VERSION ""

NS_ :

BS_:

BU_: WPC2 PSB SHVU_RR vHS_B2 FCS EMCU SLB GW_APSU GW_DLBCU RCM ARS CGW_CCU vDummy_HS_B GW_RLPSU ATS RLHV SGU PFSU GW_RRPSU ALBCU DSAU SWRC SHVU_FR RCS GW_DPSU BLTN_CAM SCM OHCL RWPC RRHV WPC HOD ASAU

BO_ 1096 SWRC_01_200ms: 8 SWRC
 SG_ SWRC_Crc1Val : 0|8@1+ (1,0) [0|0] ""  Vector__XXX
 SG_ SWRC_AlvCnt1Val : 12|4@1+ (1,0) [0|0] ""  CGW_CCU
 SG_ Audio_VcRecSwSta : 16|2@1+ (1,0) [0|0] ""  CGW_CCU
 SG_ Audio_BluetoothPhnClSwSta : 18|2@1+ (1,0) [0|0] ""  CGW_CCU
 SG_ Audio_BluetoothPhnHangUpSwSta : 20|2@1+ (1,0) [0|0] ""  CGW_CCU
 SG_ Audio_ModSwSta : 22|2@1+ (1,0) [0|0] ""  CGW_CCU
 SG_ Audio_MutSwSta : 24|2@1+ (1,0) [0|0] ""  CGW_CCU
 SG_ Audio_SeekDnSwSta : 26|2@1+ (1,0) [0|0] ""  CGW_CCU
 SG_ Audio_SeekUpSwSta : 28|2@1+ (1,0) [0|0] ""  CGW_CCU
 SG_ Audio_VolDnSwSta : 30|2@1+ (1,0) [0|0] ""  CGW_CCU
 SG_ Audio_VolUpSwSta : 32|2@1+ (1,0) [0|0] ""  CGW_CCU
 SG_ Cluster_ModeSwSta : 34|2@1+ (1,0) [0|0] ""  CGW_CCU
 SG_ Cluster_ScrlOkSwSta : 38|2@1+ (1,0) [0|0] ""  CGW_CCU
 SG_ Audio_CustomSwSta : 44|2@1+ (1,0) [0|0] ""  CGW_CCU
 SG_ Cluster_ModeCCW : 46|2@1+ (1,0) [0|0] ""  CGW_CCU
 SG_ Cluster_TripDnSwSta : 48|2@1+ (1,0) [0|0] ""  CGW_CCU
 SG_ Cluster_TripUpSwSta : 50|2@1+ (1,0) [0|0] ""  CGW_CCU
 SG_ Cluster_TripOkSwSta : 52|2@1+ (1,0) [0|0] ""  CGW_CCU
 SG_ SWRC_OpticalSwSnstvtSta : 54|2@1+ (1,0) [0|0] ""  CGW_CCU
 SG_ SWRC_RhOpticalSwSta : 56|4@1+ (1,0) [0|0] ""  CGW_CCU
 SG_ Audio_CustomSw3Sta : 8|2@1+ (1,0) [0|0] ""  CGW_CCU

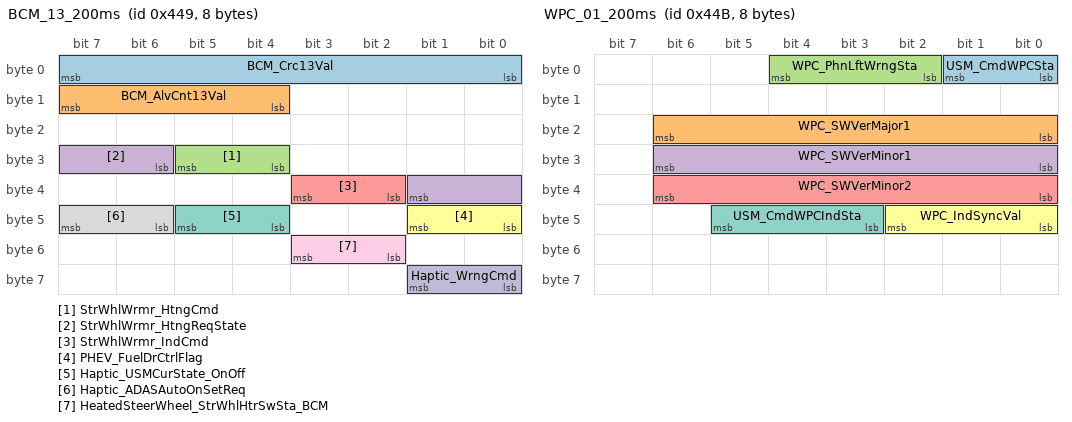
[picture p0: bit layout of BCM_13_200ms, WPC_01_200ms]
BO_ 1097 BCM_13_200ms: 8 CGW_CCU
 SG_ BCM_Crc13Val : 0|8@1+ (1,0) [0|0] ""  Vector__XXX
 SG_ BCM_AlvCnt13Val : 12|4@1+ (1,0) [0|0] ""  Vector__XXX
 SG_ StrWhlWrmr_HtngCmd : 28|2@1+ (1,0) [0|0] ""  Vector__XXX
 SG_ StrWhlWrmr_HtngReqState : 30|4@1+ (1,0) [0|0] ""  FCS
 SG_ StrWhlWrmr_IndCmd : 34|2@1+ (1,0) [0|0] ""  FCS
 SG_ PHEV_FuelDrCtrlFlag : 40|2@1+ (1,0) [0|0] ""  Vector__XXX
 SG_ Haptic_USMCurState_OnOff : 44|2@1+ (1,0) [0|0] ""  Vector__XXX
 SG_ Haptic_ADASAutoOnSetReq : 46|2@1+ (1,0) [0|0] ""  Vector__XXX
 SG_ HeatedSteerWheel_StrWhlHtrSwSta_BCM : 50|2@1+ (1,0) [0|0] ""  Vector__XXX
 SG_ Haptic_WrngCmd : 56|2@1+ (1,0) [0|0] ""  Vector__XXX

BO_ 1099 WPC_01_200ms: 8 WPC
 SG_ USM_CmdWPCSta : 0|2@1+ (1,0) [0|0] ""  CGW_CCU
 SG_ WPC_SWVerMajor1 : 16|7@1+ (1,0) [0|0] ""  CGW_CCU
 SG_ WPC_PhnLftWrngSta : 2|3@1+ (1,0) [0|0] ""  CGW_CCU
 SG_ WPC_SWVerMinor1 : 24|7@1+ (1,0) [0|0] ""  CGW_CCU
 SG_ WPC_SWVerMinor2 : 32|7@1+ (1,0) [0|0] ""  CGW_CCU
 SG_ WPC_IndSyncVal : 40|3@1+ (1,0) [0|0] ""  RWPC,WPC2
 SG_ USM_CmdWPCIndSta : 43|3@1+ (1,0) [0|0] ""  CGW_CCU,RWPC,WPC2

BO_ 1092 SMK_02_200ms: 8 CGW_CCU
 SG_ SMK_Crc2Val : 0|8@1+ (1,0) [0|0] ""  Vector__XXX
 SG_ SMK_AlvCnt2Val : 12|4@1+ (1,0) [0|0] ""  Vector__XXX
 SG_ SSB_StrtStpBtnSw1Sta : 16|2@1+ (1,0) [0|0] ""  Vector__XXX
 SG_ SSB_StrtStpBtnSw2Sta : 18|2@1+ (1,0) [0|0] ""  Vector__XXX
 SG_ SMK_TrmnlCtrlSta : 20|4@1+ (1,0) [0|0] ""  Vector__XXX
 SG_ SMK_AuthSta : 29|3@1+ (1,0) [0|0] ""  GW_APSU,GW_DPSU
 SG_ SMK_Ign1InSta : 32|2@1+ (1,0) [0|0] ""  Vector__XXX
 SG_ SMK_Ign1RlySta : 34|2@1+ (1,0) [0|0] ""  Vector__XXX
 SG_ SMK_Ign2InSta : 36|2@1+ (1,0) [0|0] ""  Vector__XXX
 SG_ SMK_Ign2RlySta : 38|2@1+ (1,0) [0|0] ""  Vector__XXX
 SG_ SMK_StrtFdbckSta : 40|2@1+ (1,0) [0|0] ""  Vector__XXX
 SG_ SMK_StrtrRlyOutSta : 42|2@1+ (1,0) [0|0] ""  Vector__XXX
 SG_ SMK_AccInSta : 44|2@1+ (1,0) [0|0] ""  Vector__XXX
 SG_ SMK_AccRlySta : 46|2@1+ (1,0) [0|0] ""  Vector__XXX
 SG_ SMK_CLUAccIndOnReq : 48|2@1+ (1,0) [0|0] ""  Vector__XXX
 SG_ SMK_VDModeActSta : 52|2@1+ (1,0) [0|0] ""  Vector__XXX
 SG_ SMK_SCULckUnlckSta : 54|2@1+ (1,0) [0|0] ""  Vector__XXX
 SG_ SMK_TlEngRunSta : 56|2@1+ (1,0) [0|0] ""  ASAU,ATS,DSAU,GW_APSU,GW_DPSU,RLHV,RRHV,SHVU_FR,SHVU_RR
 SG_ SMK_TlCrnkModSta : 58|2@1+ (1,0) [0|0] ""  ASAU,ATS,DSAU,GW_APSU,GW_DPSU,SCM
 SG_ SMK_RmtKeyEngRunSta : 60|2@1+ (1,0) [0|0] ""  Vector__XXX
 SG_ SMK_RmtKeyCrnkModSta : 62|2@1+ (1,0) [0|0] ""  Vector__XXX

BO_ 1093 SMK_06_200ms: 8 CGW_CCU
 SG_ SMK_Crc6Val : 0|8@1+ (1,0) [0|0] ""  Vector__XXX
 SG_ SMK_AlvCnt6Val : 12|4@1+ (1,0) [0|0] ""  Vector__XXX
 SG_ Lamp_HzrdBlnkngSta : 16|3@1+ (1,0) [0|0] ""  Vector__XXX
 SG_ RSPA_LearntSta : 19|2@1+ (1,0) [0|0] ""  Vector__XXX
 SG_ Lamp_SmrtWlcmLtOnReq : 21|2@1+ (1,0) [0|0] ""  Vector__XXX
 SG_ Fob_BattStaInfo : 24|2@1+ (1,0) [0|0] ""  Vector__XXX
 SG_ Fob_FoundDrvWlcmArea : 26|2@1+ (1,0) [0|0] ""  Vector__XXX
 SG_ Fob_FoundAsstWlcmArea : 28|2@1+ (1,0) [0|0] ""  Vector__XXX
 SG_ Fob_FoundExtrnlArea : 30|2@1+ (1,0) [0|0] ""  Vector__XXX
 SG_ Fob_FoundIntArea : 32|2@1+ (1,0) [0|0] ""  Vector__XXX
 SG_ Fob_LearntSta : 34|2@1+ (1,0) [0|0] ""  Vector__XXX
 SG_ RSPA_RFSigErrSta : 36|2@1+ (1,0) [0|0] ""  Vector__XXX
 SG_ RSPA_CanErrSta : 38|2@1+ (1,0) [0|0] ""  Vector__XXX
 SG_ LFAnt_FltSta : 40|2@1+ (1,0) [0|0] ""  Vector__XXX
 SG_ LFAnt_SrchSta : 42|2@1+ (1,0) [0|0] ""  RWPC,WPC,WPC2
 SG_ Auth_ISKLearnSta : 44|3@1+ (1,0) [0|0] ""  Vector__XXX
 SG_ RSPA_ModSta_SMK : 48|3@1+ (1,0) [0|0] ""  GW_DPSU
 SG_ RSPA_FobBattSta : 51|3@1+ (1,0) [0|0] ""  Vector__XXX
 SG_ Fob_BtnReleasedSta : 54|2@1+ (1,0) [0|0] ""  Vector__XXX
 SG_ USM_SmrtTrnkTlgtModSta : 56|3@1+ (1,0) [0|0] ""  Vector__XXX
 SG_ USM_WALModSta : 59|3@1+ (1,0) [0|0] ""  Vector__XXX
 SG_ Fob_FoundWlcmArea : 62|2@1+ (1,0) [0|0] ""  Vector__XXX

BO_ 1094 SLB_01_200ms: 8 SLB
 SG_ SLB_PlyBckSta : 0|2@1+ (1,0) [0|0] ""  Vector__XXX

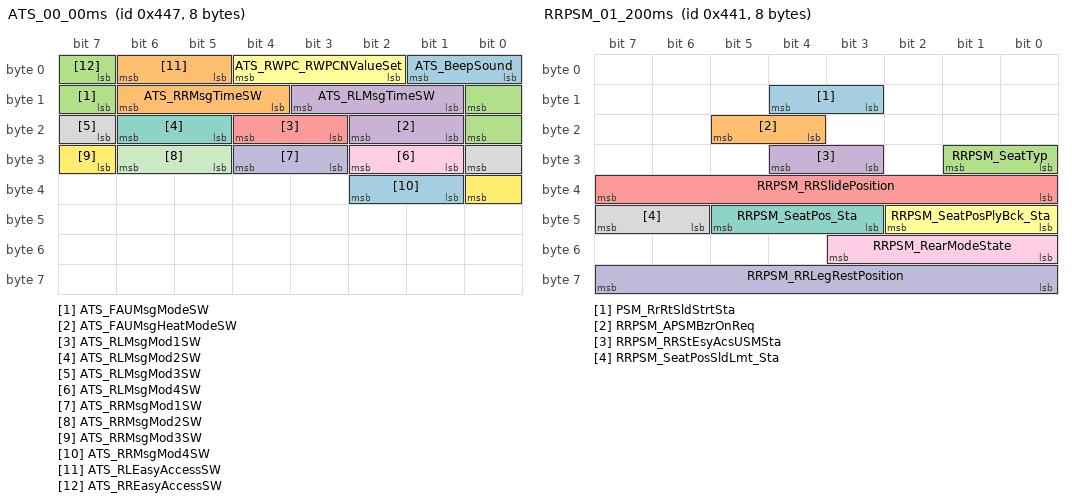
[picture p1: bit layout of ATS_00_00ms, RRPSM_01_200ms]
BO_ 1095 ATS_00_00ms: 8 ATS
 SG_ ATS_BeepSound : 0|2@1+ (1,0) [0|0] ""  CGW_CCU
 SG_ ATS_RRMsgTimeSW : 12|3@1+ (1,0) [0|0] ""  Vector__XXX
 SG_ ATS_FAUMsgModeSW : 15|2@1+ (1,0) [0|0] ""  ASAU
 SG_ ATS_FAUMsgHeatModeSW : 17|2@1+ (1,0) [0|0] ""  ASAU
 SG_ ATS_RLMsgMod1SW : 19|2@1+ (1,0) [0|0] ""  Vector__XXX
 SG_ ATS_RWPC_RWPCNValueSet : 2|3@1+ (1,0) [0|0] ""  RWPC
 SG_ ATS_RLMsgMod2SW : 21|2@1+ (1,0) [0|0] ""  Vector__XXX
 SG_ ATS_RLMsgMod3SW : 23|2@1+ (1,0) [0|0] ""  Vector__XXX
 SG_ ATS_RLMsgMod4SW : 25|2@1+ (1,0) [0|0] ""  Vector__XXX
 SG_ ATS_RRMsgMod1SW : 27|2@1+ (1,0) [0|0] ""  Vector__XXX
 SG_ ATS_RRMsgMod2SW : 29|2@1+ (1,0) [0|0] ""  Vector__XXX
 SG_ ATS_RRMsgMod3SW : 31|2@1+ (1,0) [0|0] ""  Vector__XXX
 SG_ ATS_RRMsgMod4SW : 33|2@1+ (1,0) [0|0] ""  Vector__XXX
 SG_ ATS_RLEasyAccessSW : 5|2@1+ (1,0) [0|0] ""  Vector__XXX
 SG_ ATS_RREasyAccessSW : 7|2@1+ (1,0) [0|0] ""  Vector__XXX
 SG_ ATS_RLMsgTimeSW : 9|3@1+ (1,0) [0|0] ""  Vector__XXX

BO_ 1089 RRPSM_01_200ms: 8 GW_RRPSU
 SG_ PSM_RrRtSldStrtSta : 11|2@1+ (1,0) [0|0] ""  ARS,GW_APSU,GW_DPSU,GW_RLPSU
 SG_ RRPSM_APSMBzrOnReq : 20|2@1+ (1,0) [0|0] ""  ATS,GW_APSU,GW_DPSU,GW_RLPSU
 SG_ RRPSM_SeatTyp : 24|2@1+ (1,0) [0|0] ""  GW_DPSU
 SG_ RRPSM_RRStEsyAcsUSMSta : 27|2@1+ (1,0) [0|0] ""  ATS,CGW_CCU,GW_DLBCU
 SG_ RRPSM_RRSlidePosition : 32|8@1+ (2,0) [0|0] ""  GW_APSU,GW_DPSU
 SG_ RRPSM_SeatPosPlyBck_Sta : 40|3@1+ (1,0) [0|0] ""  GW_RLPSU
 SG_ RRPSM_SeatPos_Sta : 43|3@1+ (1,0) [0|0] ""  GW_RLPSU
 SG_ RRPSM_SeatPosSldLmt_Sta : 46|2@1+ (1,0) [0|0] ""  CGW_CCU
 SG_ RRPSM_RearModeState : 48|4@1+ (1,0) [0|0] ""  ATS,CGW_CCU,GW_APSU,GW_DPSU,GW_RLPSU,OHCL
 SG_ RRPSM_RRLegRestPosition : 56|8@1+ (1,0) [0|0] ""  GW_APSU,GW_DPSU

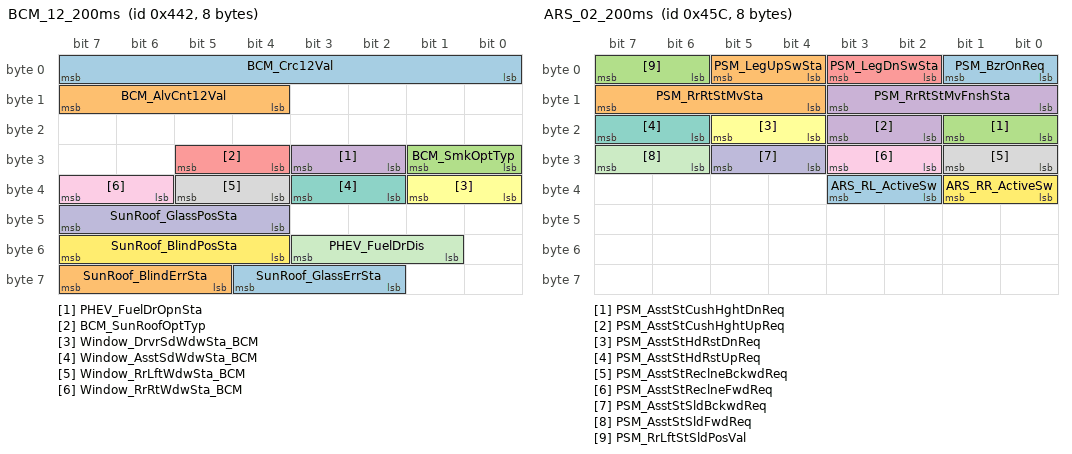
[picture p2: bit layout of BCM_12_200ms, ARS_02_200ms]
BO_ 1090 BCM_12_200ms: 8 CGW_CCU
 SG_ BCM_Crc12Val : 0|8@1+ (1,0) [0|0] ""  Vector__XXX
 SG_ BCM_AlvCnt12Val : 12|4@1+ (1,0) [0|0] ""  Vector__XXX
 SG_ BCM_SmkOptTyp : 24|2@1+ (1,0) [0|0] ""  RWPC,WPC,WPC2
 SG_ PHEV_FuelDrOpnSta : 26|2@1+ (1,0) [0|0] ""  Vector__XXX
 SG_ BCM_SunRoofOptTyp : 28|2@1+ (1,0) [0|0] ""  ATS
 SG_ Window_DrvrSdWdwSta_BCM : 32|2@1+ (1,0) [0|0] ""  Vector__XXX
 SG_ Window_AsstSdWdwSta_BCM : 34|2@1+ (1,0) [0|0] ""  Vector__XXX
 SG_ Window_RrLftWdwSta_BCM : 36|2@1+ (1,0) [0|0] ""  ATS
 SG_ Window_RrRtWdwSta_BCM : 38|2@1+ (1,0) [0|0] ""  ATS
 SG_ SunRoof_GlassPosSta : 44|4@1+ (1,0) [0|0] ""  Vector__XXX
 SG_ PHEV_FuelDrDis : 49|3@1+ (1,0) [0|0] ""  Vector__XXX
 SG_ SunRoof_BlindPosSta : 52|4@1+ (1,0) [0|0] ""  Vector__XXX
 SG_ SunRoof_GlassErrSta : 58|3@1+ (1,0) [0|0] ""  Vector__XXX
 SG_ SunRoof_BlindErrSta : 61|3@1+ (1,0) [0|0] ""  Vector__XXX

BO_ 1117 ARS_03_200ms: 8 ARS
 SG_ PSM_RrLftHdRstBckwdReq : 0|2@1+ (1,0) [0|0] ""  Vector__XXX
 SG_ PSM_RrLftStCushTiltUpReq : 10|2@1+ (1,0) [0|0] ""  Vector__XXX
 SG_ PSM_RrLftStShldrBckwdReq : 12|2@1+ (1,0) [0|0] ""  Vector__XXX
 SG_ PSM_RrLftStShldrFwdReq : 14|2@1+ (1,0) [0|0] ""  Vector__XXX
 SG_ PSM_RrLftStSldBckwdReq : 16|2@1+ (1,0) [0|0] ""  GW_RRPSU
 SG_ PSM_RrLftStSldFwdReq : 18|2@1+ (1,0) [0|0] ""  GW_RRPSU
 SG_ PSM_RrLftHdRstDnReq : 2|2@1+ (1,0) [0|0] ""  Vector__XXX
 SG_ PSM_RrRtStCushTiltDnReq : 20|2@1+ (1,0) [0|0] ""  Vector__XXX
 SG_ PSM_RrRtStCushTiltUpReq : 22|2@1+ (1,0) [0|0] ""  Vector__XXX
 SG_ PSM_RrRtStHdRstBckwdReq : 24|2@1+ (1,0) [0|0] ""  Vector__XXX
 SG_ PSM_RrRtStHdRstDnReq : 26|2@1+ (1,0) [0|0] ""  Vector__XXX
 SG_ PSM_RrRtStHdRstFwdReq : 28|2@1+ (1,0) [0|0] ""  Vector__XXX
 SG_ PSM_RrRtStHdRstUpReq : 30|2@1+ (1,0) [0|0] ""  Vector__XXX
 SG_ PSM_RrRtStLegSpprtBckwdReq : 32|2@1+ (1,0) [0|0] ""  Vector__XXX
 SG_ PSM_RrRtStLegSpprtDnReq : 34|2@1+ (1,0) [0|0] ""  Vector__XXX
 SG_ PSM_RrRtStLegSpprtFwdReq : 36|2@1+ (1,0) [0|0] ""  Vector__XXX
 SG_ PSM_RrRtStLegSpprtUpReq : 38|2@1+ (1,0) [0|0] ""  Vector__XXX
 SG_ PSM_RrLftHdRstFwdReq : 4|2@1+ (1,0) [0|0] ""  Vector__XXX
 SG_ PSM_RrRtStShldrBckwdReq : 40|2@1+ (1,0) [0|0] ""  Vector__XXX
 SG_ PSM_RrRtStShldrFwdReq : 42|2@1+ (1,0) [0|0] ""  Vector__XXX
 SG_ PSM_RrRtStSldBckwdReq : 44|2@1+ (1,0) [0|0] ""  GW_RRPSU
 SG_ PSM_RrRtStSldFwdReq : 46|2@1+ (1,0) [0|0] ""  GW_RRPSU
 SG_ PSM_StSldBckwdArsSta : 48|2@1+ (1,0) [0|0] ""  Vector__XXX
 SG_ PSM_StSldFwdArsSta : 50|2@1+ (1,0) [0|0] ""  Vector__XXX
 SG_ ARS_RrHeaterSW : 52|2@1+ (1,0) [0|0] ""  GW_RRPSU,RRHV
 SG_ ARS_RlHeaterSW : 54|2@1+ (1,0) [0|0] ""  GW_RLPSU,RLHV
 SG_ ARS_RrVentSW : 56|2@1+ (1,0) [0|0] ""  GW_RRPSU,RRHV
 SG_ ARS_RlVentSW : 58|2@1+ (1,0) [0|0] ""  GW_RLPSU,RLHV
 SG_ PSM_RrLftHdRstUpReq : 6|2@1+ (1,0) [0|0] ""  Vector__XXX
 SG_ PSM_RrLftStCushTiltDnReq : 8|2@1+ (1,0) [0|0] ""  Vector__XXX

BO_ 1116 ARS_02_200ms: 8 ARS
 SG_ PSM_BzrOnReq : 0|2@1+ (1,0) [0|0] ""  Vector__XXX
 SG_ PSM_RrRtStMvSta : 12|4@1+ (1,0) [0|0] ""  Vector__XXX
 SG_ PSM_AsstStCushHghtDnReq : 16|2@1+ (1,0) [0|0] ""  Vector__XXX
 SG_ PSM_AsstStCushHghtUpReq : 18|2@1+ (1,0) [0|0] ""  Vector__XXX
 SG_ PSM_LegDnSwSta : 2|2@1+ (1,0) [0|0] ""  Vector__XXX
 SG_ PSM_AsstStHdRstDnReq : 20|2@1+ (1,0) [0|0] ""  Vector__XXX
 SG_ PSM_AsstStHdRstUpReq : 22|2@1+ (1,0) [0|0] ""  Vector__XXX
 SG_ PSM_AsstStReclneBckwdReq : 24|2@1+ (1,0) [0|0] ""  Vector__XXX
 SG_ PSM_AsstStReclneFwdReq : 26|2@1+ (1,0) [0|0] ""  Vector__XXX
 SG_ PSM_AsstStSldBckwdReq : 28|2@1+ (1,0) [0|0] ""  Vector__XXX
 SG_ PSM_AsstStSldFwdReq : 30|2@1+ (1,0) [0|0] ""  Vector__XXX
 SG_ ARS_RR_ActiveSw : 32|2@1+ (1,0) [0|0] ""  GW_DLBCU
 SG_ ARS_RL_ActiveSw : 34|2@1+ (1,0) [0|0] ""  GW_DLBCU
 SG_ PSM_LegUpSwSta : 4|2@1+ (1,0) [0|0] ""  Vector__XXX
 SG_ PSM_RrLftStSldPosVal : 6|2@1+ (1,0) [0|0] ""  Vector__XXX
 SG_ PSM_RrRtStMvFnshSta : 8|4@1+ (1,0) [0|0] ""  Vector__XXX

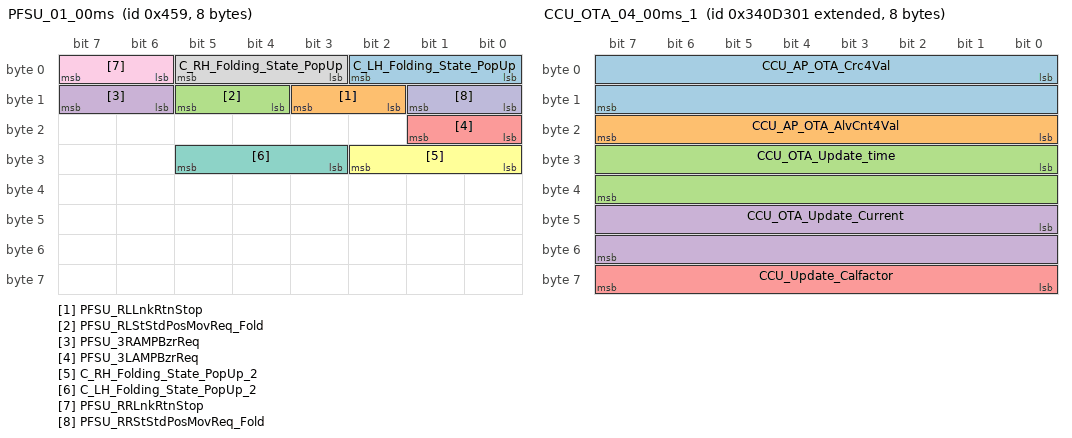
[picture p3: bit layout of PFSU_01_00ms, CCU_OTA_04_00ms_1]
BO_ 1113 PFSU_01_00ms: 8 PFSU
 SG_ C_LH_Folding_State_PopUp : 0|3@1+ (1,0) [0|0] ""  CGW_CCU,GW_APSU
 SG_ PFSU_RLLnkRtnStop : 10|2@1+ (1,0) [0|0] ""  GW_RLPSU
 SG_ PFSU_RLStStdPosMovReq_Fold : 12|2@1+ (1,0) [0|0] ""  GW_RLPSU
 SG_ PFSU_3RAMPBzrReq : 14|2@1+ (1,0) [0|0] ""  CGW_CCU
 SG_ PFSU_3LAMPBzrReq : 16|2@1+ (1,0) [0|0] ""  CGW_CCU
 SG_ C_RH_Folding_State_PopUp_2 : 24|3@1+ (1,0) [0|0] ""  CGW_CCU
 SG_ C_LH_Folding_State_PopUp_2 : 27|3@1+ (1,0) [0|0] ""  CGW_CCU
 SG_ C_RH_Folding_State_PopUp : 3|3@1+ (1,0) [0|0] ""  CGW_CCU,GW_APSU
 SG_ PFSU_RRLnkRtnStop : 6|2@1+ (1,0) [0|0] ""  GW_RRPSU
 SG_ PFSU_RRStStdPosMovReq_Fold : 8|2@1+ (1,0) [0|0] ""  GW_RRPSU

BO_ 2202063617 CCU_OTA_04_00ms_1: 8 CGW_CCU
 SG_ CCU_AP_OTA_Crc4Val : 0|16@1+ (1,0) [0|0] ""  vDummy_HS_B
 SG_ CCU_AP_OTA_AlvCnt4Val : 16|8@1+ (1,0) [0|0] ""  vDummy_HS_B
 SG_ CCU_OTA_Update_time : 24|16@1+ (1,0) [0|0] ""  Vector__XXX
 SG_ CCU_OTA_Update_Current : 40|16@1+ (1,0) [0|0] ""  Vector__XXX
 SG_ CCU_Update_Calfactor : 56|8@1+ (1,0) [0|0] ""  Vector__XXX

BO_ 1115 ARS_01_200ms: 8 ARS
 SG_ ARS_OnOffSta : 0|2@1+ (1,0) [0|0] ""  Vector__XXX
 SG_ ARS_RrCurtainSwSta : 10|2@1+ (1,0) [0|0] ""  CGW_CCU
 SG_ ARS_RrLftStRetModSwSta : 12|2@1+ (1,0) [0|0] ""  Vector__XXX
 SG_ ARS_RrLftStRlxModSwSta : 14|2@1+ (1,0) [0|0] ""  Vector__XXX
 SG_ ARS_RtMonModSwSta : 16|2@1+ (1,0) [0|0] ""  Vector__XXX
 SG_ ARS_RtReadModSwSta : 18|2@1+ (1,0) [0|0] ""  Vector__XXX
 SG_ ARS_ReclneBckwdSwSta : 2|2@1+ (1,0) [0|0] ""  Vector__XXX
 SG_ ARS_RtRetModSwSta : 20|2@1+ (1,0) [0|0] ""  Vector__XXX
 SG_ ARS_RtRlxModSwSta : 22|2@1+ (1,0) [0|0] ""  Vector__XXX
 SG_ ARS_SwLkSta : 24|2@1+ (1,0) [0|0] ""  CGW_CCU
 SG_ ARS_WalkInFrSwSta : 26|2@1+ (1,0) [0|0] ""  Vector__XXX
 SG_ ARS_WalkInRrSwSta : 28|2@1+ (1,0) [0|0] ""  Vector__XXX
 SG_ Lamp_RrRtPrsLmpReq : 30|2@1+ (1,0) [0|0] ""  Vector__XXX
 SG_ PSM_ApsmPlyBckRrerReq : 32|2@1+ (1,0) [0|0] ""  Vector__XXX
 SG_ ARS_ReclneFwdSwSta : 4|2@1+ (1,0) [0|0] ""  Vector__XXX
 SG_ ARS_RlxFrSwSta : 6|2@1+ (1,0) [0|0] ""  Vector__XXX
 SG_ ARS_RlxRrSwSta : 8|2@1+ (1,0) [0|0] ""  Vector__XXX

BO_ 1111 PFSU_02_200ms: 8 PFSU
 SG_ C_LH_Folding_Position : 0|3@1+ (1,0) [0|0] ""  CGW_CCU,GW_APSU,GW_RLPSU
 SG_ PFSU_RH_ReclMtrPos : 10|2@1+ (1,0) [0|0] ""  Vector__XXX
 SG_ PFSU_RL_Folding_SW : 16|2@1+ (1,0) [0|0] ""  GW_RLPSU
 SG_ PFSU_RR_Folding_SW : 18|2@1+ (1,0) [0|0] ""  GW_RLPSU,GW_RRPSU
 SG_ PFSU_RL_Unfolding_SW : 20|2@1+ (1,0) [0|0] ""  GW_RLPSU
 SG_ PFSU_RR_Unfolding_SW : 22|2@1+ (1,0) [0|0] ""  GW_RLPSU,GW_RRPSU
 SG_ C_RH_Folding_Position : 3|3@1+ (1,0) [0|0] ""  CGW_CCU,GW_APSU,GW_RLPSU,GW_RRPSU
 SG_ PFSU_RR_FoldingDis : 32|2@1+ (1,0) [0|0] ""  Vector__XXX
 SG_ PFSU_RR_UnfoldingDis : 34|2@1+ (1,0) [0|0] ""  Vector__XXX
 SG_ PFSU_RL_FoldingDis : 36|2@1+ (1,0) [0|0] ""  Vector__XXX
 SG_ PFSU_RL_UnfoldingDis : 38|2@1+ (1,0) [0|0] ""  Vector__XXX
 SG_ PFSU_RR_HrstFoldingDis : 40|2@1+ (1,0) [0|0] ""  CGW_CCU
 SG_ PFSU_RL_HrstFoldingDis : 42|2@1+ (1,0) [0|0] ""  CGW_CCU
 SG_ PFSU_RR_SlideFwdDis : 44|2@1+ (1,0) [0|0] ""  Vector__XXX
 SG_ PFSU_RR_SlidBwdDis : 46|2@1+ (1,0) [0|0] ""  Vector__XXX
 SG_ PFSU_RL_SlideFwdDis : 48|2@1+ (1,0) [0|0] ""  Vector__XXX
 SG_ PFSU_RL_SlideBwdDis : 50|2@1+ (1,0) [0|0] ""  Vector__XXX
 SG_ PFSU_RRAutoRlxEnable : 52|2@1+ (1,0) [0|0] ""  GW_RRPSU
 SG_ PFSU_Opt : 56|2@1+ (1,0) [0|0] ""  CGW_CCU
 SG_ PFSU_RLAutoRlxEnable : 60|2@1+ (1,0) [0|0] ""  GW_RLPSU
 SG_ PFSU_LH_ReclMtrPos : 8|2@1+ (1,0) [0|0] ""  Vector__XXX

BO_ 1105 FCS_01_200ms: 8 FCS
 SG_ FCS_FrLftStClrSwSta : 0|2@1+ (1,0) [0|0] ""  GW_APSU,SHVU_FR
 SG_ HeatedSteerWheel_SwSta : 10|2@1+ (1,0) [0|0] ""  CGW_CCU
 SG_ FCS_DrvDrAtClsSwSta : 12|2@1+ (1,0) [0|0] ""  CGW_CCU,SHVU_FR
 SG_ FCS_AstDrAtClsSwSta : 14|2@1+ (1,0) [0|0] ""  CGW_CCU,SHVU_FR
 SG_ FCS_DrvModeSwSta : 16|2@1+ (1,0) [0|0] ""  CGW_CCU,SHVU_FR
 SG_ FCS_PDWSwSta : 18|2@1+ (1,0) [0|0] ""  CGW_CCU
 SG_ FCS_FrLftStHtrSwSta : 2|2@1+ (1,0) [0|0] ""  GW_APSU,SHVU_FR
 SG_ FCS_Beep1Sound : 20|2@1+ (1,0) [0|0] ""  CGW_CCU
 SG_ FCS_LockTrayMsgDisp : 22|4@1+ (1,0) [0|0] ""  ATS
 SG_ FCS_LockTrayStatDisp : 26|3@1+ (1,0) [0|0] ""  ATS
 SG_ FCS_LockTrayPwNoDisp : 29|3@1+ (1,0) [0|0] ""  ATS
 SG_ FCS_LockTrayTxtPopupReq : 32|2@1+ (1,0) [0|0] ""  ATS
 SG_ FCS_LockTrayOSD : 34|3@1+ (1,0) [0|0] ""  ATS
 SG_ FCS_FrDrvArmrestHeatedLvl : 37|2@1+ (1,0) [0|0] ""  CGW_CCU
 SG_ FCS_FrAstArmrestHeatedLvl : 39|2@1+ (1,0) [0|0] ""  CGW_CCU
 SG_ FCS_FrRtStClrSwSta : 4|2@1+ (1,0) [0|0] ""  GW_APSU,SHVU_FR
 SG_ FCS_FrArmrestHeatedTyp : 41|2@1+ (1,0) [0|0] ""  CGW_CCU
 SG_ FCS_RrArmrestHeatedTyp : 43|2@1+ (1,0) [0|0] ""  CGW_CCU
 SG_ FCS_RrLhArmrestHeatedLvl : 45|2@1+ (1,0) [0|0] ""  CGW_CCU
 SG_ FCS_DrvTerrModeDirSwSta : 47|2@1+ (1,0) [0|0] ""  CGW_CCU
 SG_ FCS_DrvTerrModeSwSta : 49|2@1+ (1,0) [0|0] ""  CGW_CCU
 SG_ CF_FCS_4wdLocking : 51|2@1+ (1,0) [0|0] ""  CGW_CCU
 SG_ FCS_FrDrvArmrestHeated : 53|2@1+ (1,0) [0|0] ""  CGW_CCU
 SG_ FCS_FrAstArmrestHeated : 55|2@1+ (1,0) [0|0] ""  CGW_CCU
 SG_ FCS_RrLhArmrestHeated : 57|2@1+ (1,0) [0|0] ""  CGW_CCU
 SG_ FCS_RrRhArmrestHeated : 59|2@1+ (1,0) [0|0] ""  CGW_CCU
 SG_ FCS_FrRtStHtrSwSta : 6|2@1+ (1,0) [0|0] ""  GW_APSU,SHVU_FR
 SG_ FCS_RrRhArmrestHeatedLvl : 61|2@1+ (1,0) [0|0] ""  CGW_CCU
 SG_ FCS_RrCurtainSwSta : 8|2@1+ (1,0) [0|0] ""  Vector__XXX

BO_ 1107 RR_SHVU_01_200ms: 8 RRHV
 SG_ RR_SHVU_SeatOptSta : 0|3@1+ (1,0) [0|0] ""  ASAU,ATS,CGW_CCU
 SG_ RR_SHVU_SeatHtOperSta : 3|4@1+ (1,0) [0|0] ""  ASAU,ATS,CGW_CCU,FCS

BO_ 1134 APSU_03_200ms: 8 GW_APSU
 SG_ APSU_AstStSldFwdDis : 0|2@1+ (1,0) [0|0] ""  CGW_CCU
 SG_ APSU_AstStTiltDnDis : 10|2@1+ (1,0) [0|0] ""  CGW_CCU
 SG_ APSU_AstStHghtUpDis : 12|2@1+ (1,0) [0|0] ""  CGW_CCU
 SG_ APSU_AstStHghtDnDis : 14|2@1+ (1,0) [0|0] ""  CGW_CCU
 SG_ APSU_AstStLegUpDis : 16|2@1+ (1,0) [0|0] ""  Vector__XXX
 SG_ APSU_AstStLegtDnDis : 18|2@1+ (1,0) [0|0] ""  Vector__XXX
 SG_ APSU_AstStSldBckwdDis : 2|2@1+ (1,0) [0|0] ""  CGW_CCU
 SG_ APSU_AstStRlxTiltUpDis : 20|2@1+ (1,0) [0|0] ""  CGW_CCU
 SG_ APSU_AstStRlxTiltDnDis : 22|2@1+ (1,0) [0|0] ""  CGW_CCU
 SG_ APSU_AstStCushExtBckwdDis : 24|2@1+ (1,0) [0|0] ""  Vector__XXX
 SG_ APSU_AstStCushExtFwdDis : 26|2@1+ (1,0) [0|0] ""  Vector__XXX
 SG_ APSU_AstStLmbrDefDis : 32|2@1+ (1,0) [0|0] ""  ALBCU
 SG_ APSU_AstStLmbrLoDis : 34|2@1+ (1,0) [0|0] ""  ALBCU
 SG_ APSU_AstStLmbrMdlDis : 36|2@1+ (1,0) [0|0] ""  ALBCU
 SG_ APSU_AstStLmbrUpDis : 38|2@1+ (1,0) [0|0] ""  ALBCU
 SG_ APSU_AstStReclneFwdDis : 4|2@1+ (1,0) [0|0] ""  CGW_CCU
 SG_ APSU_LmbrSigSrcTyp : 44|2@1+ (1,0) [0|0] ""  ALBCU
 SG_ APSU_APSUOpt : 46|2@1+ (1,0) [0|0] ""  Vector__XXX
 SG_ APSU_AstStReclneBckwdDis : 6|2@1+ (1,0) [0|0] ""  CGW_CCU
 SG_ APSU_AstStTiltUpDis : 8|2@1+ (1,0) [0|0] ""  CGW_CCU

BO_ 1132 DLBCU_03_200ms: 8 GW_DLBCU
 SG_ DLBCU_CushInfDis : 0|2@1+ (1,0) [0|0] ""  CGW_CCU,GW_DPSU
 SG_ DLBCU_CushDefDis : 2|2@1+ (1,0) [0|0] ""  CGW_CCU,GW_DPSU

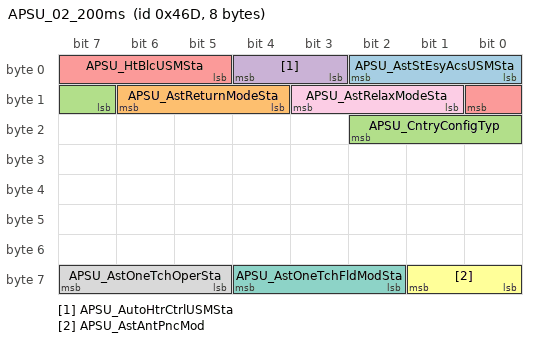
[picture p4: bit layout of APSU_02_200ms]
BO_ 1133 APSU_02_200ms: 8 GW_APSU
 SG_ APSU_AstStEsyAcsUSMSta : 0|3@1+ (1,0) [0|0] ""  ALBCU,CGW_CCU
 SG_ APSU_AstReturnModeSta : 12|3@1+ (1,0) [0|0] ""  CGW_CCU
 SG_ APSU_CntryConfigTyp : 15|4@1+ (1,0) [0|0] ""  Vector__XXX
 SG_ APSU_AutoHtrCtrlUSMSta : 3|2@1+ (1,0) [0|0] ""  Vector__XXX
 SG_ APSU_HtBlcUSMSta : 5|4@1+ (1,0) [0|0] ""  Vector__XXX
 SG_ APSU_AstAntPncMod : 56|2@1+ (1,0) [0|0] ""  Vector__XXX
 SG_ APSU_AstOneTchFldModSta : 58|3@1+ (1,0) [0|0] ""  Vector__XXX
 SG_ APSU_AstOneTchOperSta : 61|3@1+ (1,0) [0|0] ""  Vector__XXX
 SG_ APSU_AstRelaxModeSta : 9|3@1+ (1,0) [0|0] ""  CGW_CCU

BO_TX_BU_ 1107 : RRHV,SHVU_RR,GW_RRPSU,SHVU_FR;
CM_ BO_ 1133 "[PE] Periodic and On Event";
CM_ SG_ 1133 APSU_AstStEsyAcsUSMSta "USM_MovingValue";
CM_ SG_ 1133 APSU_CntryConfigTyp "APSU_ContryConfigurationType";
CM_ SG_ 1133 APSU_AutoHtrCtrlUSMSta "Auto Down Seat Heater (USM Setting)";
CM_ SG_ 1133 APSU_HtBlcUSMSta "Hetaer Balance Assistant USM R vaule";
CM_ BO_ 1134 "[PE] Periodic and On Event";
CM_ SG_ 1134 APSU_AstStSldFwdDis "APSU_AssistSlideForwardDisplay";
CM_ SG_ 1134 APSU_AstStTiltDnDis "APSU_AssistTiltDownSwitchDisplay";
CM_ SG_ 1134 APSU_AstStHghtUpDis "APSU_AssistHeightUpSwitchDisplay";
CM_ SG_ 1134 APSU_AstStHghtDnDis "APSU_AssistHeightDownSwitchDisplay";
CM_ SG_ 1134 APSU_AstStLegUpDis "APSU_AssistLegUpSwitchDisplay";
CM_ SG_ 1134 APSU_AstStLegtDnDis "APSU_AssistLegDownSwitchDisplay";
CM_ SG_ 1134 APSU_AstStSldBckwdDis "APSU_AssistSlideBackwardSwitchDisplay";
CM_ SG_ 1134 APSU_AstStRlxTiltUpDis "APSU_AssistRelaxTiltUpSwitchDisplay";
CM_ SG_ 1134 APSU_AstStRlxTiltDnDis "APSU_AssistRelaxTiltDownSwitchDisplay";
CM_ SG_ 1134 APSU_AstStCushExtBckwdDis "APSU_AssistCushionExtendedBackwardSwitchDisplay";
CM_ SG_ 1134 APSU_AstStCushExtFwdDis "APSU_AssistCushionExtendedForwardSwitchDisplay";
CM_ SG_ 1134 APSU_AstStLmbrDefDis "APSU_AssistLumbarDeFlateSwitchDisplay";
CM_ SG_ 1134 APSU_AstStLmbrLoDis "APSU_AssistLumbarLowSwitchDisplay";
CM_ SG_ 1134 APSU_AstStLmbrMdlDis "APSU_AssistLumbarMiddleSwitchDisplay";
CM_ SG_ 1134 APSU_AstStLmbrUpDis "APSU_AssistLumbarUpSwitchDisplay";
CM_ SG_ 1134 APSU_AstStReclneFwdDis "APSU_AssistSeatReclineForwardSwitchDisplay";
CM_ SG_ 1134 APSU_LmbrSigSrcTyp "Lumbar Switch Signal Source(TX)";
CM_ SG_ 1134 APSU_AstStReclneBckwdDis "APSU_AssistSeatReclineBackwardSwitchDisplay";
CM_ SG_ 1134 APSU_AstStTiltUpDis "APSU_AssistTiltUpSwitchDisplay";
CM_ BO_ 1115 "[PE] Periodic and On Event";
CM_ SG_ 1115 ARS_OnOffSta "ARS_OnOffStatus";
CM_ SG_ 1115 ARS_RrCurtainSwSta "ARS_RearCurtainSwitchArsStatus";
CM_ SG_ 1115 ARS_RrLftStRetModSwSta "ARS_RearLeftSeatReturnModeSwitchStatus";
CM_ SG_ 1115 ARS_RrLftStRlxModSwSta "ARS_RearLeftSeatRelaxModeSwitchStatus";
CM_ SG_ 1115 ARS_RtMonModSwSta "ARS_RightMonitorModeSwitchStatus";
CM_ SG_ 1115 ARS_RtReadModSwSta "ARS_RightReadingModeSwitchStatus";
CM_ SG_ 1115 ARS_ReclneBckwdSwSta "ARS_ReclineBackwardSwitchStatus";
CM_ SG_ 1115 ARS_RtRetModSwSta "ARS_RightReturnModeSwitchStatus";
CM_ SG_ 1115 ARS_RtRlxModSwSta "ARS_RightRelaxModeSwitchStatus";
CM_ SG_ 1115 ARS_SwLkSta "ARS_SwitchLockStatus";
CM_ SG_ 1115 ARS_WalkInFrSwSta "ARS_WalkInFrontSwitchStatus";
CM_ SG_ 1115 ARS_WalkInRrSwSta "ARS_WalkInRearSwitchStatus";
CM_ SG_ 1115 Lamp_RrRtPrsLmpReq "Lamp_RearRightPersonalLampRequest";
CM_ SG_ 1115 PSM_ApsmPlyBckRrerReq "PSM_ApsmPlayBackRrerRequest";
CM_ SG_ 1115 ARS_ReclneFwdSwSta "ARS_ReclineForwardSwitchStatus";
CM_ SG_ 1115 ARS_RlxFrSwSta "ARS_RelaxFrontSwitchStatus";
CM_ SG_ 1115 ARS_RlxRrSwSta "ARS_RelaxRearSwitchStatus";
CM_ BO_ 1116 "[PE] Periodic and On Event";
CM_ SG_ 1116 PSM_BzrOnReq "PSM_BuzzerOnRequest";
CM_ SG_ 1116 PSM_RrRtStMvSta "PSM_RearRightSeatMovingStatus";
CM_ SG_ 1116 PSM_AsstStCushHghtDnReq "PSM_AssistSeatCushionHeightDownRequest";
CM_ SG_ 1116 PSM_AsstStCushHghtUpReq "PSM_AssistSeatCushionHeightUpRequest";
CM_ SG_ 1116 PSM_LegDnSwSta "PSM_LegDownSwitchStatus";
CM_ SG_ 1116 PSM_AsstStHdRstDnReq "PSM_AssistSeatHeadrestSwitchDownRequest";
CM_ SG_ 1116 PSM_AsstStHdRstUpReq "PSM_AssistSeatHeadrestUpRequest";
CM_ SG_ 1116 PSM_AsstStReclneBckwdReq "PSM_AssistSeatReclineBackwardRequest";
CM_ SG_ 1116 PSM_AsstStReclneFwdReq "PSM_AssistSeatReclineForwardRequest";
CM_ SG_ 1116 PSM_AsstStSldBckwdReq "PSM_AssistSeatSlideBackwardRequest";
CM_ SG_ 1116 PSM_AsstStSldFwdReq "PSM_AssistSeatSlideForwardRequest";
CM_ SG_ 1116 ARS_RR_ActiveSw "ARS_RR_ActiveSw";
CM_ SG_ 1116 ARS_RL_ActiveSw "ARS_RL_ActiveSw";
CM_ SG_ 1116 PSM_LegUpSwSta "PSM_LegUpSwitchStatus";
CM_ SG_ 1116 PSM_RrLftStSldPosVal "PSM_RearLeftSeatSlidingPositionValue";
CM_ SG_ 1116 PSM_RrRtStMvFnshSta "PSM_RearRightSeatMovingFinishStatus";
CM_ BO_ 1117 "[PE] Periodic and On Event";
CM_ SG_ 1117 PSM_RrLftHdRstBckwdReq "PSM_RearLeftHeadrestBackwardRequest";
CM_ SG_ 1117 PSM_RrLftStCushTiltUpReq "PSM_RearLeftSeatCushionTiltUpRequest";
CM_ SG_ 1117 PSM_RrLftStShldrBckwdReq "PSM_RearLeftSeatShoulderBackwardRequest";
CM_ SG_ 1117 PSM_RrLftStShldrFwdReq "PSM_RearLeftSeatShoulderForwardRequest";
CM_ SG_ 1117 PSM_RrLftStSldBckwdReq "PSM_RearLeftSeatSliderBackwardRequest";
CM_ SG_ 1117 PSM_RrLftStSldFwdReq "PSM_RearLeftSeatSliderForwardRequest";
CM_ SG_ 1117 PSM_RrLftHdRstDnReq "PSM_RearLeftHeadrestDownRequest";
CM_ SG_ 1117 PSM_RrRtStCushTiltDnReq "PSM_RearRightSeatCushionTiltDownRequest";
CM_ SG_ 1117 PSM_RrRtStCushTiltUpReq "PSM_RearRightSeatCushionTiltUpRequest";
CM_ SG_ 1117 PSM_RrRtStHdRstBckwdReq "PSM_RearRightSeatHeadrestBackwardRequest";
CM_ SG_ 1117 PSM_RrRtStHdRstDnReq "PSM_RearRightSeatHeadrestDownRequest";
CM_ SG_ 1117 PSM_RrRtStHdRstFwdReq "PSM_RearRightSeatHeadrestForwardRequest";
CM_ SG_ 1117 PSM_RrRtStHdRstUpReq "PSM_RearRightSeatHeadrestUpRequest";
CM_ SG_ 1117 PSM_RrRtStLegSpprtBckwdReq "PSM_RearRightSeatLegSupportBackwardRequest";
CM_ SG_ 1117 PSM_RrRtStLegSpprtDnReq "PSM_RearRightSeatLegSupportDownRequest";
CM_ SG_ 1117 PSM_RrRtStLegSpprtFwdReq "PSM_RearRightSeatLegSupportForwardReqeust";
CM_ SG_ 1117 PSM_RrRtStLegSpprtUpReq "PSM_RearRightSeatLegSupportUpRequest";
CM_ SG_ 1117 PSM_RrLftHdRstFwdReq "PSM_RearLeftHeadrestForwardRequest";
CM_ SG_ 1117 PSM_RrRtStShldrBckwdReq "PSM_RearRightSeatShoulderBackwardRequest";
CM_ SG_ 1117 PSM_RrRtStShldrFwdReq "PSM_RearRightSeatShoulderForwardRequest";
CM_ SG_ 1117 PSM_RrRtStSldBckwdReq "PSM_RearRightSeatSlideBackwardRequest";
CM_ SG_ 1117 PSM_RrRtStSldFwdReq "PSM_RearRightSeatSlideForwardRequest";
CM_ SG_ 1117 PSM_StSldBckwdArsSta "PSM_SeatSlideBackwardArsStatus";
CM_ SG_ 1117 PSM_StSldFwdArsSta "PSM_SeatSlideForwardArsStatus";
CM_ SG_ 1117 ARS_RrHeaterSW "Rear Right Seat Heater Switch";
CM_ SG_ 1117 ARS_RlHeaterSW "Rear Left Seat Heater Switch";
CM_ SG_ 1117 ARS_RrVentSW "Rear Right Seat Vent Switch";
CM_ SG_ 1117 ARS_RlVentSW "Rear Left Seat Vent Switch";
CM_ SG_ 1117 PSM_RrLftHdRstUpReq "PSM_RearLeftHeadrestUpRequest";
CM_ SG_ 1117 PSM_RrLftStCushTiltDnReq "PSM_RearLeftSeatCushionTiltDownRequest";
CM_ BO_ 1095 "[EC] On Event and On Change";
CM_ SG_ 1095 ATS_BeepSound "ATS to AMP BEEP sound trigger";
CM_ SG_ 1095 ATS_RRMsgTimeSW "Rear Right Massage Time Button";
CM_ SG_ 1095 ATS_FAUMsgModeSW "Rear Right Foot Massage Mode Button";
CM_ SG_ 1095 ATS_FAUMsgHeatModeSW "Rear Right Foot Massage Heat Mode Button";
CM_ SG_ 1095 ATS_RLMsgMod1SW "Rear Left Massage Mode 1 Button";
CM_ SG_ 1095 ATS_RWPC_RWPCNValueSet "Rear Wireless Phone Charger ON/OFF Request";
CM_ SG_ 1095 ATS_RLMsgMod2SW "Rear Left Massage Mode 2 Button";
CM_ SG_ 1095 ATS_RLMsgMod3SW "Rear Left Massage Mode 3 Button";
CM_ SG_ 1095 ATS_RLMsgMod4SW "Rear Left Massage Mode 4 Button";
CM_ SG_ 1095 ATS_RRMsgMod1SW "Rear Right Massage Mode 1 Button";
CM_ SG_ 1095 ATS_RRMsgMod2SW "Rear Right Massage Mode 2 Button";
CM_ SG_ 1095 ATS_RRMsgMod3SW "Rear Right Massage Mode 3 Button";
CM_ SG_ 1095 ATS_RRMsgMod4SW "Rear Right Massage Mode 4 Button";
CM_ SG_ 1095 ATS_RLEasyAccessSW "ATS touch command for seat easy access (For Rear Left)";
CM_ SG_ 1095 ATS_RREasyAccessSW "ATS touch command for seat easy access (For Rear Right)";
CM_ SG_ 1095 ATS_RLMsgTimeSW "Rear Left Massage Time Button";
CM_ BO_ 1090 "[PE] Periodic and On Event";
CM_ SG_ 1090 BCM_Crc12Val "BCM_CyclicRedundancyCheck12Value";
CM_ SG_ 1090 BCM_AlvCnt12Val "BCM_AliveCounter12Value";
CM_ SG_ 1090 BCM_SmkOptTyp "BCM_SmkOptionType ##2G##BCM - BCMmsg17 - C_SMKOption";
CM_ SG_ 1090 PHEV_FuelDrOpnSta "PHEV_FuelDoorOpenStatus ##2G##BCM - BCMmsg20 - C_FuelDrSw";
CM_ SG_ 1090 BCM_SunRoofOptTyp "BCM_SunRoofOptionType";
CM_ SG_ 1090 Window_DrvrSdWdwSta_BCM "Window_DriverSideWindowStatus ##2G##BCM - BCMmsg22 - C_DrvWindowOpenState";
CM_ SG_ 1090 Window_AsstSdWdwSta_BCM "Window_AssistantSideWindowStatus ##2G##BCM - BCMmsg22 - C_AstWindowOpenState";
CM_ SG_ 1090 Window_RrLftWdwSta_BCM "Window_RearLeftWindowStatus ##2G##BCM - BCMmsg22 - C_RLWindowOpenState";
CM_ SG_ 1090 Window_RrRtWdwSta_BCM "Window_RearRightPowerWindowStatus ##2G##BCM - BCMmsg22 - C_RRWindowOpenState";
CM_ SG_ 1090 SunRoof_GlassPosSta "SunRoof_GlassPositionStatus";
CM_ SG_ 1090 PHEV_FuelDrDis "PHEV_FuelDoorDisplay ##2G##BCM - BCMmsg19 - C_PHEVFuelDrDisp";
CM_ SG_ 1090 SunRoof_BlindPosSta "SunRoof_BlindPositionStatus";
CM_ SG_ 1090 SunRoof_GlassErrSta "SunRoof_GlassErrorStatus";
CM_ SG_ 1090 SunRoof_BlindErrSta "SunRoof_BlindErrorStatus";
CM_ BO_ 1097 "[PE] Periodic and On Event";
CM_ SG_ 1097 BCM_Crc13Val "BCM_CyclicRedundancyCheck13Value";
CM_ SG_ 1097 BCM_AlvCnt13Val "BCM_AliveCounter13Value";
CM_ SG_ 1097 PHEV_FuelDrCtrlFlag "PHEV_FuelDoorOpenStatus ##2G##BCM - BCMmsg20 - C_FuelDrSw";
CM_ SG_ 1097 HeatedSteerWheel_StrWhlHtrSwSta_BCM "HeatedSteerWheel_SwitchStatus ##2G##BCM - BCMmsg24 - C_StrgWhlHeatedState";
CM_ BO_ 2202063617 "[EC] On Event and On Change";
CM_ SG_ 2202063617 CCU_AP_OTA_Crc4Val "CCU_AP_OTA_CyclicRedundancyCheck4Value";
CM_ SG_ 2202063617 CCU_AP_OTA_AlvCnt4Val "CCU_AP_OTA_AliveCounter4Value";
CM_ SG_ 2202063617 CCU_OTA_Update_time "¾÷µ¥ÀÌÆ® ¿¹»ó½Ã°£";
CM_ SG_ 2202063617 CCU_OTA_Update_Current "Current consumption expected";
CM_ SG_ 2202063617 CCU_Update_Calfactor "Determination SOC setting";
CM_ BO_ 1132 "[PE] Periodic and On Event";
CM_ SG_ 1132 DLBCU_CushInfDis "DLBCU_CushionInflationDisplay";
CM_ SG_ 1132 DLBCU_CushDefDis "DLBCU_CushionDeflationDisplay";
CM_ BO_ 1105 "[PE] Periodic and On Event";
CM_ SG_ 1105 FCS_FrLftStClrSwSta "FCS_FrontLeftSeatCoolerSwitchStatus";
CM_ SG_ 1105 HeatedSteerWheel_SwSta "HeatedSteerWheel_SwitchStatus";
CM_ SG_ 1105 FCS_FrLftStHtrSwSta "FCS_FrontLeftSeatHeaterSwitchStatus";
CM_ SG_ 1105 FCS_LockTrayMsgDisp "FCS_LockTrayMessageDisplacement";
CM_ SG_ 1105 FCS_LockTrayStatDisp "FCS_LockTrayStateDisplacement";
CM_ SG_ 1105 FCS_LockTrayPwNoDisp "FCS_LockTrayPasswordNumberDisplacement";
CM_ SG_ 1105 FCS_LockTrayTxtPopupReq "FCS_LockTrayTextPopupRequest";
CM_ SG_ 1105 FCS_LockTrayOSD "FCS_LockTrayOnScreenDisplacement";
CM_ SG_ 1105 FCS_FrRtStClrSwSta "FCS_FrontRightSeatCoolerSwitchStatus";
CM_ SG_ 1105 FCS_FrArmrestHeatedTyp "FCS_FrArmrestHeatedTyp";
CM_ SG_ 1105 FCS_RrArmrestHeatedTyp "FCS_RrArmrestHeatedTyp";
CM_ SG_ 1105 FCS_DrvTerrModeDirSwSta "Drive/Terrain mode switch transition direction signal";
CM_ SG_ 1105 FCS_DrvTerrModeSwSta "Drive/Terrain Mode Switch Convert Status";
CM_ SG_ 1105 CF_FCS_4wdLocking "4wd Locking On/Off Signal";
CM_ SG_ 1105 FCS_FrRtStHtrSwSta "FCS_FrontRightSeatHeaterSwitchStatus";
CM_ SG_ 1105 FCS_RrCurtainSwSta "FCS_RearCurtainSwitchFcsStatus";
CM_ BO_ 1113 "[EC] On Event and On Change";
CM_ SG_ 1113 C_LH_Folding_State_PopUp "3rd LH seat Moving Finish / Mode-Fail signal";
CM_ SG_ 1113 PFSU_3RAMPBzrReq "3rd Right SEAT IMS Buzzer Request for AMP or Inner Speaker";
CM_ SG_ 1113 PFSU_3LAMPBzrReq "3rd Left SEAT IMS Buzzer Request for AMP or Inner Speaker";
CM_ SG_ 1113 C_RH_Folding_State_PopUp_2 "AVNT OSD PopUp For 3rd Seat Inoperable condition";
CM_ SG_ 1113 C_LH_Folding_State_PopUp_2 "AVNT OSD PopUp For 3rd Seat Inoperable condition";
CM_ SG_ 1113 C_RH_Folding_State_PopUp "3rd RH seat Moving Finish / Mode-Fail signal";
CM_ BO_ 1111 "[PE] Periodic and On Event";
CM_ SG_ 1111 PFSU_RH_ReclMtrPos "PFSU Rear Right Recliner Motor Posion Information";
CM_ SG_ 1111 PFSU_RL_Folding_SW "PFSU Rear Left Folding Switch";
CM_ SG_ 1111 PFSU_RR_Folding_SW "PFSU Rear Right Folding Switch";
CM_ SG_ 1111 PFSU_RL_Unfolding_SW "PFSU Rear Left Unfolding Switch";
CM_ SG_ 1111 PFSU_RR_Unfolding_SW "PFSU Rear Right Unfolding Switch";
CM_ SG_ 1111 PFSU_RR_FoldingDis "Third LH PSU Folding moving state: Folding";
CM_ SG_ 1111 PFSU_RR_UnfoldingDis "Third LH PSU Unfolding moving state: Unfolding";
CM_ SG_ 1111 PFSU_RL_FoldingDis "Third RH PSU Folding moving state: Folding";
CM_ SG_ 1111 PFSU_RL_UnfoldingDis "Third RH PSU Unfolding moving state: Unfolding";
CM_ SG_ 1111 PFSU_RR_HrstFoldingDis "Third RH H/rest Folding moving state: H/rest folding";
CM_ SG_ 1111 PFSU_RL_HrstFoldingDis "Third LH H/rest Folding moving state: H/rest folding";
CM_ SG_ 1111 PFSU_RR_SlideFwdDis "Third LH PSU Recliner FWD moving state";
CM_ SG_ 1111 PFSU_RR_SlidBwdDis "Third LH PSU Recliner BWD moving state";
CM_ SG_ 1111 PFSU_RL_SlideFwdDis "Third RH PSU Recliner FWD moving state";
CM_ SG_ 1111 PFSU_RL_SlideBwdDis "Third RH PSU Recliner BWD moving state";
CM_ SG_ 1111 PFSU_Opt "PFSU Option Information";
CM_ SG_ 1111 PFSU_LH_ReclMtrPos "PFSU Rear Left Recliner Motor Posion Information";
CM_ BO_ 1089 "[PE] Periodic and On Event";
CM_ SG_ 1089 PSM_RrRtSldStrtSta "PSM_RearRightSlidingStartStatus";
CM_ SG_ 1089 RRPSM_APSMBzrOnReq "APSM buzzer on command";
CM_ SG_ 1089 RRPSM_RRStEsyAcsUSMSta "USM_MovingValue";
CM_ SG_ 1089 RRPSM_SeatPosPlyBck_Sta "RRPSM_SeatPositionPlayBack_State";
CM_ SG_ 1089 RRPSM_SeatPos_Sta "RRPSM_SeatPosition_State";
CM_ SG_ 1089 RRPSM_SeatPosSldLmt_Sta "RRPSM_SeatPositionSlideLimitState";
CM_ BO_ 1107 "[PE] Periodic and On Event";
CM_ SG_ 1107 RR_SHVU_SeatOptSta "Rear RH Seat Heater/Vent option info";
CM_ SG_ 1107 RR_SHVU_SeatHtOperSta "Rear RH Seat Heater/Vent current operation state";
CM_ BO_ 1094 "[PE] Periodic and On Event";
CM_ SG_ 1094 SLB_PlyBckSta "SLB_PlayBackStatus";
CM_ BO_ 1092 "[PE] Periodic and On Event";
CM_ SG_ 1092 SMK_Crc2Val "SMK_CyclicRedundancyCheck2Value";
CM_ SG_ 1092 SMK_AlvCnt2Val "SMK_AliveCounter2Value";
CM_ SG_ 1092 SSB_StrtStpBtnSw1Sta "SSB_StartStopButtonSwitch1Status ##2G##SMK - SMKmsg19 - C_SSBSW1";
CM_ SG_ 1092 SSB_StrtStpBtnSw2Sta "SSB_StartStopButtonSwitch2Status ##2G##SMK - SMKmsg19 - C_SSBSW2";
CM_ SG_ 1092 SMK_TrmnlCtrlSta "SMK_TerminalControlStatus ##2G##SMK - SMKmsg19 - C_TerminalControlState";
CM_ SG_ 1092 SMK_AuthSta "SMK_AuthentificationStatus ##2G##SMK - SMKmsg18 - C_AuthState";
CM_ SG_ 1092 SMK_Ign1InSta "SMK_Ign1InputStatus ##2G##SMK - SMKmsg19 - C_Ign1SMK";
CM_ SG_ 1092 SMK_Ign1RlySta "SMK_Ign1RelayStatus ##2G##SMK - SMKmsg19 - C_Ign1RelayState";
CM_ SG_ 1092 SMK_Ign2InSta "SMK_Ign2InputStatus ##2G##SMK - SMKmsg19 - C_Ign2SMK";
CM_ SG_ 1092 SMK_Ign2RlySta "SMK_Ign2RelayStatus ##2G##SMK - SMKmsg19 - C_Ign2RelayState";
CM_ SG_ 1092 SMK_StrtFdbckSta "SMK_StartFeedbackStatus ##2G##SMK - SMKmsg19 - C_StartFeedback";
CM_ SG_ 1092 SMK_StrtrRlyOutSta "SMK_StarterRelayOutputStatus ##2G##SMK - SMKmsg18 - C_StarterRlyState";
CM_ SG_ 1092 SMK_AccInSta "SMK_AccInputStatus ##2G##SMK - SMKmsg19 - C_AccSMK";
CM_ SG_ 1092 SMK_AccRlySta "SMK_AccRelayStatus ##2G##SMK - SMKmsg19 - C_AccRelayStatus";
CM_ SG_ 1092 SMK_CLUAccIndOnReq "SMK_ClusterACCIndicatorOnRequest ##2G##SMK - SMKmsg19 - C_AccINDforCLU";
CM_ SG_ 1092 SMK_VDModeActSta "SMK_VirtualDriverModeActState";
CM_ SG_ 1092 SMK_SCULckUnlckSta "SCU Lock/Unlock Status";
CM_ SG_ 1092 SMK_TlEngRunSta "SMK_TeleEngineRunStatus ##2G##SMK - SMKmsg18 - C_SMKTeleEngineRunning";
CM_ SG_ 1092 SMK_TlCrnkModSta "SMK_TeleCrankingModeStatus ##2G##SMK - SMKmsg18 - C_SMKTeleCrankingState";
CM_ SG_ 1092 SMK_RmtKeyEngRunSta "SMK_RemoteKeyEngineRunStatus";
CM_ SG_ 1092 SMK_RmtKeyCrnkModSta "SMK_RemoteKeyCrankingModeStatus";
CM_ BO_ 1093 "[PE] Periodic and On Event";
CM_ SG_ 1093 SMK_Crc6Val "SMK_CyclicRedundancyCheck6Value";
CM_ SG_ 1093 SMK_AlvCnt6Val "SMK_AliveCounter6Value";
CM_ SG_ 1093 Lamp_HzrdBlnkngSta "Lamp_HazardBlinkingStatus ##2G##SMK - SMKmsg17 - C_HazardFromSMK";
CM_ SG_ 1093 Lamp_SmrtWlcmLtOnReq "Lamp_SmartWelcomeLightOnRequest ##2G##SMK - SMKmsg17 - C_WlightOn";
CM_ SG_ 1093 Fob_BattStaInfo "Fob_BatteryStatusInformation ##2G##SMK - SMKmsg17 - C_FOBBatteryStatusInfo";
CM_ SG_ 1093 Fob_FoundDrvWlcmArea "Fob_FoundDriverWelcomeArea ##2G##SMK - SMKmsg17 - C_WelcomeFobFoundDrv";
CM_ SG_ 1093 Fob_FoundAsstWlcmArea "Fob_FoundAssistWelcomeArea ##2G##SMK - SMKmsg17 - C_WelcomeFobFoundAst";
CM_ SG_ 1093 Fob_FoundExtrnlArea "Fob_FoundExternalArea ##2G##SMK - SMKmsg18 - C_ExtFobPos";
CM_ SG_ 1093 Fob_FoundIntArea "Fob_FoundInternalArea ##2G##SMK - SMKmsg18 - C_IntFobPos";
CM_ SG_ 1093 Fob_LearntSta "Fob_LearntStatus ##2G##SMK - SMKmsg18 - C_FobLearntState";
CM_ SG_ 1093 RSPA_RFSigErrSta "RSPA_RFSignalErrorState";
CM_ SG_ 1093 RSPA_CanErrSta "RSPA_CANErrorState";
CM_ SG_ 1093 LFAnt_FltSta "LFAntenna_FaultSatus ##2G##SMK - SMKmsg18 - C_LFANTState";
CM_ SG_ 1093 LFAnt_SrchSta "LFAntenna_SearchingStatus ##2G##SMK - SMKmsg19 - C_LFSearchingOn";
CM_ SG_ 1093 Auth_ISKLearnSta "Fob_FoundAssistWelcomeArea ##2G##SMK - SMKmsg178 - C_IBUISKLearnState";
CM_ SG_ 1093 RSPA_ModSta_SMK "RSPA_ModeStatus ##2G##SMK - SMKmsg18 - C_SMKRSPAMode";
CM_ SG_ 1093 RSPA_FobBattSta "RSPA_FobBatteryStatus ##2G##SMK - SMKmsg18 - C_FobBATState";
CM_ SG_ 1093 USM_SmrtTrnkTlgtModSta "USM_SmartTunkTailgateModeStatus ##2G##SMK - SMKmsg20 - C_HfreeTrunkTgRValue";
CM_ SG_ 1093 USM_WALModSta "USM_WalkAwayLockModeStatus ##2G##SMK - SMKmsg20 - C_WALRValue";
CM_ SG_ 1093 Fob_FoundWlcmArea "Fob_FoundWlcmArea ##2G##SMK - SMKmsg17 -C_FobFoundWlcmArea";
CM_ BO_ 1096 "[PE] Periodic and On Event";
CM_ SG_ 1096 SWRC_Crc1Val "SWRC_CyclicRedundancyCheck1Value";
CM_ SG_ 1096 SWRC_AlvCnt1Val "SWRC_AliveCounter1Value";
CM_ SG_ 1096 Audio_VcRecSwSta "Audio_VoiceReconitionSwitchStatus";
CM_ SG_ 1096 Audio_BluetoothPhnClSwSta "Audio_BluetoothPhoneCallSwitchStatus";
CM_ SG_ 1096 Audio_BluetoothPhnHangUpSwSta "Audio_BluetoothPhoneHangUpSwitchStatus";
CM_ SG_ 1096 Audio_ModSwSta "Audio_ModeSwitchStatus";
CM_ SG_ 1096 Audio_MutSwSta "Audio_MuteSwitchStatus";
CM_ SG_ 1096 Audio_SeekDnSwSta "Audio_SeekDownSwitchStatus";
CM_ SG_ 1096 Audio_SeekUpSwSta "Audio_SeekUpSwitchStatus";
CM_ SG_ 1096 Audio_VolDnSwSta "Audio_VolumeDownSwitchStatus";
CM_ SG_ 1096 Audio_VolUpSwSta "Audio_VolumeUpSwitchStatus";
CM_ SG_ 1096 Cluster_ModeSwSta "Cluster_ModeSwitchStatus";
CM_ SG_ 1096 Cluster_ScrlOkSwSta "Cluster_ScrollOkSwitchStatus";
CM_ SG_ 1096 Audio_CustomSwSta "Audio_CustomSwitchStatus";
CM_ SG_ 1096 Cluster_ModeCCW "Cluster Menu Control (Back Key)";
CM_ SG_ 1096 Cluster_TripDnSwSta "Cluster_TripDnSwSta";
CM_ SG_ 1096 Cluster_TripUpSwSta "Cluster Menu Control (Up)";
CM_ SG_ 1096 Cluster_TripOkSwSta "Cluster_TripOkSwSta";
CM_ SG_ 1096 SWRC_OpticalSwSnstvtSta "SWRC_OpticalSwitchSensitivityStatus";
CM_ SG_ 1096 SWRC_RhOpticalSwSta "SWRC_RhOpticalSwitchStatus";
CM_ SG_ 1096 Audio_CustomSw3Sta "Audio_CustomSwitch 3rd Status";
CM_ BO_ 1099 "[PE] Periodic and On Event";
CM_ SG_ 1099 USM_CmdWPCSta "USM_CommandWPCStatus";
CM_ SG_ 1099 WPC_SWVerMajor1 "First Word(ASCII) in WPC S/W Ver";
CM_ SG_ 1099 WPC_PhnLftWrngSta "WPC_PhoneLeftWarningStatus";
CM_ SG_ 1099 WPC_SWVerMinor1 "Second Word(ASCII) in WPC S/W Ver";
CM_ SG_ 1099 WPC_SWVerMinor2 "Third Word(ASCII) in WPC S/W Ver";
BA_DEF_ BO_ "DiagState" ENUM "No","Yes" ;
BA_DEF_ BO_ "DiagResponse" ENUM "No","Yes" ;
BA_DEF_ BO_ "DiagRequest" ENUM "No","Yes" ;
BA_DEF_ BO_ "TpMessage" ENUM "No","Yes" ;
BA_DEF_ BO_ "UsrMsgIDSforwardDeviation" INT 0 100 ;
BA_DEF_ BO_ "UsrMsgIDSbackwardDeviation" INT 50 1000 ;
BA_DEF_ "BusType" STRING ;
BA_DEF_ "DBName" STRING ;
BA_DEF_ "Baudrate" INT 50000 1000000 ;
BA_DEF_ "GenEnvVarEndingDsp" STRING ;
BA_DEF_ "GenEnvVarEndingSnd" STRING ;
BA_DEF_ "GenEnvVarPrefix" STRING ;
BA_DEF_ "GenNWMApBusSleep" STRING ;
BA_DEF_ "GenNWMApCanNormal" STRING ;
BA_DEF_ "GenNWMApCanOff" STRING ;
BA_DEF_ "GenNWMApCanOn" STRING ;
BA_DEF_ "GenNWMApCanSleep" STRING ;
BA_DEF_ "GenNWMApCanWakeUp" STRING ;
BA_DEF_ "GenNWMGotoMode_Awake" STRING ;
BA_DEF_ "GenNWMGotoMode_BusSleep" STRING ;
BA_DEF_ "GenNWMSleepTime" INT 1375 1650 ;
BA_DEF_ "GenNWMTalkNM" STRING ;
BA_DEF_ "Manufacturer" STRING ;
BA_DEF_ "NmBaseAddress" HEX 0 2047 ;
BA_DEF_ "NmMessageCount" INT 0 128 ;
BA_DEF_ "NmType" STRING ;
BA_DEF_ "SamplePointMax" INT 50 85 ;
BA_DEF_ "SamplePointMin" INT 55 85 ;
BA_DEF_ "SyncJumpWidthMax" INT 1 8 ;
BA_DEF_ "SyncJumpWidthMin" INT 1 4 ;
BA_DEF_ "VersionDay" INT 1 31 ;
BA_DEF_ "VersionMonth" INT 1 12 ;
BA_DEF_ "VersionNumber" INT 0 999999 ;
BA_DEF_ "VersionNumberInternal" INT 0 9999 ;
BA_DEF_ "VersionWeek" INT 1 53 ;
BA_DEF_ "VersionYear" INT 0 9999 ;
BA_DEF_ BU_ "NmStationAddress" HEX 0 127 ;
BA_DEF_ BU_ "NmNode" ENUM "No","Yes" ;
BA_DEF_ BU_ "GenNodSleepTime" INT 1375 1650 ;
BA_DEF_ BU_ "ILUsed" ENUM "No","Yes" ;
BA_DEF_ BU_ "NmCAN" INT 1 2 ;
BA_DEF_ BU_ "NodeLayerModules" STRING ;
BA_DEF_ BU_ "NWM_Knoten" ENUM "No","Yes" ;
BA_DEF_ BO_ "GenMsgCycleTime" INT 0 2000 ;
BA_DEF_ BO_ "GenMsgStartDelayTime" INT 0 2000 ;
BA_DEF_ BO_ "GenMsgSendType" ENUM "Cyclic","NoMsgSendType" ;
BA_DEF_ BO_ "GenMsgCycleTimeFast" INT 0 500 ;
BA_DEF_ BO_ "GenMsgDelayTime" INT 0 20 ;
BA_DEF_ BO_ "GenMsgILSupport" ENUM "No","Yes" ;
BA_DEF_ BO_ "GenMsgNrOfRepetition" INT 0 3 ;
BA_DEF_ BO_ "NmMessage" ENUM "No","Yes" ;
BA_DEF_ BO_ "NWM-Botschaft" ENUM "No","Yes" ;
BA_DEF_ BO_ "TpTxIndex" INT 0 65535 ;
BA_DEF_ BO_ "VFrameFormat" ENUM "StandardCAN","ExtendedCAN","reserved","reserved","reserved","reserved","reserved","reserved","reserved","reserved","reserved","reserved","reserved","reserved","StandardCAN_FD","ExtendedCAN_FD" ;
BA_DEF_ SG_ "UserSigValidity" ENUM "B+","ACC","IG","IG1","IG2","IG3","IG1 or IG2","IG1 or IG3","Undef" ;
BA_DEF_ SG_ "TimeoutValue" STRING ;
BA_DEF_ SG_ "UsrSigPurpose" ENUM "Undef","FN","DIAG","DIAG(Req)","DIAG(Res)","DIAG(Phy)","DEV","CCP(Req)","CCP(Res)","NM","TP" ;
BA_DEF_ SG_ "GenSigStartValue" INT 0 1215752192 ;
BA_DEF_ SG_ "NetworkRequest" ENUM "Yes","No" ;
BA_DEF_ SG_ "NetworkRequestHoldingTime" INT 0 65535 ;
BA_DEF_ SG_ "Description" STRING ;
BA_DEF_ SG_ "Version" STRING ;
BA_DEF_ SG_ "GenSigEnvVarType" ENUM "Int","Float","Undef" ;
BA_DEF_ SG_ "GenSigSendType" ENUM "Cyclic","OnWrite","OnWriteWithRepetition","OnChange","OnChangeWithRepetition","IfActive","IfActiveWithRepetition","NoSigSendType","OnChangeAndIfActive","OnChangeAndIfActiveWithRepetition" ;
BA_DEF_ SG_ "GwSigLatencyTime" INT 0 65536 ;
BA_DEF_ SG_ "GwSigMissingSourceType" ENUM "Undef","OldValue","DefaultValue","InitialValue" ;
BA_DEF_ SG_ "NWM-WakeupAllowed" ENUM "<n.a.>" ;
BA_DEF_ SG_ "RoutingFactor" INT 1 1215752192 ;
BA_DEF_REL_ BU_SG_REL_ "GenSigTimeoutTime" INT 0 7000 ;
BA_DEF_DEF_ "DiagState" "No" ;
BA_DEF_DEF_ "DiagResponse" "No" ;
BA_DEF_DEF_ "DiagRequest" "No" ;
BA_DEF_DEF_ "TpMessage" "No" ;
BA_DEF_DEF_ "UsrMsgIDSforwardDeviation" 10 ;
BA_DEF_DEF_ "UsrMsgIDSbackwardDeviation" 100 ;
BA_DEF_DEF_ "BusType" "CAN" ;
BA_DEF_DEF_ "DBName" "" ;
BA_DEF_DEF_ "Baudrate" 500000 ;
BA_DEF_DEF_ "GenEnvVarEndingDsp" "Dsp_" ;
BA_DEF_DEF_ "GenEnvVarEndingSnd" "_" ;
BA_DEF_DEF_ "GenEnvVarPrefix" "Env" ;
BA_DEF_DEF_ "GenNWMApBusSleep" "AppNmCanBusSleep()" ;
BA_DEF_DEF_ "GenNWMApCanNormal" "AppNmCanNormal()" ;
BA_DEF_DEF_ "GenNWMApCanOff" "ApplCanOffline()" ;
BA_DEF_DEF_ "GenNWMApCanOn" "ApplCanOnline()" ;
BA_DEF_DEF_ "GenNWMApCanSleep" "ApplNmCanSleep()" ;
BA_DEF_DEF_ "GenNWMApCanWakeUp" "ApplCanWakeUp()" ;
BA_DEF_DEF_ "GenNWMGotoMode_Awake" "GotoMode_Awake()" ;
BA_DEF_DEF_ "GenNWMGotoMode_BusSleep" "GotoMode_BusSleep()" ;
BA_DEF_DEF_ "GenNWMSleepTime" 1500 ;
BA_DEF_DEF_ "GenNWMTalkNM" "TalkNM()" ;
BA_DEF_DEF_ "Manufacturer" "HMC" ;
BA_DEF_DEF_ "NmBaseAddress" 1280 ;
BA_DEF_DEF_ "NmMessageCount" 128 ;
BA_DEF_DEF_ "NmType" "Vector" ;
BA_DEF_DEF_ "SamplePointMax" 80 ;
BA_DEF_DEF_ "SamplePointMin" 80 ;
BA_DEF_DEF_ "SyncJumpWidthMax" 3 ;
BA_DEF_DEF_ "SyncJumpWidthMin" 2 ;
BA_DEF_DEF_ "VersionDay" 1 ;
BA_DEF_DEF_ "VersionMonth" 1 ;
BA_DEF_DEF_ "VersionNumber" 0 ;
BA_DEF_DEF_ "VersionNumberInternal" 0 ;
BA_DEF_DEF_ "VersionWeek" 1 ;
BA_DEF_DEF_ "VersionYear" 0 ;
BA_DEF_DEF_ "NmStationAddress" 0 ;
BA_DEF_DEF_ "NmNode" "Yes" ;
BA_DEF_DEF_ "GenNodSleepTime" 1500 ;
BA_DEF_DEF_ "ILUsed" "Yes" ;
BA_DEF_DEF_ "NmCAN" 1 ;
BA_DEF_DEF_ "NodeLayerModules" "oseknm01.dll,CANoeILNLVector.dll" ;
BA_DEF_DEF_ "NWM_Knoten" "Yes" ;
BA_DEF_DEF_ "GenMsgCycleTime" 200 ;
BA_DEF_DEF_ "GenMsgStartDelayTime" 0 ;
BA_DEF_DEF_ "GenMsgSendType" "NoMsgSendType" ;
BA_DEF_DEF_ "GenMsgCycleTimeFast" 40 ;
BA_DEF_DEF_ "GenMsgDelayTime" 20 ;
BA_DEF_DEF_ "GenMsgILSupport" "Yes" ;
BA_DEF_DEF_ "GenMsgNrOfRepetition" 3 ;
BA_DEF_DEF_ "NmMessage" "No" ;
BA_DEF_DEF_ "NWM-Botschaft" "No" ;
BA_DEF_DEF_ "TpTxIndex" 0 ;
BA_DEF_DEF_ "VFrameFormat" "StandardCAN" ;
BA_DEF_DEF_ "UserSigValidity" "IG" ;
BA_DEF_DEF_ "TimeoutValue" "" ;
BA_DEF_DEF_ "UsrSigPurpose" "FN" ;
BA_DEF_DEF_ "GenSigStartValue" 0 ;
BA_DEF_DEF_ "NetworkRequest" "No" ;
BA_DEF_DEF_ "NetworkRequestHoldingTime" 0 ;
BA_DEF_DEF_ "Description" "" ;
BA_DEF_DEF_ "Version" "" ;
BA_DEF_DEF_ "GenSigEnvVarType" "Undef" ;
BA_DEF_DEF_ "GenSigSendType" "NoSigSendType" ;
BA_DEF_DEF_ "GwSigLatencyTime" 40 ;
BA_DEF_DEF_ "GwSigMissingSourceType" "Undef" ;
BA_DEF_DEF_ "NWM-WakeupAllowed" "<n.a.>" ;
BA_DEF_DEF_ "RoutingFactor" 1 ;
BA_DEF_DEF_REL_ "GenSigTimeoutTime" 500 ;
BA_ "DBName" "HS_B2";
BA_ "VersionYear" 1;
BA_ "VersionNumber" 240201;
BA_ "NmStationAddress" BU_ CGW_CCU 112;
BA_ "NmStationAddress" BU_ OHCL 84;
BA_ "NmStationAddress" BU_ PSB 65;
BA_ "NmStationAddress" BU_ ATS 80;
BA_ "NmStationAddress" BU_ GW_APSU 49;
BA_ "NmStationAddress" BU_ GW_RLPSU 28;
BA_ "NmStationAddress" BU_ GW_RRPSU 29;
BA_ "NmStationAddress" BU_ GW_DPSU 56;
BA_ "NmStationAddress" BU_ RCM 61;
BA_ "NmStationAddress" BU_ SWRC 8;
BA_ "NmStationAddress" BU_ HOD 74;
BA_ "NmStationAddress" BU_ FCS 33;
BA_ "NmStationAddress" BU_ SHVU_FR 42;
BA_ "NmStationAddress" BU_ ALBCU 68;
BA_ "GenMsgSendType" BO_ 1133 0;
BA_ "GenSigSendType" SG_ 1133 APSU_AstStEsyAcsUSMSta 4;
BA_ "UserSigValidity" SG_ 1133 APSU_AstStEsyAcsUSMSta 0;
BA_REL_ "GenSigTimeoutTime" BU_SG_REL_ ALBCU SG_ 1133 APSU_AstStEsyAcsUSMSta 1500;
BA_REL_ "GenSigTimeoutTime" BU_SG_REL_ CGW_CCU SG_ 1133 APSU_AstStEsyAcsUSMSta 1500;
BA_ "NetworkRequest" SG_ 1133 APSU_AstStEsyAcsUSMSta 0;
BA_ "NetworkRequestHoldingTime" SG_ 1133 APSU_AstStEsyAcsUSMSta 5000;
BA_ "Version" SG_ 1133 APSU_AstStEsyAcsUSMSta "21.07.06";
BA_ "Description" SG_ 1133 APSU_AstReturnModeSta "APSU_AssistReturnModeState";
BA_ "GenSigSendType" SG_ 1133 APSU_AstReturnModeSta 4;
BA_ "UserSigValidity" SG_ 1133 APSU_AstReturnModeSta 0;
BA_REL_ "GenSigTimeoutTime" BU_SG_REL_ CGW_CCU SG_ 1133 APSU_AstReturnModeSta 1500;
BA_ "NetworkRequest" SG_ 1133 APSU_AstReturnModeSta 0;
BA_ "NetworkRequestHoldingTime" SG_ 1133 APSU_AstReturnModeSta 5000;
BA_ "Version" SG_ 1133 APSU_AstReturnModeSta "19.12.00";
BA_ "GenSigSendType" SG_ 1133 APSU_CntryConfigTyp 4;
BA_ "UserSigValidity" SG_ 1133 APSU_CntryConfigTyp 0;
BA_ "NetworkRequest" SG_ 1133 APSU_CntryConfigTyp 0;
BA_ "NetworkRequestHoldingTime" SG_ 1133 APSU_CntryConfigTyp 5000;
BA_ "Version" SG_ 1133 APSU_CntryConfigTyp "21.07.06";
BA_ "Description" SG_ 1133 APSU_AutoHtrCtrlUSMSta "-(Old)C_AstAutoHeatRValue";
BA_ "GenSigSendType" SG_ 1133 APSU_AutoHtrCtrlUSMSta 4;
BA_ "UserSigValidity" SG_ 1133 APSU_AutoHtrCtrlUSMSta 0;
BA_ "NetworkRequest" SG_ 1133 APSU_AutoHtrCtrlUSMSta 0;
BA_ "NetworkRequestHoldingTime" SG_ 1133 APSU_AutoHtrCtrlUSMSta 5000;
BA_ "Version" SG_ 1133 APSU_AutoHtrCtrlUSMSta "18.02.01";
BA_ "Description" SG_ 1133 APSU_HtBlcUSMSta "Hetaer Balance Assistant USM R vaule";
BA_ "GenSigSendType" SG_ 1133 APSU_HtBlcUSMSta 4;
BA_ "UserSigValidity" SG_ 1133 APSU_HtBlcUSMSta 0;
BA_ "Version" SG_ 1133 APSU_HtBlcUSMSta "21.07.06";
BA_ "Description" SG_ 1133 APSU_AstAntPncMod "¾ÈÆ¼-ÇÉÄ¡ µ¿ÀÛ »óÅÂ Á¤º¸

Anti-Pinch Mode Operating Status Information";
BA_ "GenSigSendType" SG_ 1133 APSU_AstAntPncMod 4;
BA_ "UserSigValidity" SG_ 1133 APSU_AstAntPncMod 0;
BA_ "Version" SG_ 1133 APSU_AstAntPncMod "20.12.04";
BA_ "Description" SG_ 1133 APSU_AstOneTchFldModSta "¸®Å¬¶óÀÌ´× / ¿øÅÍÄ¡Æúµå ¸ðµå Á¤º¸

Assist Reclining / One-Touch Folding Mode Status Information";
BA_ "GenSigSendType" SG_ 1133 APSU_AstOneTchFldModSta 4;
BA_ "UserSigValidity" SG_ 1133 APSU_AstOneTchFldModSta 0;
BA_ "Version" SG_ 1133 APSU_AstOneTchFldModSta "21.07.06";
BA_ "Description" SG_ 1133 APSU_AstOneTchOperSta "¿øÅÍÄ¡ µ¿ÀÛ °¡´É ¿©ºÎ ¹× µ¿ÀÛ ¿Ï·á »óÅÂ Á¤º¸

One-Touch Operating Status Information";
BA_ "GenSigSendType" SG_ 1133 APSU_AstOneTchOperSta 4;
BA_ "UserSigValidity" SG_ 1133 APSU_AstOneTchOperSta 0;
BA_ "Version" SG_ 1133 APSU_AstOneTchOperSta "21.07.06";
BA_ "Description" SG_ 1133 APSU_AstRelaxModeSta "APSU_AssistRelaxModeState";
BA_ "GenSigSendType" SG_ 1133 APSU_AstRelaxModeSta 4;
BA_ "UserSigValidity" SG_ 1133 APSU_AstRelaxModeSta 0;
BA_REL_ "GenSigTimeoutTime" BU_SG_REL_ CGW_CCU SG_ 1133 APSU_AstRelaxModeSta 1500;
BA_ "NetworkRequest" SG_ 1133 APSU_AstRelaxModeSta 0;
BA_ "NetworkRequestHoldingTime" SG_ 1133 APSU_AstRelaxModeSta 5000;
BA_ "Version" SG_ 1133 APSU_AstRelaxModeSta "19.12.00";
BA_ "GenMsgSendType" BO_ 1134 0;
BA_ "Description" SG_ 1134 APSU_AstStSldFwdDis "This signal is used to display the seat movement to AVN";
BA_ "GenSigSendType" SG_ 1134 APSU_AstStSldFwdDis 4;
BA_ "UserSigValidity" SG_ 1134 APSU_AstStSldFwdDis 1;
BA_REL_ "GenSigTimeoutTime" BU_SG_REL_ CGW_CCU SG_ 1134 APSU_AstStSldFwdDis 1500;
BA_ "NetworkRequest" SG_ 1134 APSU_AstStSldFwdDis 0;
BA_ "NetworkRequestHoldingTime" SG_ 1134 APSU_AstStSldFwdDis 5000;
BA_ "Version" SG_ 1134 APSU_AstStSldFwdDis "18.02.01";
BA_ "Description" SG_ 1134 APSU_AstStTiltDnDis "This signal is used to display the seat movement to AVN";
BA_ "GenSigSendType" SG_ 1134 APSU_AstStTiltDnDis 4;
BA_ "UserSigValidity" SG_ 1134 APSU_AstStTiltDnDis 1;
BA_REL_ "GenSigTimeoutTime" BU_SG_REL_ CGW_CCU SG_ 1134 APSU_AstStTiltDnDis 1500;
BA_ "NetworkRequest" SG_ 1134 APSU_AstStTiltDnDis 0;
BA_ "NetworkRequestHoldingTime" SG_ 1134 APSU_AstStTiltDnDis 5000;
BA_ "Version" SG_ 1134 APSU_AstStTiltDnDis "18.02.01";
BA_ "Description" SG_ 1134 APSU_AstStHghtUpDis "This signal is used to display the seat movement to AVN";
BA_ "GenSigSendType" SG_ 1134 APSU_AstStHghtUpDis 4;
BA_ "UserSigValidity" SG_ 1134 APSU_AstStHghtUpDis 1;
BA_REL_ "GenSigTimeoutTime" BU_SG_REL_ CGW_CCU SG_ 1134 APSU_AstStHghtUpDis 1500;
BA_ "NetworkRequest" SG_ 1134 APSU_AstStHghtUpDis 0;
BA_ "NetworkRequestHoldingTime" SG_ 1134 APSU_AstStHghtUpDis 5000;
BA_ "Version" SG_ 1134 APSU_AstStHghtUpDis "18.02.01";
BA_ "Description" SG_ 1134 APSU_AstStHghtDnDis "This signal is used to display the seat movement to AVN";
BA_ "GenSigSendType" SG_ 1134 APSU_AstStHghtDnDis 4;
BA_ "UserSigValidity" SG_ 1134 APSU_AstStHghtDnDis 1;
BA_REL_ "GenSigTimeoutTime" BU_SG_REL_ CGW_CCU SG_ 1134 APSU_AstStHghtDnDis 1500;
BA_ "NetworkRequest" SG_ 1134 APSU_AstStHghtDnDis 0;
BA_ "NetworkRequestHoldingTime" SG_ 1134 APSU_AstStHghtDnDis 5000;
BA_ "Version" SG_ 1134 APSU_AstStHghtDnDis "18.02.01";
BA_ "Description" SG_ 1134 APSU_AstStLegUpDis "This signal is used to display the seat movement to AVN";
BA_ "GenSigSendType" SG_ 1134 APSU_AstStLegUpDis 4;
BA_ "UserSigValidity" SG_ 1134 APSU_AstStLegUpDis 1;
BA_ "NetworkRequest" SG_ 1134 APSU_AstStLegUpDis 0;
BA_ "NetworkRequestHoldingTime" SG_ 1134 APSU_AstStLegUpDis 5000;
BA_ "Version" SG_ 1134 APSU_AstStLegUpDis "19.12.00";
BA_ "Description" SG_ 1134 APSU_AstStLegtDnDis "This signal is used to display the seat movement to AVN";
BA_ "GenSigSendType" SG_ 1134 APSU_AstStLegtDnDis 4;
BA_ "UserSigValidity" SG_ 1134 APSU_AstStLegtDnDis 1;
BA_ "NetworkRequest" SG_ 1134 APSU_AstStLegtDnDis 0;
BA_ "NetworkRequestHoldingTime" SG_ 1134 APSU_AstStLegtDnDis 5000;
BA_ "Version" SG_ 1134 APSU_AstStLegtDnDis "19.12.00";
BA_ "Description" SG_ 1134 APSU_AstStSldBckwdDis "This signal is used to display the seat movement to AVN";
BA_ "GenSigSendType" SG_ 1134 APSU_AstStSldBckwdDis 4;
BA_ "UserSigValidity" SG_ 1134 APSU_AstStSldBckwdDis 1;
BA_REL_ "GenSigTimeoutTime" BU_SG_REL_ CGW_CCU SG_ 1134 APSU_AstStSldBckwdDis 1500;
BA_ "NetworkRequest" SG_ 1134 APSU_AstStSldBckwdDis 0;
BA_ "NetworkRequestHoldingTime" SG_ 1134 APSU_AstStSldBckwdDis 5000;
BA_ "Version" SG_ 1134 APSU_AstStSldBckwdDis "18.02.01";
BA_ "Description" SG_ 1134 APSU_AstStRlxTiltUpDis "This signal is used to display the seat movement to AVN";
BA_ "GenSigSendType" SG_ 1134 APSU_AstStRlxTiltUpDis 4;
BA_ "UserSigValidity" SG_ 1134 APSU_AstStRlxTiltUpDis 1;
BA_REL_ "GenSigTimeoutTime" BU_SG_REL_ CGW_CCU SG_ 1134 APSU_AstStRlxTiltUpDis 1500;
BA_ "NetworkRequest" SG_ 1134 APSU_AstStRlxTiltUpDis 0;
BA_ "NetworkRequestHoldingTime" SG_ 1134 APSU_AstStRlxTiltUpDis 5000;
BA_ "Version" SG_ 1134 APSU_AstStRlxTiltUpDis "19.12.02";
BA_ "Description" SG_ 1134 APSU_AstStRlxTiltDnDis "This signal is used to display the seat movement to AVN";
BA_ "GenSigSendType" SG_ 1134 APSU_AstStRlxTiltDnDis 4;
BA_ "UserSigValidity" SG_ 1134 APSU_AstStRlxTiltDnDis 1;
BA_REL_ "GenSigTimeoutTime" BU_SG_REL_ CGW_CCU SG_ 1134 APSU_AstStRlxTiltDnDis 1500;
BA_ "NetworkRequest" SG_ 1134 APSU_AstStRlxTiltDnDis 0;
BA_ "NetworkRequestHoldingTime" SG_ 1134 APSU_AstStRlxTiltDnDis 5000;
BA_ "Version" SG_ 1134 APSU_AstStRlxTiltDnDis "19.12.02";
BA_ "Description" SG_ 1134 APSU_AstStCushExtBckwdDis "This signal is used to display the seat movement to AVN";
BA_ "GenSigSendType" SG_ 1134 APSU_AstStCushExtBckwdDis 4;
BA_ "UserSigValidity" SG_ 1134 APSU_AstStCushExtBckwdDis 1;
BA_ "NetworkRequest" SG_ 1134 APSU_AstStCushExtBckwdDis 0;
BA_ "NetworkRequestHoldingTime" SG_ 1134 APSU_AstStCushExtBckwdDis 5000;
BA_ "Version" SG_ 1134 APSU_AstStCushExtBckwdDis "20.11.02";
BA_ "Description" SG_ 1134 APSU_AstStCushExtFwdDis "This signal is used to display the seat movement to AVN";
BA_ "GenSigSendType" SG_ 1134 APSU_AstStCushExtFwdDis 4;
BA_ "UserSigValidity" SG_ 1134 APSU_AstStCushExtFwdDis 1;
BA_ "NetworkRequest" SG_ 1134 APSU_AstStCushExtFwdDis 0;
BA_ "NetworkRequestHoldingTime" SG_ 1134 APSU_AstStCushExtFwdDis 5000;
BA_ "Version" SG_ 1134 APSU_AstStCushExtFwdDis "20.11.02";
BA_ "Description" SG_ 1134 APSU_AstStLmbrDefDis "This signal is used to display the seat movement to AVN";
BA_ "GenSigSendType" SG_ 1134 APSU_AstStLmbrDefDis 4;
BA_ "UserSigValidity" SG_ 1134 APSU_AstStLmbrDefDis 1;
BA_REL_ "GenSigTimeoutTime" BU_SG_REL_ ALBCU SG_ 1134 APSU_AstStLmbrDefDis 1500;
BA_ "NetworkRequest" SG_ 1134 APSU_AstStLmbrDefDis 0;
BA_ "NetworkRequestHoldingTime" SG_ 1134 APSU_AstStLmbrDefDis 5000;
BA_ "Version" SG_ 1134 APSU_AstStLmbrDefDis "18.02.01";
BA_ "Description" SG_ 1134 APSU_AstStLmbrLoDis "This signal is used to display the seat movement to AVN";
BA_ "GenSigSendType" SG_ 1134 APSU_AstStLmbrLoDis 4;
BA_ "UserSigValidity" SG_ 1134 APSU_AstStLmbrLoDis 1;
BA_REL_ "GenSigTimeoutTime" BU_SG_REL_ ALBCU SG_ 1134 APSU_AstStLmbrLoDis 1500;
BA_ "NetworkRequest" SG_ 1134 APSU_AstStLmbrLoDis 0;
BA_ "NetworkRequestHoldingTime" SG_ 1134 APSU_AstStLmbrLoDis 5000;
BA_ "Version" SG_ 1134 APSU_AstStLmbrLoDis "18.02.01";
BA_ "Description" SG_ 1134 APSU_AstStLmbrMdlDis "This signal is used to display the seat movement to AVN";
BA_ "GenSigSendType" SG_ 1134 APSU_AstStLmbrMdlDis 4;
BA_ "UserSigValidity" SG_ 1134 APSU_AstStLmbrMdlDis 1;
BA_REL_ "GenSigTimeoutTime" BU_SG_REL_ ALBCU SG_ 1134 APSU_AstStLmbrMdlDis 1500;
BA_ "NetworkRequest" SG_ 1134 APSU_AstStLmbrMdlDis 0;
BA_ "NetworkRequestHoldingTime" SG_ 1134 APSU_AstStLmbrMdlDis 5000;
BA_ "Version" SG_ 1134 APSU_AstStLmbrMdlDis "18.02.01";
BA_ "Description" SG_ 1134 APSU_AstStLmbrUpDis "This signal is used to display the seat movement to AVN";
BA_ "GenSigSendType" SG_ 1134 APSU_AstStLmbrUpDis 4;
BA_ "UserSigValidity" SG_ 1134 APSU_AstStLmbrUpDis 1;
BA_REL_ "GenSigTimeoutTime" BU_SG_REL_ ALBCU SG_ 1134 APSU_AstStLmbrUpDis 1500;
BA_ "NetworkRequest" SG_ 1134 APSU_AstStLmbrUpDis 0;
BA_ "NetworkRequestHoldingTime" SG_ 1134 APSU_AstStLmbrUpDis 5000;
BA_ "Version" SG_ 1134 APSU_AstStLmbrUpDis "18.02.01";
BA_ "Description" SG_ 1134 APSU_AstStReclneFwdDis "This signal is used to display the seat movement to AVN";
BA_ "GenSigSendType" SG_ 1134 APSU_AstStReclneFwdDis 4;
BA_ "UserSigValidity" SG_ 1134 APSU_AstStReclneFwdDis 1;
BA_REL_ "GenSigTimeoutTime" BU_SG_REL_ CGW_CCU SG_ 1134 APSU_AstStReclneFwdDis 1500;
BA_ "NetworkRequest" SG_ 1134 APSU_AstStReclneFwdDis 0;
BA_ "NetworkRequestHoldingTime" SG_ 1134 APSU_AstStReclneFwdDis 5000;
BA_ "Version" SG_ 1134 APSU_AstStReclneFwdDis "18.02.01";
BA_ "Description" SG_ 1134 APSU_LmbrSigSrcTyp "-(Old)C_APSULumbarOpt";
BA_ "GenSigSendType" SG_ 1134 APSU_LmbrSigSrcTyp 4;
BA_ "UserSigValidity" SG_ 1134 APSU_LmbrSigSrcTyp 0;
BA_REL_ "GenSigTimeoutTime" BU_SG_REL_ ALBCU SG_ 1134 APSU_LmbrSigSrcTyp 1500;
BA_ "NetworkRequest" SG_ 1134 APSU_LmbrSigSrcTyp 0;
BA_ "NetworkRequestHoldingTime" SG_ 1134 APSU_LmbrSigSrcTyp 5000;
BA_ "Version" SG_ 1134 APSU_LmbrSigSrcTyp "21.07.06";
BA_ "Description" SG_ 1134 APSU_APSUOpt "APSU Àû¿ë ¿É¼Ç ÆÇ´Ü ½ÅÈ£

APSU Option Status Information";
BA_ "GenSigSendType" SG_ 1134 APSU_APSUOpt 4;
BA_ "UserSigValidity" SG_ 1134 APSU_APSUOpt 0;
BA_ "Version" SG_ 1134 APSU_APSUOpt "20.12.04";
BA_ "Description" SG_ 1134 APSU_AstStReclneBckwdDis "This signal is used to display the seat movement to AVN";
BA_ "GenSigSendType" SG_ 1134 APSU_AstStReclneBckwdDis 4;
BA_ "UserSigValidity" SG_ 1134 APSU_AstStReclneBckwdDis 1;
BA_REL_ "GenSigTimeoutTime" BU_SG_REL_ CGW_CCU SG_ 1134 APSU_AstStReclneBckwdDis 1500;
BA_ "NetworkRequest" SG_ 1134 APSU_AstStReclneBckwdDis 0;
BA_ "NetworkRequestHoldingTime" SG_ 1134 APSU_AstStReclneBckwdDis 5000;
BA_ "Version" SG_ 1134 APSU_AstStReclneBckwdDis "18.02.01";
BA_ "Description" SG_ 1134 APSU_AstStTiltUpDis "This signal is used to display the seat movement to AVN";
BA_ "GenSigSendType" SG_ 1134 APSU_AstStTiltUpDis 4;
BA_ "UserSigValidity" SG_ 1134 APSU_AstStTiltUpDis 1;
BA_REL_ "GenSigTimeoutTime" BU_SG_REL_ CGW_CCU SG_ 1134 APSU_AstStTiltUpDis 1500;
BA_ "NetworkRequest" SG_ 1134 APSU_AstStTiltUpDis 0;
BA_ "NetworkRequestHoldingTime" SG_ 1134 APSU_AstStTiltUpDis 5000;
BA_ "Version" SG_ 1134 APSU_AstStTiltUpDis "18.02.01";
BA_ "NmStationAddress" BU_ ARS 10;
BA_ "GenMsgSendType" BO_ 1115 0;
BA_ "Description" SG_ 1115 ARS_OnOffSta "-(Old)C_SwLock";
BA_ "GenSigSendType" SG_ 1115 ARS_OnOffSta 4;
BA_ "UserSigValidity" SG_ 1115 ARS_OnOffSta 0;
BA_ "NetworkRequest" SG_ 1115 ARS_OnOffSta 0;
BA_ "NetworkRequestHoldingTime" SG_ 1115 ARS_OnOffSta 5000;
BA_ "Version" SG_ 1115 ARS_OnOffSta "17.11.00";
BA_ "Description" SG_ 1115 ARS_RrCurtainSwSta "-(Old)C_RearCurtainSw";
BA_ "GenSigSendType" SG_ 1115 ARS_RrCurtainSwSta 4;
BA_ "UserSigValidity" SG_ 1115 ARS_RrCurtainSwSta 0;
BA_REL_ "GenSigTimeoutTime" BU_SG_REL_ CGW_CCU SG_ 1115 ARS_RrCurtainSwSta 1500;
BA_ "NetworkRequest" SG_ 1115 ARS_RrCurtainSwSta 0;
BA_ "NetworkRequestHoldingTime" SG_ 1115 ARS_RrCurtainSwSta 5000;
BA_ "Version" SG_ 1115 ARS_RrCurtainSwSta "17.11.00";
BA_ "Description" SG_ 1115 ARS_RrLftStRetModSwSta "Rear Left Seat Return Mode Switch Information";
BA_ "GenSigSendType" SG_ 1115 ARS_RrLftStRetModSwSta 4;
BA_ "UserSigValidity" SG_ 1115 ARS_RrLftStRetModSwSta 0;
BA_ "NetworkRequest" SG_ 1115 ARS_RrLftStRetModSwSta 0;
BA_ "NetworkRequestHoldingTime" SG_ 1115 ARS_RrLftStRetModSwSta 5000;
BA_ "Version" SG_ 1115 ARS_RrLftStRetModSwSta "17.11.00";
BA_ "Description" SG_ 1115 ARS_RrLftStRlxModSwSta "Rear Left Seat Relax Mode Switch Information";
BA_ "GenSigSendType" SG_ 1115 ARS_RrLftStRlxModSwSta 4;
BA_ "UserSigValidity" SG_ 1115 ARS_RrLftStRlxModSwSta 0;
BA_ "NetworkRequest" SG_ 1115 ARS_RrLftStRlxModSwSta 0;
BA_ "NetworkRequestHoldingTime" SG_ 1115 ARS_RrLftStRlxModSwSta 5000;
BA_ "Version" SG_ 1115 ARS_RrLftStRlxModSwSta "17.11.00";
BA_ "Description" SG_ 1115 ARS_RtMonModSwSta "RH Reading Mode Switch Information";
BA_ "GenSigSendType" SG_ 1115 ARS_RtMonModSwSta 4;
BA_ "UserSigValidity" SG_ 1115 ARS_RtMonModSwSta 0;
BA_ "NetworkRequest" SG_ 1115 ARS_RtMonModSwSta 0;
BA_ "NetworkRequestHoldingTime" SG_ 1115 ARS_RtMonModSwSta 5000;
BA_ "Version" SG_ 1115 ARS_RtMonModSwSta "17.11.00";
BA_ "Description" SG_ 1115 ARS_RtReadModSwSta "RH Reading Mode Switch Information";
BA_ "GenSigSendType" SG_ 1115 ARS_RtReadModSwSta 4;
BA_ "UserSigValidity" SG_ 1115 ARS_RtReadModSwSta 0;
BA_ "NetworkRequest" SG_ 1115 ARS_RtReadModSwSta 0;
BA_ "NetworkRequestHoldingTime" SG_ 1115 ARS_RtReadModSwSta 5000;
BA_ "Version" SG_ 1115 ARS_RtReadModSwSta "17.11.00";
BA_ "Description" SG_ 1115 ARS_ReclneBckwdSwSta "-(Old)C_APSMReclineBwdSw";
BA_ "GenSigSendType" SG_ 1115 ARS_ReclneBckwdSwSta 4;
BA_ "UserSigValidity" SG_ 1115 ARS_ReclneBckwdSwSta 0;
BA_ "NetworkRequest" SG_ 1115 ARS_ReclneBckwdSwSta 0;
BA_ "NetworkRequestHoldingTime" SG_ 1115 ARS_ReclneBckwdSwSta 5000;
BA_ "Version" SG_ 1115 ARS_ReclneBckwdSwSta "17.11.00";
BA_ "Description" SG_ 1115 ARS_RtRetModSwSta "RH Return Mode Switch Information";
BA_ "GenSigSendType" SG_ 1115 ARS_RtRetModSwSta 4;
BA_ "UserSigValidity" SG_ 1115 ARS_RtRetModSwSta 0;
BA_ "NetworkRequest" SG_ 1115 ARS_RtRetModSwSta 0;
BA_ "NetworkRequestHoldingTime" SG_ 1115 ARS_RtRetModSwSta 5000;
BA_ "Version" SG_ 1115 ARS_RtRetModSwSta "17.11.00";
BA_ "Description" SG_ 1115 ARS_RtRlxModSwSta "RH Relax Mode Switch Information";
BA_ "GenSigSendType" SG_ 1115 ARS_RtRlxModSwSta 4;
BA_ "UserSigValidity" SG_ 1115 ARS_RtRlxModSwSta 0;
BA_ "NetworkRequest" SG_ 1115 ARS_RtRlxModSwSta 0;
BA_ "NetworkRequestHoldingTime" SG_ 1115 ARS_RtRlxModSwSta 5000;
BA_ "Version" SG_ 1115 ARS_RtRlxModSwSta "17.11.00";
BA_ "Description" SG_ 1115 ARS_SwLkSta "-(Old)C_SwLockState";
BA_ "GenSigSendType" SG_ 1115 ARS_SwLkSta 4;
BA_ "UserSigValidity" SG_ 1115 ARS_SwLkSta 0;
BA_REL_ "GenSigTimeoutTime" BU_SG_REL_ CGW_CCU SG_ 1115 ARS_SwLkSta 1500;
BA_ "NetworkRequest" SG_ 1115 ARS_SwLkSta 0;
BA_ "NetworkRequestHoldingTime" SG_ 1115 ARS_SwLkSta 5000;
BA_ "Version" SG_ 1115 ARS_SwLkSta "17.11.00";
BA_ "Description" SG_ 1115 ARS_WalkInFrSwSta "-(Old)C_APSMWalkInFrtSw";
BA_ "GenSigSendType" SG_ 1115 ARS_WalkInFrSwSta 4;
BA_ "UserSigValidity" SG_ 1115 ARS_WalkInFrSwSta 0;
BA_ "NetworkRequest" SG_ 1115 ARS_WalkInFrSwSta 0;
BA_ "NetworkRequestHoldingTime" SG_ 1115 ARS_WalkInFrSwSta 5000;
BA_ "Version" SG_ 1115 ARS_WalkInFrSwSta "17.11.00";
BA_ "Description" SG_ 1115 ARS_WalkInRrSwSta "-(Old)C_APSMWalkInRrSw";
BA_ "GenSigSendType" SG_ 1115 ARS_WalkInRrSwSta 4;
BA_ "UserSigValidity" SG_ 1115 ARS_WalkInRrSwSta 0;
BA_ "NetworkRequest" SG_ 1115 ARS_WalkInRrSwSta 0;
BA_ "NetworkRequestHoldingTime" SG_ 1115 ARS_WalkInRrSwSta 5000;
BA_ "Version" SG_ 1115 ARS_WalkInRrSwSta "17.11.00";
BA_ "Description" SG_ 1115 Lamp_RrRtPrsLmpReq "Rear Right Personal Lamp control Signal for Seat Reading Mode";
BA_ "GenSigSendType" SG_ 1115 Lamp_RrRtPrsLmpReq 4;
BA_ "UserSigValidity" SG_ 1115 Lamp_RrRtPrsLmpReq 0;
BA_ "NetworkRequest" SG_ 1115 Lamp_RrRtPrsLmpReq 0;
BA_ "NetworkRequestHoldingTime" SG_ 1115 Lamp_RrRtPrsLmpReq 5000;
BA_ "Version" SG_ 1115 Lamp_RrRtPrsLmpReq "17.11.00";
BA_ "Description" SG_ 1115 PSM_ApsmPlyBckRrerReq "This signal indicates the playback status";
BA_ "GenSigSendType" SG_ 1115 PSM_ApsmPlyBckRrerReq 4;
BA_ "UserSigValidity" SG_ 1115 PSM_ApsmPlyBckRrerReq 0;
BA_ "NetworkRequest" SG_ 1115 PSM_ApsmPlyBckRrerReq 0;
BA_ "NetworkRequestHoldingTime" SG_ 1115 PSM_ApsmPlyBckRrerReq 5000;
BA_ "Version" SG_ 1115 PSM_ApsmPlyBckRrerReq "17.11.00";
BA_ "Description" SG_ 1115 ARS_ReclneFwdSwSta "-(Old)C_APSMReclineFwdSw";
BA_ "GenSigSendType" SG_ 1115 ARS_ReclneFwdSwSta 4;
BA_ "UserSigValidity" SG_ 1115 ARS_ReclneFwdSwSta 0;
BA_ "NetworkRequest" SG_ 1115 ARS_ReclneFwdSwSta 0;
BA_ "NetworkRequestHoldingTime" SG_ 1115 ARS_ReclneFwdSwSta 5000;
BA_ "Version" SG_ 1115 ARS_ReclneFwdSwSta "17.11.00";
BA_ "Description" SG_ 1115 ARS_RlxFrSwSta "-(Old)C_APSMRelaxFrtSw";
BA_ "GenSigSendType" SG_ 1115 ARS_RlxFrSwSta 4;
BA_ "UserSigValidity" SG_ 1115 ARS_RlxFrSwSta 0;
BA_ "NetworkRequest" SG_ 1115 ARS_RlxFrSwSta 0;
BA_ "NetworkRequestHoldingTime" SG_ 1115 ARS_RlxFrSwSta 5000;
BA_ "Version" SG_ 1115 ARS_RlxFrSwSta "17.11.00";
BA_ "Description" SG_ 1115 ARS_RlxRrSwSta "-(Old)C_APSMRelaxRrSw";
BA_ "GenSigSendType" SG_ 1115 ARS_RlxRrSwSta 4;
BA_ "UserSigValidity" SG_ 1115 ARS_RlxRrSwSta 0;
BA_ "NetworkRequest" SG_ 1115 ARS_RlxRrSwSta 0;
BA_ "NetworkRequestHoldingTime" SG_ 1115 ARS_RlxRrSwSta 5000;
BA_ "Version" SG_ 1115 ARS_RlxRrSwSta "17.11.00";
BA_ "GenMsgSendType" BO_ 1116 0;
BA_ "Description" SG_ 1116 PSM_BzrOnReq "PSM's buzzer on commnad by RLER.";
BA_ "GenSigSendType" SG_ 1116 PSM_BzrOnReq 4;
BA_ "UserSigValidity" SG_ 1116 PSM_BzrOnReq 0;
BA_ "NetworkRequest" SG_ 1116 PSM_BzrOnReq 0;
BA_ "NetworkRequestHoldingTime" SG_ 1116 PSM_BzrOnReq 5000;
BA_ "Version" SG_ 1116 PSM_BzrOnReq "17.11.00";
BA_ "Description" SG_ 1116 PSM_RrRtStMvSta "This signal indicates the playback status";
BA_ "GenSigSendType" SG_ 1116 PSM_RrRtStMvSta 4;
BA_ "UserSigValidity" SG_ 1116 PSM_RrRtStMvSta 0;
BA_ "NetworkRequest" SG_ 1116 PSM_RrRtStMvSta 0;
BA_ "NetworkRequestHoldingTime" SG_ 1116 PSM_RrRtStMvSta 5000;
BA_ "Version" SG_ 1116 PSM_RrRtStMvSta "17.11.00";
BA_ "Description" SG_ 1116 PSM_AsstStCushHghtDnReq "Assist seat cushion height down command";
BA_ "GenSigSendType" SG_ 1116 PSM_AsstStCushHghtDnReq 4;
BA_ "UserSigValidity" SG_ 1116 PSM_AsstStCushHghtDnReq 0;
BA_ "NetworkRequest" SG_ 1116 PSM_AsstStCushHghtDnReq 0;
BA_ "NetworkRequestHoldingTime" SG_ 1116 PSM_AsstStCushHghtDnReq 5000;
BA_ "Version" SG_ 1116 PSM_AsstStCushHghtDnReq "17.11.00";
BA_ "Description" SG_ 1116 PSM_AsstStCushHghtUpReq "Assist seat cushion height up command";
BA_ "GenSigSendType" SG_ 1116 PSM_AsstStCushHghtUpReq 4;
BA_ "UserSigValidity" SG_ 1116 PSM_AsstStCushHghtUpReq 0;
BA_ "NetworkRequest" SG_ 1116 PSM_AsstStCushHghtUpReq 0;
BA_ "NetworkRequestHoldingTime" SG_ 1116 PSM_AsstStCushHghtUpReq 5000;
BA_ "Version" SG_ 1116 PSM_AsstStCushHghtUpReq "17.11.00";
BA_ "Description" SG_ 1116 PSM_LegDnSwSta "-(Old)C_RPSMLegDnSw";
BA_ "GenSigSendType" SG_ 1116 PSM_LegDnSwSta 4;
BA_ "UserSigValidity" SG_ 1116 PSM_LegDnSwSta 0;
BA_ "NetworkRequest" SG_ 1116 PSM_LegDnSwSta 0;
BA_ "NetworkRequestHoldingTime" SG_ 1116 PSM_LegDnSwSta 5000;
BA_ "Version" SG_ 1116 PSM_LegDnSwSta "17.11.00";
BA_ "Description" SG_ 1116 PSM_AsstStHdRstDnReq "Assist seat headrest down command";
BA_ "GenSigSendType" SG_ 1116 PSM_AsstStHdRstDnReq 4;
BA_ "UserSigValidity" SG_ 1116 PSM_AsstStHdRstDnReq 0;
BA_ "NetworkRequest" SG_ 1116 PSM_AsstStHdRstDnReq 0;
BA_ "NetworkRequestHoldingTime" SG_ 1116 PSM_AsstStHdRstDnReq 5000;
BA_ "Version" SG_ 1116 PSM_AsstStHdRstDnReq "17.11.00";
BA_ "Description" SG_ 1116 PSM_AsstStHdRstUpReq "Assist seat headrest up command";
BA_ "GenSigSendType" SG_ 1116 PSM_AsstStHdRstUpReq 4;
BA_ "UserSigValidity" SG_ 1116 PSM_AsstStHdRstUpReq 0;
BA_ "NetworkRequest" SG_ 1116 PSM_AsstStHdRstUpReq 0;
BA_ "NetworkRequestHoldingTime" SG_ 1116 PSM_AsstStHdRstUpReq 5000;
BA_ "Version" SG_ 1116 PSM_AsstStHdRstUpReq "17.11.00";
BA_ "Description" SG_ 1116 PSM_AsstStReclneBckwdReq "Assist seat recline backward command";
BA_ "GenSigSendType" SG_ 1116 PSM_AsstStReclneBckwdReq 4;
BA_ "UserSigValidity" SG_ 1116 PSM_AsstStReclneBckwdReq 0;
BA_ "NetworkRequest" SG_ 1116 PSM_AsstStReclneBckwdReq 0;
BA_ "NetworkRequestHoldingTime" SG_ 1116 PSM_AsstStReclneBckwdReq 5000;
BA_ "Version" SG_ 1116 PSM_AsstStReclneBckwdReq "17.11.00";
BA_ "Description" SG_ 1116 PSM_AsstStReclneFwdReq "Assist seat recline forward command";
BA_ "GenSigSendType" SG_ 1116 PSM_AsstStReclneFwdReq 4;
BA_ "UserSigValidity" SG_ 1116 PSM_AsstStReclneFwdReq 0;
BA_ "NetworkRequest" SG_ 1116 PSM_AsstStReclneFwdReq 0;
BA_ "NetworkRequestHoldingTime" SG_ 1116 PSM_AsstStReclneFwdReq 5000;
BA_ "Version" SG_ 1116 PSM_AsstStReclneFwdReq "17.11.00";
BA_ "Description" SG_ 1116 PSM_AsstStSldBckwdReq "Assist seat slide  backward command";
BA_ "GenSigSendType" SG_ 1116 PSM_AsstStSldBckwdReq 4;
BA_ "UserSigValidity" SG_ 1116 PSM_AsstStSldBckwdReq 0;
BA_ "NetworkRequest" SG_ 1116 PSM_AsstStSldBckwdReq 0;
BA_ "NetworkRequestHoldingTime" SG_ 1116 PSM_AsstStSldBckwdReq 5000;
BA_ "Version" SG_ 1116 PSM_AsstStSldBckwdReq "17.11.00";
BA_ "Description" SG_ 1116 PSM_AsstStSldFwdReq "Assist seat slide foward command";
BA_ "GenSigSendType" SG_ 1116 PSM_AsstStSldFwdReq 4;
BA_ "UserSigValidity" SG_ 1116 PSM_AsstStSldFwdReq 0;
BA_ "NetworkRequest" SG_ 1116 PSM_AsstStSldFwdReq 0;
BA_ "NetworkRequestHoldingTime" SG_ 1116 PSM_AsstStSldFwdReq 5000;
BA_ "Version" SG_ 1116 PSM_AsstStSldFwdReq "17.11.00";
BA_ "NmStationAddress" BU_ GW_DLBCU 64;
BA_ "Description" SG_ 1116 ARS_RR_ActiveSw "ARS_RR_ActiveSw";
BA_ "GenSigSendType" SG_ 1116 ARS_RR_ActiveSw 4;
BA_ "UserSigValidity" SG_ 1116 ARS_RR_ActiveSw 0;
BA_REL_ "GenSigTimeoutTime" BU_SG_REL_ GW_DLBCU SG_ 1116 ARS_RR_ActiveSw 1500;
BA_ "NetworkRequest" SG_ 1116 ARS_RR_ActiveSw 0;
BA_ "NetworkRequestHoldingTime" SG_ 1116 ARS_RR_ActiveSw 5000;
BA_ "Version" SG_ 1116 ARS_RR_ActiveSw "23.10.11";
BA_ "Description" SG_ 1116 ARS_RL_ActiveSw "ARS_RL_ActiveSw";
BA_ "GenSigSendType" SG_ 1116 ARS_RL_ActiveSw 4;
BA_ "UserSigValidity" SG_ 1116 ARS_RL_ActiveSw 0;
BA_REL_ "GenSigTimeoutTime" BU_SG_REL_ GW_DLBCU SG_ 1116 ARS_RL_ActiveSw 1500;
BA_ "NetworkRequest" SG_ 1116 ARS_RL_ActiveSw 0;
BA_ "NetworkRequestHoldingTime" SG_ 1116 ARS_RL_ActiveSw 5000;
BA_ "Version" SG_ 1116 ARS_RL_ActiveSw "23.10.11";
BA_ "Description" SG_ 1116 PSM_LegUpSwSta "-(Old)C_RPSMLegUpSw";
BA_ "GenSigSendType" SG_ 1116 PSM_LegUpSwSta 4;
BA_ "UserSigValidity" SG_ 1116 PSM_LegUpSwSta 0;
BA_ "NetworkRequest" SG_ 1116 PSM_LegUpSwSta 0;
BA_ "NetworkRequestHoldingTime" SG_ 1116 PSM_LegUpSwSta 5000;
BA_ "Version" SG_ 1116 PSM_LegUpSwSta "17.11.00";
BA_ "Description" SG_ 1116 PSM_RrLftStSldPosVal "RL SEAT (RLER) SLIDE POSITION (UNIT:mm)";
BA_ "GenSigSendType" SG_ 1116 PSM_RrLftStSldPosVal 4;
BA_ "UserSigValidity" SG_ 1116 PSM_RrLftStSldPosVal 0;
BA_ "NetworkRequest" SG_ 1116 PSM_RrLftStSldPosVal 0;
BA_ "NetworkRequestHoldingTime" SG_ 1116 PSM_RrLftStSldPosVal 5000;
BA_ "Version" SG_ 1116 PSM_RrLftStSldPosVal "17.11.00";
BA_ "Description" SG_ 1116 PSM_RrRtStMvFnshSta "This signal indicates the finish of rear right seat moving";
BA_ "GenSigSendType" SG_ 1116 PSM_RrRtStMvFnshSta 4;
BA_ "UserSigValidity" SG_ 1116 PSM_RrRtStMvFnshSta 0;
BA_ "NetworkRequest" SG_ 1116 PSM_RrRtStMvFnshSta 0;
BA_ "NetworkRequestHoldingTime" SG_ 1116 PSM_RrRtStMvFnshSta 5000;
BA_ "Version" SG_ 1116 PSM_RrRtStMvFnshSta "17.11.00";
BA_ "GenMsgSendType" BO_ 1117 0;
BA_ "Description" SG_ 1117 PSM_RrLftHdRstBckwdReq "Rear Left seat headrest backward command";
BA_ "GenSigSendType" SG_ 1117 PSM_RrLftHdRstBckwdReq 4;
BA_ "UserSigValidity" SG_ 1117 PSM_RrLftHdRstBckwdReq 0;
BA_ "NetworkRequest" SG_ 1117 PSM_RrLftHdRstBckwdReq 0;
BA_ "NetworkRequestHoldingTime" SG_ 1117 PSM_RrLftHdRstBckwdReq 5000;
BA_ "Version" SG_ 1117 PSM_RrLftHdRstBckwdReq "17.11.00";
BA_ "Description" SG_ 1117 PSM_RrLftStCushTiltUpReq "Rear Left seat cushion tilt up command";
BA_ "GenSigSendType" SG_ 1117 PSM_RrLftStCushTiltUpReq 4;
BA_ "UserSigValidity" SG_ 1117 PSM_RrLftStCushTiltUpReq 0;
BA_ "NetworkRequest" SG_ 1117 PSM_RrLftStCushTiltUpReq 0;
BA_ "NetworkRequestHoldingTime" SG_ 1117 PSM_RrLftStCushTiltUpReq 5000;
BA_ "Version" SG_ 1117 PSM_RrLftStCushTiltUpReq "17.11.00";
BA_ "Description" SG_ 1117 PSM_RrLftStShldrBckwdReq "Rear Left seat shoulder adjuster backward command";
BA_ "GenSigSendType" SG_ 1117 PSM_RrLftStShldrBckwdReq 4;
BA_ "UserSigValidity" SG_ 1117 PSM_RrLftStShldrBckwdReq 0;
BA_ "NetworkRequest" SG_ 1117 PSM_RrLftStShldrBckwdReq 0;
BA_ "NetworkRequestHoldingTime" SG_ 1117 PSM_RrLftStShldrBckwdReq 5000;
BA_ "Version" SG_ 1117 PSM_RrLftStShldrBckwdReq "17.11.00";
BA_ "Description" SG_ 1117 PSM_RrLftStShldrFwdReq "Rear Left seat shoulder adjuster forward command";
BA_ "GenSigSendType" SG_ 1117 PSM_RrLftStShldrFwdReq 4;
BA_ "UserSigValidity" SG_ 1117 PSM_RrLftStShldrFwdReq 0;
BA_ "NetworkRequest" SG_ 1117 PSM_RrLftStShldrFwdReq 0;
BA_ "NetworkRequestHoldingTime" SG_ 1117 PSM_RrLftStShldrFwdReq 5000;
BA_ "Version" SG_ 1117 PSM_RrLftStShldrFwdReq "17.11.00";
BA_ "Description" SG_ 1117 PSM_RrLftStSldBckwdReq "Rear Left seat slide  backward command";
BA_ "GenSigSendType" SG_ 1117 PSM_RrLftStSldBckwdReq 4;
BA_ "UserSigValidity" SG_ 1117 PSM_RrLftStSldBckwdReq 0;
BA_REL_ "GenSigTimeoutTime" BU_SG_REL_ GW_RRPSU SG_ 1117 PSM_RrLftStSldBckwdReq 1500;
BA_ "NetworkRequest" SG_ 1117 PSM_RrLftStSldBckwdReq 0;
BA_ "NetworkRequestHoldingTime" SG_ 1117 PSM_RrLftStSldBckwdReq 5000;
BA_ "Version" SG_ 1117 PSM_RrLftStSldBckwdReq "17.11.00";
BA_ "Description" SG_ 1117 PSM_RrLftStSldFwdReq "Rear Left seat slide foward command";
BA_ "GenSigSendType" SG_ 1117 PSM_RrLftStSldFwdReq 4;
BA_ "UserSigValidity" SG_ 1117 PSM_RrLftStSldFwdReq 0;
BA_REL_ "GenSigTimeoutTime" BU_SG_REL_ GW_RRPSU SG_ 1117 PSM_RrLftStSldFwdReq 1500;
BA_ "NetworkRequest" SG_ 1117 PSM_RrLftStSldFwdReq 0;
BA_ "NetworkRequestHoldingTime" SG_ 1117 PSM_RrLftStSldFwdReq 5000;
BA_ "Version" SG_ 1117 PSM_RrLftStSldFwdReq "17.11.00";
BA_ "Description" SG_ 1117 PSM_RrLftHdRstDnReq "Rear Left seat headrest down command";
BA_ "GenSigSendType" SG_ 1117 PSM_RrLftHdRstDnReq 4;
BA_ "UserSigValidity" SG_ 1117 PSM_RrLftHdRstDnReq 0;
BA_ "NetworkRequest" SG_ 1117 PSM_RrLftHdRstDnReq 0;
BA_ "NetworkRequestHoldingTime" SG_ 1117 PSM_RrLftHdRstDnReq 5000;
BA_ "Version" SG_ 1117 PSM_RrLftHdRstDnReq "17.11.00";
BA_ "Description" SG_ 1117 PSM_RrRtStCushTiltDnReq "Rear Right seat cushion tilt down command";
BA_ "GenSigSendType" SG_ 1117 PSM_RrRtStCushTiltDnReq 4;
BA_ "UserSigValidity" SG_ 1117 PSM_RrRtStCushTiltDnReq 0;
BA_ "NetworkRequest" SG_ 1117 PSM_RrRtStCushTiltDnReq 0;
BA_ "NetworkRequestHoldingTime" SG_ 1117 PSM_RrRtStCushTiltDnReq 5000;
BA_ "Version" SG_ 1117 PSM_RrRtStCushTiltDnReq "17.11.00";
BA_ "Description" SG_ 1117 PSM_RrRtStCushTiltUpReq "Rear Right seat cushion tilt up command";
BA_ "GenSigSendType" SG_ 1117 PSM_RrRtStCushTiltUpReq 4;
BA_ "UserSigValidity" SG_ 1117 PSM_RrRtStCushTiltUpReq 0;
BA_ "NetworkRequest" SG_ 1117 PSM_RrRtStCushTiltUpReq 0;
BA_ "NetworkRequestHoldingTime" SG_ 1117 PSM_RrRtStCushTiltUpReq 5000;
BA_ "Version" SG_ 1117 PSM_RrRtStCushTiltUpReq "17.11.00";
BA_ "Description" SG_ 1117 PSM_RrRtStHdRstBckwdReq "Rear Right seat headrest backward command";
BA_ "GenSigSendType" SG_ 1117 PSM_RrRtStHdRstBckwdReq 4;
BA_ "UserSigValidity" SG_ 1117 PSM_RrRtStHdRstBckwdReq 0;
BA_ "NetworkRequest" SG_ 1117 PSM_RrRtStHdRstBckwdReq 0;
BA_ "NetworkRequestHoldingTime" SG_ 1117 PSM_RrRtStHdRstBckwdReq 5000;
BA_ "Version" SG_ 1117 PSM_RrRtStHdRstBckwdReq "17.11.00";
BA_ "Description" SG_ 1117 PSM_RrRtStHdRstDnReq "Rear Right seat headrest down command";
BA_ "GenSigSendType" SG_ 1117 PSM_RrRtStHdRstDnReq 4;
BA_ "UserSigValidity" SG_ 1117 PSM_RrRtStHdRstDnReq 0;
BA_ "NetworkRequest" SG_ 1117 PSM_RrRtStHdRstDnReq 0;
BA_ "NetworkRequestHoldingTime" SG_ 1117 PSM_RrRtStHdRstDnReq 5000;
BA_ "Version" SG_ 1117 PSM_RrRtStHdRstDnReq "17.11.00";
BA_ "Description" SG_ 1117 PSM_RrRtStHdRstFwdReq "Rear Right seat headrest foward command";
BA_ "GenSigSendType" SG_ 1117 PSM_RrRtStHdRstFwdReq 4;
BA_ "UserSigValidity" SG_ 1117 PSM_RrRtStHdRstFwdReq 0;
BA_ "NetworkRequest" SG_ 1117 PSM_RrRtStHdRstFwdReq 0;
BA_ "NetworkRequestHoldingTime" SG_ 1117 PSM_RrRtStHdRstFwdReq 5000;
BA_ "Version" SG_ 1117 PSM_RrRtStHdRstFwdReq "17.11.00";
BA_ "Description" SG_ 1117 PSM_RrRtStHdRstUpReq "Rear Right seat headrest up command";
BA_ "GenSigSendType" SG_ 1117 PSM_RrRtStHdRstUpReq 4;
BA_ "UserSigValidity" SG_ 1117 PSM_RrRtStHdRstUpReq 0;
BA_ "NetworkRequest" SG_ 1117 PSM_RrRtStHdRstUpReq 0;
BA_ "NetworkRequestHoldingTime" SG_ 1117 PSM_RrRtStHdRstUpReq 5000;
BA_ "Version" SG_ 1117 PSM_RrRtStHdRstUpReq "17.11.00";
BA_ "Description" SG_ 1117 PSM_RrRtStLegSpprtBckwdReq "Rear Right seat lef support backward command";
BA_ "GenSigSendType" SG_ 1117 PSM_RrRtStLegSpprtBckwdReq 4;
BA_ "UserSigValidity" SG_ 1117 PSM_RrRtStLegSpprtBckwdReq 0;
BA_ "NetworkRequest" SG_ 1117 PSM_RrRtStLegSpprtBckwdReq 0;
BA_ "NetworkRequestHoldingTime" SG_ 1117 PSM_RrRtStLegSpprtBckwdReq 5000;
BA_ "Version" SG_ 1117 PSM_RrRtStLegSpprtBckwdReq "17.11.00";
BA_ "Description" SG_ 1117 PSM_RrRtStLegSpprtDnReq "Rear Right seat lef support down command";
BA_ "GenSigSendType" SG_ 1117 PSM_RrRtStLegSpprtDnReq 4;
BA_ "UserSigValidity" SG_ 1117 PSM_RrRtStLegSpprtDnReq 0;
BA_ "NetworkRequest" SG_ 1117 PSM_RrRtStLegSpprtDnReq 0;
BA_ "NetworkRequestHoldingTime" SG_ 1117 PSM_RrRtStLegSpprtDnReq 5000;
BA_ "Version" SG_ 1117 PSM_RrRtStLegSpprtDnReq "17.11.00";
BA_ "Description" SG_ 1117 PSM_RrRtStLegSpprtFwdReq "Rear Right seat leg support forward command";
BA_ "GenSigSendType" SG_ 1117 PSM_RrRtStLegSpprtFwdReq 4;
BA_ "UserSigValidity" SG_ 1117 PSM_RrRtStLegSpprtFwdReq 0;
BA_ "NetworkRequest" SG_ 1117 PSM_RrRtStLegSpprtFwdReq 0;
BA_ "NetworkRequestHoldingTime" SG_ 1117 PSM_RrRtStLegSpprtFwdReq 5000;
BA_ "Version" SG_ 1117 PSM_RrRtStLegSpprtFwdReq "17.11.00";
BA_ "Description" SG_ 1117 PSM_RrRtStLegSpprtUpReq "Rear Right seat leg support up command";
BA_ "GenSigSendType" SG_ 1117 PSM_RrRtStLegSpprtUpReq 4;
BA_ "UserSigValidity" SG_ 1117 PSM_RrRtStLegSpprtUpReq 0;
BA_ "NetworkRequest" SG_ 1117 PSM_RrRtStLegSpprtUpReq 0;
BA_ "NetworkRequestHoldingTime" SG_ 1117 PSM_RrRtStLegSpprtUpReq 5000;
BA_ "Version" SG_ 1117 PSM_RrRtStLegSpprtUpReq "17.11.00";
BA_ "Description" SG_ 1117 PSM_RrLftHdRstFwdReq "Rear Left seat headrest foward command";
BA_ "GenSigSendType" SG_ 1117 PSM_RrLftHdRstFwdReq 4;
BA_ "UserSigValidity" SG_ 1117 PSM_RrLftHdRstFwdReq 0;
BA_ "NetworkRequest" SG_ 1117 PSM_RrLftHdRstFwdReq 0;
BA_ "NetworkRequestHoldingTime" SG_ 1117 PSM_RrLftHdRstFwdReq 5000;
BA_ "Version" SG_ 1117 PSM_RrLftHdRstFwdReq "17.11.00";
BA_ "Description" SG_ 1117 PSM_RrRtStShldrBckwdReq "Rear Right seat shoulder adjuster backward command";
BA_ "GenSigSendType" SG_ 1117 PSM_RrRtStShldrBckwdReq 4;
BA_ "UserSigValidity" SG_ 1117 PSM_RrRtStShldrBckwdReq 0;
BA_ "NetworkRequest" SG_ 1117 PSM_RrRtStShldrBckwdReq 0;
BA_ "NetworkRequestHoldingTime" SG_ 1117 PSM_RrRtStShldrBckwdReq 5000;
BA_ "Version" SG_ 1117 PSM_RrRtStShldrBckwdReq "17.11.00";
BA_ "Description" SG_ 1117 PSM_RrRtStShldrFwdReq "Rear Right seat shoulder adjuster forward command";
BA_ "GenSigSendType" SG_ 1117 PSM_RrRtStShldrFwdReq 4;
BA_ "UserSigValidity" SG_ 1117 PSM_RrRtStShldrFwdReq 0;
BA_ "NetworkRequest" SG_ 1117 PSM_RrRtStShldrFwdReq 0;
BA_ "NetworkRequestHoldingTime" SG_ 1117 PSM_RrRtStShldrFwdReq 5000;
BA_ "Version" SG_ 1117 PSM_RrRtStShldrFwdReq "17.11.00";
BA_ "Description" SG_ 1117 PSM_RrRtStSldBckwdReq "Rear Right seat slide  backward command";
BA_ "GenSigSendType" SG_ 1117 PSM_RrRtStSldBckwdReq 4;
BA_ "UserSigValidity" SG_ 1117 PSM_RrRtStSldBckwdReq 0;
BA_REL_ "GenSigTimeoutTime" BU_SG_REL_ GW_RRPSU SG_ 1117 PSM_RrRtStSldBckwdReq 1500;
BA_ "NetworkRequest" SG_ 1117 PSM_RrRtStSldBckwdReq 0;
BA_ "NetworkRequestHoldingTime" SG_ 1117 PSM_RrRtStSldBckwdReq 5000;
BA_ "Version" SG_ 1117 PSM_RrRtStSldBckwdReq "17.11.00";
BA_ "Description" SG_ 1117 PSM_RrRtStSldFwdReq "Rear Right seat slide foward command";
BA_ "GenSigSendType" SG_ 1117 PSM_RrRtStSldFwdReq 4;
BA_ "UserSigValidity" SG_ 1117 PSM_RrRtStSldFwdReq 0;
BA_REL_ "GenSigTimeoutTime" BU_SG_REL_ GW_RRPSU SG_ 1117 PSM_RrRtStSldFwdReq 1500;
BA_ "NetworkRequest" SG_ 1117 PSM_RrRtStSldFwdReq 0;
BA_ "NetworkRequestHoldingTime" SG_ 1117 PSM_RrRtStSldFwdReq 5000;
BA_ "Version" SG_ 1117 PSM_RrRtStSldFwdReq "17.11.00";
BA_ "Description" SG_ 1117 PSM_StSldBckwdArsSta "-(Old)C_APSMSlideBwdSw";
BA_ "GenSigSendType" SG_ 1117 PSM_StSldBckwdArsSta 4;
BA_ "UserSigValidity" SG_ 1117 PSM_StSldBckwdArsSta 0;
BA_ "NetworkRequest" SG_ 1117 PSM_StSldBckwdArsSta 0;
BA_ "NetworkRequestHoldingTime" SG_ 1117 PSM_StSldBckwdArsSta 5000;
BA_ "Version" SG_ 1117 PSM_StSldBckwdArsSta "17.11.00";
BA_ "Description" SG_ 1117 PSM_StSldFwdArsSta "-(Old)C_APSMSlideFwdSw";
BA_ "GenSigSendType" SG_ 1117 PSM_StSldFwdArsSta 4;
BA_ "UserSigValidity" SG_ 1117 PSM_StSldFwdArsSta 0;
BA_ "NetworkRequest" SG_ 1117 PSM_StSldFwdArsSta 0;
BA_ "NetworkRequestHoldingTime" SG_ 1117 PSM_StSldFwdArsSta 5000;
BA_ "Version" SG_ 1117 PSM_StSldFwdArsSta "17.11.00";
BA_ "NmStationAddress" BU_ RRHV 53;
BA_ "Description" SG_ 1117 ARS_RrHeaterSW "Rear Right Seat Heater Switch";
BA_ "GenSigSendType" SG_ 1117 ARS_RrHeaterSW 4;
BA_ "UserSigValidity" SG_ 1117 ARS_RrHeaterSW 7;
BA_REL_ "GenSigTimeoutTime" BU_SG_REL_ GW_RRPSU SG_ 1117 ARS_RrHeaterSW 1500;
BA_REL_ "GenSigTimeoutTime" BU_SG_REL_ RRHV SG_ 1117 ARS_RrHeaterSW 1500;
BA_ "NetworkRequest" SG_ 1117 ARS_RrHeaterSW 0;
BA_ "NetworkRequestHoldingTime" SG_ 1117 ARS_RrHeaterSW 5000;
BA_ "Version" SG_ 1117 ARS_RrHeaterSW "23.07.05";
BA_ "NmStationAddress" BU_ RLHV 52;
BA_ "Description" SG_ 1117 ARS_RlHeaterSW "Rear Left Seat Heater Switch";
BA_ "GenSigSendType" SG_ 1117 ARS_RlHeaterSW 4;
BA_ "UserSigValidity" SG_ 1117 ARS_RlHeaterSW 7;
BA_REL_ "GenSigTimeoutTime" BU_SG_REL_ GW_RLPSU SG_ 1117 ARS_RlHeaterSW 1500;
BA_REL_ "GenSigTimeoutTime" BU_SG_REL_ RLHV SG_ 1117 ARS_RlHeaterSW 1500;
BA_ "NetworkRequest" SG_ 1117 ARS_RlHeaterSW 0;
BA_ "NetworkRequestHoldingTime" SG_ 1117 ARS_RlHeaterSW 5000;
BA_ "Version" SG_ 1117 ARS_RlHeaterSW "23.07.05";
BA_ "Description" SG_ 1117 ARS_RrVentSW "Rear Right Seat Vent Switch";
BA_ "GenSigSendType" SG_ 1117 ARS_RrVentSW 4;
BA_ "UserSigValidity" SG_ 1117 ARS_RrVentSW 7;
BA_REL_ "GenSigTimeoutTime" BU_SG_REL_ GW_RRPSU SG_ 1117 ARS_RrVentSW 1500;
BA_REL_ "GenSigTimeoutTime" BU_SG_REL_ RRHV SG_ 1117 ARS_RrVentSW 1500;
BA_ "NetworkRequest" SG_ 1117 ARS_RrVentSW 0;
BA_ "NetworkRequestHoldingTime" SG_ 1117 ARS_RrVentSW 5000;
BA_ "Version" SG_ 1117 ARS_RrVentSW "23.07.05";
BA_ "Description" SG_ 1117 ARS_RlVentSW "Rear Left Seat Vent Switch";
BA_ "GenSigSendType" SG_ 1117 ARS_RlVentSW 4;
BA_ "UserSigValidity" SG_ 1117 ARS_RlVentSW 7;
BA_REL_ "GenSigTimeoutTime" BU_SG_REL_ GW_RLPSU SG_ 1117 ARS_RlVentSW 1500;
BA_REL_ "GenSigTimeoutTime" BU_SG_REL_ RLHV SG_ 1117 ARS_RlVentSW 1500;
BA_ "NetworkRequest" SG_ 1117 ARS_RlVentSW 0;
BA_ "NetworkRequestHoldingTime" SG_ 1117 ARS_RlVentSW 5000;
BA_ "Version" SG_ 1117 ARS_RlVentSW "23.07.05";
BA_ "Description" SG_ 1117 PSM_RrLftHdRstUpReq "Rear Left seat headrest up command";
BA_ "GenSigSendType" SG_ 1117 PSM_RrLftHdRstUpReq 4;
BA_ "UserSigValidity" SG_ 1117 PSM_RrLftHdRstUpReq 0;
BA_ "NetworkRequest" SG_ 1117 PSM_RrLftHdRstUpReq 0;
BA_ "NetworkRequestHoldingTime" SG_ 1117 PSM_RrLftHdRstUpReq 5000;
BA_ "Version" SG_ 1117 PSM_RrLftHdRstUpReq "17.11.00";
BA_ "Description" SG_ 1117 PSM_RrLftStCushTiltDnReq "Rear Left seat cushion tilt down command";
BA_ "GenSigSendType" SG_ 1117 PSM_RrLftStCushTiltDnReq 4;
BA_ "UserSigValidity" SG_ 1117 PSM_RrLftStCushTiltDnReq 0;
BA_ "NetworkRequest" SG_ 1117 PSM_RrLftStCushTiltDnReq 0;
BA_ "NetworkRequestHoldingTime" SG_ 1117 PSM_RrLftStCushTiltDnReq 5000;
BA_ "Version" SG_ 1117 PSM_RrLftStCushTiltDnReq "17.11.00";
BA_ "NmStationAddress" BU_ ASAU 83;
BA_ "GenMsgCycleTime" BO_ 1095 0;
BA_ "Description" SG_ 1095 ATS_BeepSound "ATS to AMP BEEP sound trigger";
BA_ "GenSigSendType" SG_ 1095 ATS_BeepSound 4;
BA_ "UserSigValidity" SG_ 1095 ATS_BeepSound 3;
BA_REL_ "GenSigTimeoutTime" BU_SG_REL_ CGW_CCU SG_ 1095 ATS_BeepSound 0;
BA_ "RoutingFactor" SG_ 1095 ATS_BeepSound 0;
BA_ "Version" SG_ 1095 ATS_BeepSound "20.03.00";
BA_ "Description" SG_ 1095 ATS_RRMsgTimeSW "Rear Right Massage Time Button";
BA_ "GenSigSendType" SG_ 1095 ATS_RRMsgTimeSW 4;
BA_ "UserSigValidity" SG_ 1095 ATS_RRMsgTimeSW 3;
BA_ "RoutingFactor" SG_ 1095 ATS_RRMsgTimeSW 0;
BA_ "Version" SG_ 1095 ATS_RRMsgTimeSW "20.07.01";
BA_ "Description" SG_ 1095 ATS_FAUMsgModeSW "Rear Right Foot Massage Mode Button";
BA_ "GenSigSendType" SG_ 1095 ATS_FAUMsgModeSW 4;
BA_ "UserSigValidity" SG_ 1095 ATS_FAUMsgModeSW 3;
BA_REL_ "GenSigTimeoutTime" BU_SG_REL_ ASAU SG_ 1095 ATS_FAUMsgModeSW 0;
BA_ "RoutingFactor" SG_ 1095 ATS_FAUMsgModeSW 0;
BA_ "Version" SG_ 1095 ATS_FAUMsgModeSW "20.07.01";
BA_ "Description" SG_ 1095 ATS_FAUMsgHeatModeSW "Rear Right Foot Massage Heat Mode Button";
BA_ "GenSigSendType" SG_ 1095 ATS_FAUMsgHeatModeSW 4;
BA_ "UserSigValidity" SG_ 1095 ATS_FAUMsgHeatModeSW 3;
BA_REL_ "GenSigTimeoutTime" BU_SG_REL_ ASAU SG_ 1095 ATS_FAUMsgHeatModeSW 0;
BA_ "RoutingFactor" SG_ 1095 ATS_FAUMsgHeatModeSW 0;
BA_ "Version" SG_ 1095 ATS_FAUMsgHeatModeSW "20.07.01";
BA_ "Description" SG_ 1095 ATS_RLMsgMod1SW "Rear Left Massage Mode 1 Button";
BA_ "GenSigSendType" SG_ 1095 ATS_RLMsgMod1SW 4;
BA_ "UserSigValidity" SG_ 1095 ATS_RLMsgMod1SW 3;
BA_ "RoutingFactor" SG_ 1095 ATS_RLMsgMod1SW 0;
BA_ "Version" SG_ 1095 ATS_RLMsgMod1SW "20.12.05";
BA_ "NmStationAddress" BU_ RWPC 31;
BA_ "Description" SG_ 1095 ATS_RWPC_RWPCNValueSet "Rear Wireless Phone Charger ON/OFF Request";
BA_ "GenSigSendType" SG_ 1095 ATS_RWPC_RWPCNValueSet 4;
BA_ "UserSigValidity" SG_ 1095 ATS_RWPC_RWPCNValueSet 3;
BA_REL_ "GenSigTimeoutTime" BU_SG_REL_ RWPC SG_ 1095 ATS_RWPC_RWPCNValueSet 0;
BA_ "RoutingFactor" SG_ 1095 ATS_RWPC_RWPCNValueSet 0;
BA_ "Version" SG_ 1095 ATS_RWPC_RWPCNValueSet "20.03.00";
BA_ "Description" SG_ 1095 ATS_RLMsgMod2SW "Rear Left Massage Mode 2 Button";
BA_ "GenSigSendType" SG_ 1095 ATS_RLMsgMod2SW 4;
BA_ "UserSigValidity" SG_ 1095 ATS_RLMsgMod2SW 3;
BA_ "RoutingFactor" SG_ 1095 ATS_RLMsgMod2SW 0;
BA_ "Version" SG_ 1095 ATS_RLMsgMod2SW "20.12.05";
BA_ "Description" SG_ 1095 ATS_RLMsgMod3SW "Rear Left Massage Mode 3 Button";
BA_ "GenSigSendType" SG_ 1095 ATS_RLMsgMod3SW 4;
BA_ "UserSigValidity" SG_ 1095 ATS_RLMsgMod3SW 3;
BA_ "RoutingFactor" SG_ 1095 ATS_RLMsgMod3SW 0;
BA_ "Version" SG_ 1095 ATS_RLMsgMod3SW "20.12.05";
BA_ "Description" SG_ 1095 ATS_RLMsgMod4SW "Rear Left Massage Mode 4 Button";
BA_ "GenSigSendType" SG_ 1095 ATS_RLMsgMod4SW 4;
BA_ "UserSigValidity" SG_ 1095 ATS_RLMsgMod4SW 3;
BA_ "RoutingFactor" SG_ 1095 ATS_RLMsgMod4SW 0;
BA_ "Version" SG_ 1095 ATS_RLMsgMod4SW "20.12.05";
BA_ "Description" SG_ 1095 ATS_RRMsgMod1SW "Rear Right Massage Mode 1 Button";
BA_ "GenSigSendType" SG_ 1095 ATS_RRMsgMod1SW 4;
BA_ "UserSigValidity" SG_ 1095 ATS_RRMsgMod1SW 3;
BA_ "RoutingFactor" SG_ 1095 ATS_RRMsgMod1SW 0;
BA_ "Version" SG_ 1095 ATS_RRMsgMod1SW "20.12.05";
BA_ "Description" SG_ 1095 ATS_RRMsgMod2SW "Rear Right Massage Mode 2 Button";
BA_ "GenSigSendType" SG_ 1095 ATS_RRMsgMod2SW 4;
BA_ "UserSigValidity" SG_ 1095 ATS_RRMsgMod2SW 3;
BA_ "RoutingFactor" SG_ 1095 ATS_RRMsgMod2SW 0;
BA_ "Version" SG_ 1095 ATS_RRMsgMod2SW "20.12.05";
BA_ "Description" SG_ 1095 ATS_RRMsgMod3SW "Rear Right Massage Mode 3 Button";
BA_ "GenSigSendType" SG_ 1095 ATS_RRMsgMod3SW 4;
BA_ "UserSigValidity" SG_ 1095 ATS_RRMsgMod3SW 3;
BA_ "RoutingFactor" SG_ 1095 ATS_RRMsgMod3SW 0;
BA_ "Version" SG_ 1095 ATS_RRMsgMod3SW "20.12.05";
BA_ "Description" SG_ 1095 ATS_RRMsgMod4SW "Rear Right Massage Mode 4 Button";
BA_ "GenSigSendType" SG_ 1095 ATS_RRMsgMod4SW 4;
BA_ "UserSigValidity" SG_ 1095 ATS_RRMsgMod4SW 3;
BA_ "RoutingFactor" SG_ 1095 ATS_RRMsgMod4SW 0;
BA_ "Version" SG_ 1095 ATS_RRMsgMod4SW "20.12.05";
BA_ "Description" SG_ 1095 ATS_RLEasyAccessSW "ATS touch command for seat easy access (For Rear Left)";
BA_ "GenSigSendType" SG_ 1095 ATS_RLEasyAccessSW 4;
BA_ "UserSigValidity" SG_ 1095 ATS_RLEasyAccessSW 3;
BA_ "RoutingFactor" SG_ 1095 ATS_RLEasyAccessSW 0;
BA_ "Version" SG_ 1095 ATS_RLEasyAccessSW "20.05.02";
BA_ "Description" SG_ 1095 ATS_RREasyAccessSW "ATS touch command for seat easy access (For Rear Right)";
BA_ "GenSigSendType" SG_ 1095 ATS_RREasyAccessSW 4;
BA_ "UserSigValidity" SG_ 1095 ATS_RREasyAccessSW 3;
BA_ "RoutingFactor" SG_ 1095 ATS_RREasyAccessSW 0;
BA_ "Version" SG_ 1095 ATS_RREasyAccessSW "20.05.02";
BA_ "Description" SG_ 1095 ATS_RLMsgTimeSW "Rear Left Massage Time Button";
BA_ "GenSigSendType" SG_ 1095 ATS_RLMsgTimeSW 4;
BA_ "UserSigValidity" SG_ 1095 ATS_RLMsgTimeSW 3;
BA_ "RoutingFactor" SG_ 1095 ATS_RLMsgTimeSW 0;
BA_ "Version" SG_ 1095 ATS_RLMsgTimeSW "20.07.01";
BA_ "NmStationAddress" BU_ SHVU_RR 43;
BA_ "NmStationAddress" BU_ BLTN_CAM 72;
BA_ "NmStationAddress" BU_ SCM 7;
BA_ "NmStationAddress" BU_ PFSU 45;
BA_ "NmStationAddress" BU_ SGU 62;
BA_ "NmStationAddress" BU_ DSAU 89;
BA_ "NmStationAddress" BU_ WPC2 21;
BA_ "NmStationAddress" BU_ WPC 30;
BA_ "GenMsgSendType" BO_ 1090 0;
BA_ "Description" SG_ 1090 BCM_Crc12Val "The data area for CRC calculation is based on the data length (DLC) of the message DB.

The CRC shall be calculated over the entire data block (excluding the CRC bytes) including the user data, alive counter and Data ID 

 

- CRC Polynomial (0x1D) , Initial Value : 0x00, XOR value : 0xFF, Data ID Mode : Both, Data ID : Message ID + 0xF800 

- The initial value is for CRC calculation and the message should be sent with the calculated result value. 

The mathematical expression to 8 bit CRC polynomial is given here. G(x) = x8 + x4 + x3 + x2 + 1";
BA_ "GenSigSendType" SG_ 1090 BCM_Crc12Val 4;
BA_ "UserSigValidity" SG_ 1090 BCM_Crc12Val 0;
BA_ "Version" SG_ 1090 BCM_Crc12Val "21.09.03";
BA_ "Description" SG_ 1090 BCM_AlvCnt12Val "For the first transmission request for a data element the counter shall be initialized with 0 and shall be incremented by 1

for every subsequent send request. When the counter reaches the maximum value(0xE), then it shall restart with 0 for the next send request";
BA_ "GenSigSendType" SG_ 1090 BCM_AlvCnt12Val 4;
BA_ "UserSigValidity" SG_ 1090 BCM_AlvCnt12Val 0;
BA_ "Version" SG_ 1090 BCM_AlvCnt12Val "21.09.03";
BA_ "Description" SG_ 1090 BCM_SmkOptTyp "-(Old)C_PICOption";
BA_ "GenSigSendType" SG_ 1090 BCM_SmkOptTyp 4;
BA_ "UserSigValidity" SG_ 1090 BCM_SmkOptTyp 0;
BA_REL_ "GenSigTimeoutTime" BU_SG_REL_ RWPC SG_ 1090 BCM_SmkOptTyp 1500;
BA_REL_ "GenSigTimeoutTime" BU_SG_REL_ WPC SG_ 1090 BCM_SmkOptTyp 1500;
BA_REL_ "GenSigTimeoutTime" BU_SG_REL_ WPC2 SG_ 1090 BCM_SmkOptTyp 1500;
BA_ "NetworkRequest" SG_ 1090 BCM_SmkOptTyp 0;
BA_ "NetworkRequestHoldingTime" SG_ 1090 BCM_SmkOptTyp 5000;
BA_ "Version" SG_ 1090 BCM_SmkOptTyp "17.12.00";
BA_ "Description" SG_ 1090 PHEV_FuelDrOpnSta "This signal means state of fuel door switch (Open/Close)



Fuel door switch located in fuel door, thus switch states means physical status of fuel door(Open/Close)







* Applied LF PHEV Fuel Door Control Workshop Result



Timeout Value



P-CAN(EMS) : 0x1, 



C-CAN(CLU) : 0x0";
BA_ "GenSigSendType" SG_ 1090 PHEV_FuelDrOpnSta 4;
BA_ "UserSigValidity" SG_ 1090 PHEV_FuelDrOpnSta 0;
BA_ "NetworkRequest" SG_ 1090 PHEV_FuelDrOpnSta 0;
BA_ "NetworkRequestHoldingTime" SG_ 1090 PHEV_FuelDrOpnSta 5000;
BA_ "Version" SG_ 1090 PHEV_FuelDrOpnSta "18.03.04";
BA_ "Description" SG_ 1090 BCM_SunRoofOptTyp "Optional signal for sunroof system with voice control function (C_SunroofOpt)

BDC transmits 0x1 only when LIN communication type Panorama Roof or Panorama Roof with Rear blind is applied. (Others are sent as 0x0)";
BA_ "GenSigSendType" SG_ 1090 BCM_SunRoofOptTyp 4;
BA_ "UserSigValidity" SG_ 1090 BCM_SunRoofOptTyp 0;
BA_REL_ "GenSigTimeoutTime" BU_SG_REL_ ATS SG_ 1090 BCM_SunRoofOptTyp 1500;
BA_ "Version" SG_ 1090 BCM_SunRoofOptTyp "21.07.07";
BA_ "GenSigSendType" SG_ 1090 Window_DrvrSdWdwSta_BCM 4;
BA_ "UserSigValidity" SG_ 1090 Window_DrvrSdWdwSta_BCM 0;
BA_ "NetworkRequest" SG_ 1090 Window_DrvrSdWdwSta_BCM 0;
BA_ "NetworkRequestHoldingTime" SG_ 1090 Window_DrvrSdWdwSta_BCM 5000;
BA_ "Version" SG_ 1090 Window_DrvrSdWdwSta_BCM "17.12.00";
BA_ "Description" SG_ 1090 Window_AsstSdWdwSta_BCM "-(Old)C_AstWdwStat";
BA_ "GenSigSendType" SG_ 1090 Window_AsstSdWdwSta_BCM 4;
BA_ "UserSigValidity" SG_ 1090 Window_AsstSdWdwSta_BCM 0;
BA_ "NetworkRequest" SG_ 1090 Window_AsstSdWdwSta_BCM 0;
BA_ "NetworkRequestHoldingTime" SG_ 1090 Window_AsstSdWdwSta_BCM 5000;
BA_ "Version" SG_ 1090 Window_AsstSdWdwSta_BCM "17.12.00";
BA_ "Description" SG_ 1090 Window_RrLftWdwSta_BCM "-(Old)C_RLWdwSta";
BA_ "GenSigSendType" SG_ 1090 Window_RrLftWdwSta_BCM 4;
BA_ "UserSigValidity" SG_ 1090 Window_RrLftWdwSta_BCM 0;
BA_REL_ "GenSigTimeoutTime" BU_SG_REL_ ATS SG_ 1090 Window_RrLftWdwSta_BCM 1500;
BA_ "NetworkRequest" SG_ 1090 Window_RrLftWdwSta_BCM 0;
BA_ "NetworkRequestHoldingTime" SG_ 1090 Window_RrLftWdwSta_BCM 5000;
BA_ "Version" SG_ 1090 Window_RrLftWdwSta_BCM "17.12.00";
BA_ "Description" SG_ 1090 Window_RrRtWdwSta_BCM "-(Old)C_RRWdwStat";
BA_ "GenSigSendType" SG_ 1090 Window_RrRtWdwSta_BCM 4;
BA_ "UserSigValidity" SG_ 1090 Window_RrRtWdwSta_BCM 0;
BA_REL_ "GenSigTimeoutTime" BU_SG_REL_ ATS SG_ 1090 Window_RrRtWdwSta_BCM 1500;
BA_ "NetworkRequest" SG_ 1090 Window_RrRtWdwSta_BCM 0;
BA_ "NetworkRequestHoldingTime" SG_ 1090 Window_RrRtWdwSta_BCM 5000;
BA_ "Version" SG_ 1090 Window_RrRtWdwSta_BCM "17.12.00";
BA_ "Description" SG_ 1090 SunRoof_GlassPosSta "This signal indicates Sunroof Glass Open/Close Status

(C_GlassPositionState)";
BA_ "GenSigSendType" SG_ 1090 SunRoof_GlassPosSta 4;
BA_ "GenSigStartValue" SG_ 1090 SunRoof_GlassPosSta 15;
BA_ "UserSigValidity" SG_ 1090 SunRoof_GlassPosSta 0;
BA_ "Version" SG_ 1090 SunRoof_GlassPosSta "18.09.00";
BA_ "Description" SG_ 1090 PHEV_FuelDrDis "PHEV Fuel Door Control CLU Display Message from BCM";
BA_ "GenSigSendType" SG_ 1090 PHEV_FuelDrDis 4;
BA_ "UserSigValidity" SG_ 1090 PHEV_FuelDrDis 0;
BA_ "NetworkRequest" SG_ 1090 PHEV_FuelDrDis 0;
BA_ "NetworkRequestHoldingTime" SG_ 1090 PHEV_FuelDrDis 5000;
BA_ "Version" SG_ 1090 PHEV_FuelDrDis "18.03.04";
BA_ "Description" SG_ 1090 SunRoof_BlindPosSta "This signal indicates Sunroof Blind Open/Close Status

(C_BlindPositionState)";
BA_ "GenSigSendType" SG_ 1090 SunRoof_BlindPosSta 4;
BA_ "GenSigStartValue" SG_ 1090 SunRoof_BlindPosSta 15;
BA_ "UserSigValidity" SG_ 1090 SunRoof_BlindPosSta 0;
BA_ "Version" SG_ 1090 SunRoof_BlindPosSta "18.09.00";
BA_ "Description" SG_ 1090 SunRoof_GlassErrSta "This signal indicates Sunroof Glass error Status

(C_GlassErrorState)";
BA_ "GenSigSendType" SG_ 1090 SunRoof_GlassErrSta 4;
BA_ "UserSigValidity" SG_ 1090 SunRoof_GlassErrSta 0;
BA_ "Version" SG_ 1090 SunRoof_GlassErrSta "18.09.00";
BA_ "Description" SG_ 1090 SunRoof_BlindErrSta "This signal indicates Sunroof Blind error Status

(C_BlindErrorState)";
BA_ "GenSigSendType" SG_ 1090 SunRoof_BlindErrSta 4;
BA_ "UserSigValidity" SG_ 1090 SunRoof_BlindErrSta 0;
BA_ "Version" SG_ 1090 SunRoof_BlindErrSta "18.09.00";
BA_ "GenMsgSendType" BO_ 1097 0;
BA_ "Description" SG_ 1097 BCM_Crc13Val "The data area for CRC calculation is based on the data length (DLC) of the message DB.

The CRC shall be calculated over the entire data block (excluding the CRC bytes) including the user data, alive counter and Data ID 

 

- CRC Polynomial (0x1D) , Initial Value : 0x00, XOR value : 0xFF, Data ID Mode : Both, Data ID : Message ID + 0xF800 

- The initial value is for CRC calculation and the message should be sent with the calculated result value. 

The mathematical expression to 8 bit CRC polynomial is given here. G(x) = x8 + x4 + x3 + x2 + 1";
BA_ "GenSigSendType" SG_ 1097 BCM_Crc13Val 4;
BA_ "UserSigValidity" SG_ 1097 BCM_Crc13Val 0;
BA_ "Version" SG_ 1097 BCM_Crc13Val "21.09.03";
BA_ "Description" SG_ 1097 BCM_AlvCnt13Val "For the first transmission request for a data element the counter shall be initialized with 0 and shall be incremented by 1

for every subsequent send request. When the counter reaches the maximum value(0xE), then it shall restart with 0 for the next send request";
BA_ "GenSigSendType" SG_ 1097 BCM_AlvCnt13Val 4;
BA_ "UserSigValidity" SG_ 1097 BCM_AlvCnt13Val 0;
BA_ "Version" SG_ 1097 BCM_AlvCnt13Val "21.09.03";
BA_ "Description" SG_ 1097 StrWhlWrmr_HtngCmd "Steering Wheel Warmer Command";
BA_ "GenSigSendType" SG_ 1097 StrWhlWrmr_HtngCmd 4;
BA_ "UserSigValidity" SG_ 1097 StrWhlWrmr_HtngCmd 0;
BA_ "NetworkRequest" SG_ 1097 StrWhlWrmr_HtngCmd 0;
BA_ "NetworkRequestHoldingTime" SG_ 1097 StrWhlWrmr_HtngCmd 5000;
BA_ "Version" SG_ 1097 StrWhlWrmr_HtngCmd "20.09.00";
BA_ "Description" SG_ 1097 StrWhlWrmr_HtngReqState "Response for Steering Wheel Warmer Request";
BA_ "GenSigSendType" SG_ 1097 StrWhlWrmr_HtngReqState 4;
BA_ "UserSigValidity" SG_ 1097 StrWhlWrmr_HtngReqState 0;
BA_REL_ "GenSigTimeoutTime" BU_SG_REL_ FCS SG_ 1097 StrWhlWrmr_HtngReqState 1500;
BA_ "NetworkRequest" SG_ 1097 StrWhlWrmr_HtngReqState 0;
BA_ "NetworkRequestHoldingTime" SG_ 1097 StrWhlWrmr_HtngReqState 5000;
BA_ "Version" SG_ 1097 StrWhlWrmr_HtngReqState "21.10.05";
BA_ "Description" SG_ 1097 StrWhlWrmr_IndCmd "Steering Wheel Warmer Indicator Command";
BA_ "GenSigSendType" SG_ 1097 StrWhlWrmr_IndCmd 4;
BA_ "UserSigValidity" SG_ 1097 StrWhlWrmr_IndCmd 0;
BA_REL_ "GenSigTimeoutTime" BU_SG_REL_ FCS SG_ 1097 StrWhlWrmr_IndCmd 1500;
BA_ "NetworkRequest" SG_ 1097 StrWhlWrmr_IndCmd 0;
BA_ "NetworkRequestHoldingTime" SG_ 1097 StrWhlWrmr_IndCmd 5000;
BA_ "Version" SG_ 1097 StrWhlWrmr_IndCmd "20.08.02";
BA_ "Description" SG_ 1097 PHEV_FuelDrCtrlFlag "This signal means that fuel door control logic is running or not.

(0x0 : Fuel Door Control Logic Not Running, 0x1 : Fuel Door Control Logic Running)



Fuel Door Control Logic determines whether fuel door opens or not

EMS refer to this signal to open FTIV.



* Applied LF PHEF Fuel Door Control WorkShop Result (141205)

Timeout Value

P-CAN(EMS) : 0x1

C-CAN(CLU) : 0x0





* Applied LF PHEV Fuel Door Control Workshop Result



Timeout Value



P-CAN(EMS) : 0x1, 



C-CAN(CLU) : 0x0";
BA_ "GenSigSendType" SG_ 1097 PHEV_FuelDrCtrlFlag 4;
BA_ "UserSigValidity" SG_ 1097 PHEV_FuelDrCtrlFlag 0;
BA_ "NetworkRequest" SG_ 1097 PHEV_FuelDrCtrlFlag 0;
BA_ "NetworkRequestHoldingTime" SG_ 1097 PHEV_FuelDrCtrlFlag 5000;
BA_ "Version" SG_ 1097 PHEV_FuelDrCtrlFlag "18.12.03";
BA_ "Description" SG_ 1097 Haptic_USMCurState_OnOff "Response for Haptic Steering Wheel Mode Status (On/Off Type)";
BA_ "GenSigSendType" SG_ 1097 Haptic_USMCurState_OnOff 4;
BA_ "UserSigValidity" SG_ 1097 Haptic_USMCurState_OnOff 0;
BA_ "NetworkRequest" SG_ 1097 Haptic_USMCurState_OnOff 0;
BA_ "NetworkRequestHoldingTime" SG_ 1097 Haptic_USMCurState_OnOff 5000;
BA_ "Version" SG_ 1097 Haptic_USMCurState_OnOff "21.03.06";
BA_ "Description" SG_ 1097 Haptic_ADASAutoOnSetReq "Request to Active Automatically for Warning of DRV Assist System";
BA_ "GenSigSendType" SG_ 1097 Haptic_ADASAutoOnSetReq 4;
BA_ "UserSigValidity" SG_ 1097 Haptic_ADASAutoOnSetReq 0;
BA_ "NetworkRequest" SG_ 1097 Haptic_ADASAutoOnSetReq 0;
BA_ "NetworkRequestHoldingTime" SG_ 1097 Haptic_ADASAutoOnSetReq 5000;
BA_ "Version" SG_ 1097 Haptic_ADASAutoOnSetReq "20.08.02";
BA_ "Description" SG_ 1097 HeatedSteerWheel_StrWhlHtrSwSta_BCM "This signal is used to sent information of current state of Steering Wheel Heated SW.";
BA_ "GenSigSendType" SG_ 1097 HeatedSteerWheel_StrWhlHtrSwSta_BCM 4;
BA_ "UserSigValidity" SG_ 1097 HeatedSteerWheel_StrWhlHtrSwSta_BCM 0;
BA_ "NetworkRequest" SG_ 1097 HeatedSteerWheel_StrWhlHtrSwSta_BCM 0;
BA_ "NetworkRequestHoldingTime" SG_ 1097 HeatedSteerWheel_StrWhlHtrSwSta_BCM 5000;
BA_ "Version" SG_ 1097 HeatedSteerWheel_StrWhlHtrSwSta_BCM "17.12.00";
BA_ "Description" SG_ 1097 Haptic_WrngCmd "Haptic Motor Command";
BA_ "GenSigSendType" SG_ 1097 Haptic_WrngCmd 4;
BA_ "UserSigValidity" SG_ 1097 Haptic_WrngCmd 0;
BA_ "NetworkRequest" SG_ 1097 Haptic_WrngCmd 0;
BA_ "NetworkRequestHoldingTime" SG_ 1097 Haptic_WrngCmd 5000;
BA_ "Version" SG_ 1097 Haptic_WrngCmd "21.10.05";
BA_ "NmNode" BU_ vDummy_HS_B 0;
BA_ "GenMsgCycleTime" BO_ 2202063617 0;
BA_ "VFrameFormat" BO_ 2202063617 1;
BA_ "Description" SG_ 2202063617 CCU_AP_OTA_Crc4Val "The data area for CRC calculation is based on the data length (DLC) of the message DB.

The CRC shall be calculated over the entire data block (excluding the CRC bytes) including the user data, alive counter and Data ID



- CRC Polynomial (0x1021) , Initial Value : 0xFFFF, XOR value : 0x0000, Data ID : Message ID + 0xF800 

- The initial value is for CRC calculation and the message should be sent with the calculated result value. 

- The mathematical expression to 16 bit CRC polynomial is given here. G(x) = x16 + x12 + x5 + 1



<For CRC calculation of CAN-FD Msg for HS CAN domain ECUs>



- HS-CAN Messages that routed from CAN-FD domain are using 29 bit Extended CAN ID and splitted into 8 Byte Messages.

(from 1 to 4 Msgs, depending on source CAN-FD Msg¡¯s DLC)

- For splitted CAN-FD Msgs¡¯ CRC calculation, HS CAN ECUs should use source CAN-FD Msg¡¯s original STD ID. 

- The original STD ID can be read from Ext ID¡¯s 4~6th Byte.

Eg. STD 0x6AA : EXT SPLT 0x1A8[6AA]01 / 0x1A8[6AA]02 / 0x1A8[6AA]03 / 0x1A8[6AA]04 

(2~4th splitited Msgs can be omitted depending on source CAN-FD Msg¡¯s DLC)

- Aslo, HS-CAN ECUs should use merged data block (from whole splitted Msg) for CRC calculation.";
BA_ "GenSigSendType" SG_ 2202063617 CCU_AP_OTA_Crc4Val 4;
BA_ "GenSigStartValue" SG_ 2202063617 CCU_AP_OTA_Crc4Val 65535;
BA_ "UserSigValidity" SG_ 2202063617 CCU_AP_OTA_Crc4Val 3;
BA_REL_ "GenSigTimeoutTime" BU_SG_REL_ vDummy_HS_B SG_ 2202063617 CCU_AP_OTA_Crc4Val 0;
BA_ "Version" SG_ 2202063617 CCU_AP_OTA_Crc4Val "21.09.03";
BA_ "Description" SG_ 2202063617 CCU_AP_OTA_AlvCnt4Val "For the first transmission request for a data element the counter shall be initialized with 0 and shall be incremented by 1 for every subsequent send request. 

When the counter reaches the maximum value(0xFF), then it shall restart with 0 for the next send request";
BA_ "GenSigSendType" SG_ 2202063617 CCU_AP_OTA_AlvCnt4Val 4;
BA_ "UserSigValidity" SG_ 2202063617 CCU_AP_OTA_AlvCnt4Val 3;
BA_REL_ "GenSigTimeoutTime" BU_SG_REL_ vDummy_HS_B SG_ 2202063617 CCU_AP_OTA_AlvCnt4Val 0;
BA_ "Version" SG_ 2202063617 CCU_AP_OTA_AlvCnt4Val "21.09.03";
BA_ "Description" SG_ 2202063617 CCU_OTA_Update_time "¾÷µ¥ÀÌÆ® ¿¹»ó½Ã°£";
BA_ "GenSigSendType" SG_ 2202063617 CCU_OTA_Update_time 4;
BA_ "UserSigValidity" SG_ 2202063617 CCU_OTA_Update_time 0;
BA_ "Version" SG_ 2202063617 CCU_OTA_Update_time "19.12.08";
BA_ "Description" SG_ 2202063617 CCU_OTA_Update_Current "¾÷µ¥ÀÌÆ®½Ã Ãß°¡ ¼Ò¸ðÀü·ù";
BA_ "GenSigSendType" SG_ 2202063617 CCU_OTA_Update_Current 4;
BA_ "UserSigValidity" SG_ 2202063617 CCU_OTA_Update_Current 0;
BA_ "Version" SG_ 2202063617 CCU_OTA_Update_Current "19.12.08";
BA_ "GenSigSendType" SG_ 2202063617 CCU_Update_Calfactor 4;
BA_ "UserSigValidity" SG_ 2202063617 CCU_Update_Calfactor 0;
BA_ "Version" SG_ 2202063617 CCU_Update_Calfactor "19.12.07";
BA_ "NmStationAddress" BU_ EMCU 17;
BA_ "NmStationAddress" BU_ RCS 70;
BA_ "GenMsgSendType" BO_ 1132 0;
BA_ "Description" SG_ 1132 DLBCU_CushInfDis "This signal is used to display the seat movement to AVN";
BA_ "GenSigSendType" SG_ 1132 DLBCU_CushInfDis 4;
BA_ "UserSigValidity" SG_ 1132 DLBCU_CushInfDis 1;
BA_REL_ "GenSigTimeoutTime" BU_SG_REL_ CGW_CCU SG_ 1132 DLBCU_CushInfDis 1500;
BA_REL_ "GenSigTimeoutTime" BU_SG_REL_ GW_DPSU SG_ 1132 DLBCU_CushInfDis 1500;
BA_ "NetworkRequest" SG_ 1132 DLBCU_CushInfDis 0;
BA_ "NetworkRequestHoldingTime" SG_ 1132 DLBCU_CushInfDis 5000;
BA_ "Version" SG_ 1132 DLBCU_CushInfDis "18.03.07";
BA_ "Description" SG_ 1132 DLBCU_CushDefDis "This signal is used to display the seat movement to AVN";
BA_ "GenSigSendType" SG_ 1132 DLBCU_CushDefDis 4;
BA_ "UserSigValidity" SG_ 1132 DLBCU_CushDefDis 1;
BA_REL_ "GenSigTimeoutTime" BU_SG_REL_ CGW_CCU SG_ 1132 DLBCU_CushDefDis 1500;
BA_REL_ "GenSigTimeoutTime" BU_SG_REL_ GW_DPSU SG_ 1132 DLBCU_CushDefDis 1500;
BA_ "NetworkRequest" SG_ 1132 DLBCU_CushDefDis 0;
BA_ "NetworkRequestHoldingTime" SG_ 1132 DLBCU_CushDefDis 5000;
BA_ "Version" SG_ 1132 DLBCU_CushDefDis "18.03.07";
BA_ "GenMsgSendType" BO_ 1105 0;
BA_ "GenSigSendType" SG_ 1105 FCS_FrLftStClrSwSta 4;
BA_ "UserSigValidity" SG_ 1105 FCS_FrLftStClrSwSta 7;
BA_REL_ "GenSigTimeoutTime" BU_SG_REL_ GW_APSU SG_ 1105 FCS_FrLftStClrSwSta 1500;
BA_REL_ "GenSigTimeoutTime" BU_SG_REL_ SHVU_FR SG_ 1105 FCS_FrLftStClrSwSta 1500;
BA_ "NetworkRequest" SG_ 1105 FCS_FrLftStClrSwSta 0;
BA_ "NetworkRequestHoldingTime" SG_ 1105 FCS_FrLftStClrSwSta 5000;
BA_ "Version" SG_ 1105 FCS_FrLftStClrSwSta "19.11.05";
BA_ "GenSigSendType" SG_ 1105 HeatedSteerWheel_SwSta 4;
BA_ "UserSigValidity" SG_ 1105 HeatedSteerWheel_SwSta 7;
BA_REL_ "GenSigTimeoutTime" BU_SG_REL_ CGW_CCU SG_ 1105 HeatedSteerWheel_SwSta 1500;
BA_ "NetworkRequest" SG_ 1105 HeatedSteerWheel_SwSta 0;
BA_ "NetworkRequestHoldingTime" SG_ 1105 HeatedSteerWheel_SwSta 5000;
BA_ "Version" SG_ 1105 HeatedSteerWheel_SwSta "19.11.05";
BA_ "Description" SG_ 1105 FCS_DrvDrAtClsSwSta "FCS_DriveDoorAutoClosingSwitchStatus";
BA_ "GenSigSendType" SG_ 1105 FCS_DrvDrAtClsSwSta 4;
BA_ "UserSigValidity" SG_ 1105 FCS_DrvDrAtClsSwSta 0;
BA_REL_ "GenSigTimeoutTime" BU_SG_REL_ CGW_CCU SG_ 1105 FCS_DrvDrAtClsSwSta 1500;
BA_REL_ "GenSigTimeoutTime" BU_SG_REL_ SHVU_FR SG_ 1105 FCS_DrvDrAtClsSwSta 1500;
BA_ "NetworkRequest" SG_ 1105 FCS_DrvDrAtClsSwSta 0;
BA_ "NetworkRequestHoldingTime" SG_ 1105 FCS_DrvDrAtClsSwSta 5000;
BA_ "Version" SG_ 1105 FCS_DrvDrAtClsSwSta "19.11.05";
BA_ "Description" SG_ 1105 FCS_AstDrAtClsSwSta "FCS_AssistDoorAutoClosingSwitchStatus";
BA_ "GenSigSendType" SG_ 1105 FCS_AstDrAtClsSwSta 4;
BA_ "UserSigValidity" SG_ 1105 FCS_AstDrAtClsSwSta 0;
BA_REL_ "GenSigTimeoutTime" BU_SG_REL_ CGW_CCU SG_ 1105 FCS_AstDrAtClsSwSta 1500;
BA_REL_ "GenSigTimeoutTime" BU_SG_REL_ SHVU_FR SG_ 1105 FCS_AstDrAtClsSwSta 1500;
BA_ "NetworkRequest" SG_ 1105 FCS_AstDrAtClsSwSta 0;
BA_ "NetworkRequestHoldingTime" SG_ 1105 FCS_AstDrAtClsSwSta 5000;
BA_ "Version" SG_ 1105 FCS_AstDrAtClsSwSta "19.11.05";
BA_ "Description" SG_ 1105 FCS_DrvModeSwSta "FCS_DriveModeSwitchStatus";
BA_ "GenSigSendType" SG_ 1105 FCS_DrvModeSwSta 4;
BA_ "UserSigValidity" SG_ 1105 FCS_DrvModeSwSta 3;
BA_REL_ "GenSigTimeoutTime" BU_SG_REL_ CGW_CCU SG_ 1105 FCS_DrvModeSwSta 1500;
BA_REL_ "GenSigTimeoutTime" BU_SG_REL_ SHVU_FR SG_ 1105 FCS_DrvModeSwSta 1500;
BA_ "NetworkRequest" SG_ 1105 FCS_DrvModeSwSta 0;
BA_ "NetworkRequestHoldingTime" SG_ 1105 FCS_DrvModeSwSta 5000;
BA_ "Version" SG_ 1105 FCS_DrvModeSwSta "19.11.05";
BA_ "Description" SG_ 1105 FCS_PDWSwSta "FCS_ParkingAssistSystemSwitchStatus";
BA_ "GenSigSendType" SG_ 1105 FCS_PDWSwSta 4;
BA_ "UserSigValidity" SG_ 1105 FCS_PDWSwSta 3;
BA_REL_ "GenSigTimeoutTime" BU_SG_REL_ CGW_CCU SG_ 1105 FCS_PDWSwSta 1500;
BA_ "NetworkRequest" SG_ 1105 FCS_PDWSwSta 0;
BA_ "NetworkRequestHoldingTime" SG_ 1105 FCS_PDWSwSta 5000;
BA_ "Version" SG_ 1105 FCS_PDWSwSta "19.11.05";
BA_ "GenSigSendType" SG_ 1105 FCS_FrLftStHtrSwSta 4;
BA_ "UserSigValidity" SG_ 1105 FCS_FrLftStHtrSwSta 7;
BA_REL_ "GenSigTimeoutTime" BU_SG_REL_ GW_APSU SG_ 1105 FCS_FrLftStHtrSwSta 1500;
BA_REL_ "GenSigTimeoutTime" BU_SG_REL_ SHVU_FR SG_ 1105 FCS_FrLftStHtrSwSta 1500;
BA_ "NetworkRequest" SG_ 1105 FCS_FrLftStHtrSwSta 0;
BA_ "NetworkRequestHoldingTime" SG_ 1105 FCS_FrLftStHtrSwSta 5000;
BA_ "Version" SG_ 1105 FCS_FrLftStHtrSwSta "19.11.05";
BA_ "Description" SG_ 1105 FCS_Beep1Sound "Play floor console thouch switch beep sound";
BA_ "GenSigSendType" SG_ 1105 FCS_Beep1Sound 4;
BA_ "UserSigValidity" SG_ 1105 FCS_Beep1Sound 3;
BA_REL_ "GenSigTimeoutTime" BU_SG_REL_ CGW_CCU SG_ 1105 FCS_Beep1Sound 1500;
BA_ "NetworkRequest" SG_ 1105 FCS_Beep1Sound 0;
BA_ "NetworkRequestHoldingTime" SG_ 1105 FCS_Beep1Sound 5000;
BA_ "Version" SG_ 1105 FCS_Beep1Sound "21.09.05";
BA_ "Description" SG_ 1105 FCS_LockTrayMsgDisp "This signal indicates ATS message displacement of Lock tray password settings.";
BA_ "GenSigSendType" SG_ 1105 FCS_LockTrayMsgDisp 4;
BA_ "UserSigValidity" SG_ 1105 FCS_LockTrayMsgDisp 1;
BA_REL_ "GenSigTimeoutTime" BU_SG_REL_ ATS SG_ 1105 FCS_LockTrayMsgDisp 1500;
BA_ "Version" SG_ 1105 FCS_LockTrayMsgDisp "21.01.02";
BA_ "Description" SG_ 1105 FCS_LockTrayStatDisp "This signal indicate ATS state displacement of Lock tray present conditions.";
BA_ "GenSigSendType" SG_ 1105 FCS_LockTrayStatDisp 4;
BA_ "UserSigValidity" SG_ 1105 FCS_LockTrayStatDisp 1;
BA_REL_ "GenSigTimeoutTime" BU_SG_REL_ ATS SG_ 1105 FCS_LockTrayStatDisp 1500;
BA_ "Version" SG_ 1105 FCS_LockTrayStatDisp "21.01.02";
BA_ "Description" SG_ 1105 FCS_LockTrayPwNoDisp "This signal indicate ATS input password state of Lock tray password number.";
BA_ "GenSigSendType" SG_ 1105 FCS_LockTrayPwNoDisp 4;
BA_ "UserSigValidity" SG_ 1105 FCS_LockTrayPwNoDisp 1;
BA_REL_ "GenSigTimeoutTime" BU_SG_REL_ ATS SG_ 1105 FCS_LockTrayPwNoDisp 1500;
BA_ "Version" SG_ 1105 FCS_LockTrayPwNoDisp "21.01.06";
BA_ "Description" SG_ 1105 FCS_LockTrayTxtPopupReq "This signal indicate ATS OSD of Lock tray text pop-up request on.";
BA_ "GenSigSendType" SG_ 1105 FCS_LockTrayTxtPopupReq 4;
BA_ "UserSigValidity" SG_ 1105 FCS_LockTrayTxtPopupReq 1;
BA_REL_ "GenSigTimeoutTime" BU_SG_REL_ ATS SG_ 1105 FCS_LockTrayTxtPopupReq 1500;
BA_ "Version" SG_ 1105 FCS_LockTrayTxtPopupReq "21.01.02";
BA_ "Description" SG_ 1105 FCS_LockTrayOSD "This signal indicate ATS OSD of Locktray text message when event done.";
BA_ "GenSigSendType" SG_ 1105 FCS_LockTrayOSD 4;
BA_ "UserSigValidity" SG_ 1105 FCS_LockTrayOSD 1;
BA_REL_ "GenSigTimeoutTime" BU_SG_REL_ ATS SG_ 1105 FCS_LockTrayOSD 1500;
BA_ "Version" SG_ 1105 FCS_LockTrayOSD "21.01.02";
BA_ "Description" SG_ 1105 FCS_FrDrvArmrestHeatedLvl "Present operation status (Off/Low/Mid/High) of the driver armrest warmer on phone app";
BA_ "GenSigSendType" SG_ 1105 FCS_FrDrvArmrestHeatedLvl 4;
BA_ "UserSigValidity" SG_ 1105 FCS_FrDrvArmrestHeatedLvl 3;
BA_REL_ "GenSigTimeoutTime" BU_SG_REL_ CGW_CCU SG_ 1105 FCS_FrDrvArmrestHeatedLvl 1500;
BA_ "Version" SG_ 1105 FCS_FrDrvArmrestHeatedLvl "23.02.06";
BA_ "Description" SG_ 1105 FCS_FrAstArmrestHeatedLvl "Present operation status (Off/Low/Mid/High) of the front passenger(or assistant) armrest warmer on phone app";
BA_ "GenSigSendType" SG_ 1105 FCS_FrAstArmrestHeatedLvl 4;
BA_ "UserSigValidity" SG_ 1105 FCS_FrAstArmrestHeatedLvl 3;
BA_REL_ "GenSigTimeoutTime" BU_SG_REL_ CGW_CCU SG_ 1105 FCS_FrAstArmrestHeatedLvl 1500;
BA_ "Version" SG_ 1105 FCS_FrAstArmrestHeatedLvl "23.02.06";
BA_ "GenSigSendType" SG_ 1105 FCS_FrRtStClrSwSta 4;
BA_ "UserSigValidity" SG_ 1105 FCS_FrRtStClrSwSta 7;
BA_REL_ "GenSigTimeoutTime" BU_SG_REL_ GW_APSU SG_ 1105 FCS_FrRtStClrSwSta 1500;
BA_REL_ "GenSigTimeoutTime" BU_SG_REL_ SHVU_FR SG_ 1105 FCS_FrRtStClrSwSta 1500;
BA_ "NetworkRequest" SG_ 1105 FCS_FrRtStClrSwSta 0;
BA_ "NetworkRequestHoldingTime" SG_ 1105 FCS_FrRtStClrSwSta 5000;
BA_ "Version" SG_ 1105 FCS_FrRtStClrSwSta "19.11.05";
BA_ "GenSigSendType" SG_ 1105 FCS_FrArmrestHeatedTyp 4;
BA_ "UserSigValidity" SG_ 1105 FCS_FrArmrestHeatedTyp 3;
BA_REL_ "GenSigTimeoutTime" BU_SG_REL_ CGW_CCU SG_ 1105 FCS_FrArmrestHeatedTyp 1500;
BA_ "NetworkRequest" SG_ 1105 FCS_FrArmrestHeatedTyp 0;
BA_ "NetworkRequestHoldingTime" SG_ 1105 FCS_FrArmrestHeatedTyp 5000;
BA_ "Version" SG_ 1105 FCS_FrArmrestHeatedTyp "22.05.02";
BA_ "GenSigSendType" SG_ 1105 FCS_RrArmrestHeatedTyp 4;
BA_ "UserSigValidity" SG_ 1105 FCS_RrArmrestHeatedTyp 3;
BA_REL_ "GenSigTimeoutTime" BU_SG_REL_ CGW_CCU SG_ 1105 FCS_RrArmrestHeatedTyp 1500;
BA_ "NetworkRequest" SG_ 1105 FCS_RrArmrestHeatedTyp 0;
BA_ "NetworkRequestHoldingTime" SG_ 1105 FCS_RrArmrestHeatedTyp 5000;
BA_ "Version" SG_ 1105 FCS_RrArmrestHeatedTyp "22.05.02";
BA_ "Description" SG_ 1105 FCS_RrLhArmrestHeatedLvl "Present operation status (Off/Low/Mid/High) of the rear left armrest warmer on phone app";
BA_ "GenSigSendType" SG_ 1105 FCS_RrLhArmrestHeatedLvl 4;
BA_ "UserSigValidity" SG_ 1105 FCS_RrLhArmrestHeatedLvl 3;
BA_REL_ "GenSigTimeoutTime" BU_SG_REL_ CGW_CCU SG_ 1105 FCS_RrLhArmrestHeatedLvl 1500;
BA_ "Version" SG_ 1105 FCS_RrLhArmrestHeatedLvl "23.02.06";
BA_ "GenSigSendType" SG_ 1105 FCS_DrvTerrModeDirSwSta 4;
BA_ "UserSigValidity" SG_ 1105 FCS_DrvTerrModeDirSwSta 3;
BA_REL_ "GenSigTimeoutTime" BU_SG_REL_ CGW_CCU SG_ 1105 FCS_DrvTerrModeDirSwSta 1500;
BA_ "Version" SG_ 1105 FCS_DrvTerrModeDirSwSta "22.11.03";
BA_ "GenSigSendType" SG_ 1105 FCS_DrvTerrModeSwSta 4;
BA_ "UserSigValidity" SG_ 1105 FCS_DrvTerrModeSwSta 3;
BA_REL_ "GenSigTimeoutTime" BU_SG_REL_ CGW_CCU SG_ 1105 FCS_DrvTerrModeSwSta 1500;
BA_ "Version" SG_ 1105 FCS_DrvTerrModeSwSta "22.11.03";
BA_ "GenSigSendType" SG_ 1105 CF_FCS_4wdLocking 4;
BA_ "UserSigValidity" SG_ 1105 CF_FCS_4wdLocking 3;
BA_REL_ "GenSigTimeoutTime" BU_SG_REL_ CGW_CCU SG_ 1105 CF_FCS_4wdLocking 1500;
BA_ "Version" SG_ 1105 CF_FCS_4wdLocking "22.11.03";
BA_ "Description" SG_ 1105 FCS_FrDrvArmrestHeated "Set on/off the function that the driver armrest warmer adjusts automatically based on the driver seat warmer.";
BA_ "GenSigSendType" SG_ 1105 FCS_FrDrvArmrestHeated 4;
BA_ "UserSigValidity" SG_ 1105 FCS_FrDrvArmrestHeated 3;
BA_REL_ "GenSigTimeoutTime" BU_SG_REL_ CGW_CCU SG_ 1105 FCS_FrDrvArmrestHeated 1500;
BA_ "Version" SG_ 1105 FCS_FrDrvArmrestHeated "23.01.01";
BA_ "Description" SG_ 1105 FCS_FrAstArmrestHeated "Set on/off the function that the front passenger(or assistant) armrest warmer adjusts automatically based on the front passenger seat warmer.";
BA_ "GenSigSendType" SG_ 1105 FCS_FrAstArmrestHeated 4;
BA_ "UserSigValidity" SG_ 1105 FCS_FrAstArmrestHeated 3;
BA_REL_ "GenSigTimeoutTime" BU_SG_REL_ CGW_CCU SG_ 1105 FCS_FrAstArmrestHeated 1500;
BA_ "Version" SG_ 1105 FCS_FrAstArmrestHeated "23.01.01";
BA_ "Description" SG_ 1105 FCS_RrLhArmrestHeated "Set on/off the function that the rear left armrest warmer adjusts automatically based on rear left seat warmer.";
BA_ "GenSigSendType" SG_ 1105 FCS_RrLhArmrestHeated 4;
BA_ "UserSigValidity" SG_ 1105 FCS_RrLhArmrestHeated 3;
BA_REL_ "GenSigTimeoutTime" BU_SG_REL_ CGW_CCU SG_ 1105 FCS_RrLhArmrestHeated 1500;
BA_ "Version" SG_ 1105 FCS_RrLhArmrestHeated "23.01.01";
BA_ "Description" SG_ 1105 FCS_RrRhArmrestHeated "Set on/off the function that the rear right armrest warmer adjusts automatically based on rear right seat warmer.";
BA_ "GenSigSendType" SG_ 1105 FCS_RrRhArmrestHeated 4;
BA_ "UserSigValidity" SG_ 1105 FCS_RrRhArmrestHeated 3;
BA_REL_ "GenSigTimeoutTime" BU_SG_REL_ CGW_CCU SG_ 1105 FCS_RrRhArmrestHeated 1500;
BA_ "Version" SG_ 1105 FCS_RrRhArmrestHeated "23.01.01";
BA_ "GenSigSendType" SG_ 1105 FCS_FrRtStHtrSwSta 4;
BA_ "UserSigValidity" SG_ 1105 FCS_FrRtStHtrSwSta 7;
BA_REL_ "GenSigTimeoutTime" BU_SG_REL_ GW_APSU SG_ 1105 FCS_FrRtStHtrSwSta 1500;
BA_REL_ "GenSigTimeoutTime" BU_SG_REL_ SHVU_FR SG_ 1105 FCS_FrRtStHtrSwSta 1500;
BA_ "NetworkRequest" SG_ 1105 FCS_FrRtStHtrSwSta 0;
BA_ "NetworkRequestHoldingTime" SG_ 1105 FCS_FrRtStHtrSwSta 5000;
BA_ "Version" SG_ 1105 FCS_FrRtStHtrSwSta "19.11.05";
BA_ "Description" SG_ 1105 FCS_RrRhArmrestHeatedLvl "Present operation status (Off/Low/Mid/High) of the rear right armrest warmer on phone app";
BA_ "GenSigSendType" SG_ 1105 FCS_RrRhArmrestHeatedLvl 4;
BA_ "UserSigValidity" SG_ 1105 FCS_RrRhArmrestHeatedLvl 3;
BA_REL_ "GenSigTimeoutTime" BU_SG_REL_ CGW_CCU SG_ 1105 FCS_RrRhArmrestHeatedLvl 1500;
BA_ "Version" SG_ 1105 FCS_RrRhArmrestHeatedLvl "23.02.06";
BA_ "GenSigSendType" SG_ 1105 FCS_RrCurtainSwSta 4;
BA_ "UserSigValidity" SG_ 1105 FCS_RrCurtainSwSta 7;
BA_ "NetworkRequest" SG_ 1105 FCS_RrCurtainSwSta 0;
BA_ "NetworkRequestHoldingTime" SG_ 1105 FCS_RrCurtainSwSta 5000;
BA_ "Version" SG_ 1105 FCS_RrCurtainSwSta "19.11.05";
BA_ "NmNode" BU_ vHS_B2 0;
BA_ "NmStationAddress" BU_ SLB 27;
BA_ "GenMsgCycleTime" BO_ 1113 0;
BA_ "Description" SG_ 1113 C_LH_Folding_State_PopUp "3rd LH seat Moving Finish / Mode-Fail signal";
BA_ "GenSigSendType" SG_ 1113 C_LH_Folding_State_PopUp 4;
BA_ "UserSigValidity" SG_ 1113 C_LH_Folding_State_PopUp 0;
BA_REL_ "GenSigTimeoutTime" BU_SG_REL_ CGW_CCU SG_ 1113 C_LH_Folding_State_PopUp 0;
BA_REL_ "GenSigTimeoutTime" BU_SG_REL_ GW_APSU SG_ 1113 C_LH_Folding_State_PopUp 0;
BA_ "NetworkRequest" SG_ 1113 C_LH_Folding_State_PopUp 0;
BA_ "NetworkRequestHoldingTime" SG_ 1113 C_LH_Folding_State_PopUp 5000;
BA_ "Version" SG_ 1113 C_LH_Folding_State_PopUp "22.11.00";
BA_ "Description" SG_ 1113 PFSU_RLLnkRtnStop "In the event of an impossible situation during the seat movement in the 3rd row TL side by the 2nd row RL side relaxation action.";
BA_ "GenSigSendType" SG_ 1113 PFSU_RLLnkRtnStop 4;
BA_ "UserSigValidity" SG_ 1113 PFSU_RLLnkRtnStop 0;
BA_REL_ "GenSigTimeoutTime" BU_SG_REL_ GW_RLPSU SG_ 1113 PFSU_RLLnkRtnStop 0;
BA_ "NetworkRequest" SG_ 1113 PFSU_RLLnkRtnStop 0;
BA_ "NetworkRequestHoldingTime" SG_ 1113 PFSU_RLLnkRtnStop 5000;
BA_ "Version" SG_ 1113 PFSU_RLLnkRtnStop "22.05.03";
BA_ "Description" SG_ 1113 PFSU_RLStStdPosMovReq_Fold "3¿­ TLÃø Æúµù/¾ðÆúµù µ¿ÀÛ¿¡ ÀÇÇÑ 2¿­ RL ½ÃÆ® ÀÌµ¿ ¿äÃ» ½ÅÈ£";
BA_ "GenSigSendType" SG_ 1113 PFSU_RLStStdPosMovReq_Fold 4;
BA_ "UserSigValidity" SG_ 1113 PFSU_RLStStdPosMovReq_Fold 0;
BA_REL_ "GenSigTimeoutTime" BU_SG_REL_ GW_RLPSU SG_ 1113 PFSU_RLStStdPosMovReq_Fold 0;
BA_ "NetworkRequest" SG_ 1113 PFSU_RLStStdPosMovReq_Fold 0;
BA_ "NetworkRequestHoldingTime" SG_ 1113 PFSU_RLStStdPosMovReq_Fold 5000;
BA_ "Version" SG_ 1113 PFSU_RLStStdPosMovReq_Fold "22.05.02";
BA_ "Description" SG_ 1113 PFSU_3RAMPBzrReq "3rd Right SEAT IMS Buzzer Request for AMP or Inner Speaker";
BA_ "GenSigSendType" SG_ 1113 PFSU_3RAMPBzrReq 4;
BA_ "UserSigValidity" SG_ 1113 PFSU_3RAMPBzrReq 0;
BA_REL_ "GenSigTimeoutTime" BU_SG_REL_ CGW_CCU SG_ 1113 PFSU_3RAMPBzrReq 0;
BA_ "NetworkRequest" SG_ 1113 PFSU_3RAMPBzrReq 0;
BA_ "NetworkRequestHoldingTime" SG_ 1113 PFSU_3RAMPBzrReq 5000;
BA_ "Version" SG_ 1113 PFSU_3RAMPBzrReq "22.11.00";
BA_ "Description" SG_ 1113 PFSU_3LAMPBzrReq "3rd Left SEAT IMS Buzzer Request for AMP or Inner Speaker";
BA_ "GenSigSendType" SG_ 1113 PFSU_3LAMPBzrReq 4;
BA_ "UserSigValidity" SG_ 1113 PFSU_3LAMPBzrReq 0;
BA_REL_ "GenSigTimeoutTime" BU_SG_REL_ CGW_CCU SG_ 1113 PFSU_3LAMPBzrReq 0;
BA_ "NetworkRequest" SG_ 1113 PFSU_3LAMPBzrReq 0;
BA_ "NetworkRequestHoldingTime" SG_ 1113 PFSU_3LAMPBzrReq 5000;
BA_ "Version" SG_ 1113 PFSU_3LAMPBzrReq "22.11.00";
BA_ "Description" SG_ 1113 C_RH_Folding_State_PopUp_2 "AVNT OSD PopUp For 3rd Seat Inoperable condition";
BA_ "GenSigSendType" SG_ 1113 C_RH_Folding_State_PopUp_2 4;
BA_ "UserSigValidity" SG_ 1113 C_RH_Folding_State_PopUp_2 0;
BA_REL_ "GenSigTimeoutTime" BU_SG_REL_ CGW_CCU SG_ 1113 C_RH_Folding_State_PopUp_2 0;
BA_ "NetworkRequest" SG_ 1113 C_RH_Folding_State_PopUp_2 0;
BA_ "NetworkRequestHoldingTime" SG_ 1113 C_RH_Folding_State_PopUp_2 5000;
BA_ "Version" SG_ 1113 C_RH_Folding_State_PopUp_2 "22.11.14";
BA_ "Description" SG_ 1113 C_LH_Folding_State_PopUp_2 "AVNT OSD PopUp For 3rd Seat Inoperable condition";
BA_ "GenSigSendType" SG_ 1113 C_LH_Folding_State_PopUp_2 4;
BA_ "UserSigValidity" SG_ 1113 C_LH_Folding_State_PopUp_2 0;
BA_REL_ "GenSigTimeoutTime" BU_SG_REL_ CGW_CCU SG_ 1113 C_LH_Folding_State_PopUp_2 0;
BA_ "NetworkRequest" SG_ 1113 C_LH_Folding_State_PopUp_2 0;
BA_ "NetworkRequestHoldingTime" SG_ 1113 C_LH_Folding_State_PopUp_2 5000;
BA_ "Version" SG_ 1113 C_LH_Folding_State_PopUp_2 "22.11.14";
BA_ "Description" SG_ 1113 C_RH_Folding_State_PopUp "3rd RH seat Moving Finish / Mode-Fail signal";
BA_ "GenSigSendType" SG_ 1113 C_RH_Folding_State_PopUp 4;
BA_ "UserSigValidity" SG_ 1113 C_RH_Folding_State_PopUp 0;
BA_REL_ "GenSigTimeoutTime" BU_SG_REL_ CGW_CCU SG_ 1113 C_RH_Folding_State_PopUp 0;
BA_REL_ "GenSigTimeoutTime" BU_SG_REL_ GW_APSU SG_ 1113 C_RH_Folding_State_PopUp 0;
BA_ "NetworkRequest" SG_ 1113 C_RH_Folding_State_PopUp 0;
BA_ "NetworkRequestHoldingTime" SG_ 1113 C_RH_Folding_State_PopUp 5000;
BA_ "Version" SG_ 1113 C_RH_Folding_State_PopUp "22.11.00";
BA_ "Description" SG_ 1113 PFSU_RRLnkRtnStop "In the event of an impossible situation during the seat movement in the 3rd row TR side by the 2nd row RR side relaxation action.";
BA_ "GenSigSendType" SG_ 1113 PFSU_RRLnkRtnStop 4;
BA_ "UserSigValidity" SG_ 1113 PFSU_RRLnkRtnStop 0;
BA_REL_ "GenSigTimeoutTime" BU_SG_REL_ GW_RRPSU SG_ 1113 PFSU_RRLnkRtnStop 0;
BA_ "NetworkRequest" SG_ 1113 PFSU_RRLnkRtnStop 0;
BA_ "NetworkRequestHoldingTime" SG_ 1113 PFSU_RRLnkRtnStop 5000;
BA_ "Version" SG_ 1113 PFSU_RRLnkRtnStop "22.05.03";
BA_ "Description" SG_ 1113 PFSU_RRStStdPosMovReq_Fold "3¿­ TRÃø Æúµù/¾ðÆúµù µ¿ÀÛ¿¡ ÀÇÇÑ 2¿­ RR ½ÃÆ® ÀÌµ¿ ¿äÃ» ½ÅÈ£";
BA_ "GenSigSendType" SG_ 1113 PFSU_RRStStdPosMovReq_Fold 4;
BA_ "UserSigValidity" SG_ 1113 PFSU_RRStStdPosMovReq_Fold 0;
BA_REL_ "GenSigTimeoutTime" BU_SG_REL_ GW_RRPSU SG_ 1113 PFSU_RRStStdPosMovReq_Fold 0;
BA_ "NetworkRequest" SG_ 1113 PFSU_RRStStdPosMovReq_Fold 0;
BA_ "NetworkRequestHoldingTime" SG_ 1113 PFSU_RRStStdPosMovReq_Fold 5000;
BA_ "Version" SG_ 1113 PFSU_RRStStdPosMovReq_Fold "22.05.02";
BA_ "GenMsgSendType" BO_ 1111 0;
BA_ "Description" SG_ 1111 C_LH_Folding_Position "3¿­ LH ½ÃÆ® ¹é ÇöÀç À§Ä¡ »óÅÂ Á¤º¸ ¼Û½Å

 - Seat Position Information signal for 3rd LH seat";
BA_ "GenSigSendType" SG_ 1111 C_LH_Folding_Position 4;
BA_ "UserSigValidity" SG_ 1111 C_LH_Folding_Position 0;
BA_REL_ "GenSigTimeoutTime" BU_SG_REL_ CGW_CCU SG_ 1111 C_LH_Folding_Position 1500;
BA_REL_ "GenSigTimeoutTime" BU_SG_REL_ GW_APSU SG_ 1111 C_LH_Folding_Position 1500;
BA_REL_ "GenSigTimeoutTime" BU_SG_REL_ GW_RLPSU SG_ 1111 C_LH_Folding_Position 1500;
BA_ "NetworkRequest" SG_ 1111 C_LH_Folding_Position 0;
BA_ "NetworkRequestHoldingTime" SG_ 1111 C_LH_Folding_Position 5000;
BA_ "Version" SG_ 1111 C_LH_Folding_Position "21.07.06";
BA_ "Description" SG_ 1111 PFSU_RH_ReclMtrPos "3¿­ RH ¸®Å¬¶óÀÌ³Ê Á¸¿¡ ´ëÇÑ Á¤º¸ Àü´Þ";
BA_ "GenSigSendType" SG_ 1111 PFSU_RH_ReclMtrPos 4;
BA_ "UserSigValidity" SG_ 1111 PFSU_RH_ReclMtrPos 0;
BA_ "NetworkRequest" SG_ 1111 PFSU_RH_ReclMtrPos 0;
BA_ "NetworkRequestHoldingTime" SG_ 1111 PFSU_RH_ReclMtrPos 5000;
BA_ "Version" SG_ 1111 PFSU_RH_ReclMtrPos "19.07.05";
BA_ "Description" SG_ 1111 PFSU_RL_Folding_SW "3¿­ Left Æúµù ½ºÀ§Ä¡¸¦ ¿¬µ¿ µ¿ÀÛ À§ÇØ 2¿­ Left¿¡ Àü´Þ

- 3rd LH Seat folding Information to 2nd LH Seat";
BA_ "GenSigSendType" SG_ 1111 PFSU_RL_Folding_SW 4;
BA_ "UserSigValidity" SG_ 1111 PFSU_RL_Folding_SW 0;
BA_REL_ "GenSigTimeoutTime" BU_SG_REL_ GW_RLPSU SG_ 1111 PFSU_RL_Folding_SW 1500;
BA_ "NetworkRequest" SG_ 1111 PFSU_RL_Folding_SW 0;
BA_ "NetworkRequestHoldingTime" SG_ 1111 PFSU_RL_Folding_SW 5000;
BA_ "Version" SG_ 1111 PFSU_RL_Folding_SW "18.05.00";
BA_ "Description" SG_ 1111 PFSU_RR_Folding_SW "3¿­ Right Æúµù ½ºÀ§Ä¡¸¦ ¿¬µ¿ µ¿ÀÛ À§ÇØ 2¿­ Right¿¡ Àü´Þ

- 3rd RH Seat folding Information to 2nd RH Seat";
BA_ "GenSigSendType" SG_ 1111 PFSU_RR_Folding_SW 4;
BA_ "UserSigValidity" SG_ 1111 PFSU_RR_Folding_SW 0;
BA_REL_ "GenSigTimeoutTime" BU_SG_REL_ GW_RLPSU SG_ 1111 PFSU_RR_Folding_SW 1500;
BA_REL_ "GenSigTimeoutTime" BU_SG_REL_ GW_RRPSU SG_ 1111 PFSU_RR_Folding_SW 1500;
BA_ "NetworkRequest" SG_ 1111 PFSU_RR_Folding_SW 0;
BA_ "NetworkRequestHoldingTime" SG_ 1111 PFSU_RR_Folding_SW 5000;
BA_ "Version" SG_ 1111 PFSU_RR_Folding_SW "18.05.00";
BA_ "Description" SG_ 1111 PFSU_RL_Unfolding_SW "3¿­ Left ¾ðÆúµù ½ºÀ§Ä¡¸¦ ¿¬µ¿ µ¿ÀÛ À§ÇØ 2¿­ Left¿¡ Àü´Þ

- 3rd LH Seat unfolding Information to 2nd LH Seat";
BA_ "GenSigSendType" SG_ 1111 PFSU_RL_Unfolding_SW 4;
BA_ "UserSigValidity" SG_ 1111 PFSU_RL_Unfolding_SW 0;
BA_REL_ "GenSigTimeoutTime" BU_SG_REL_ GW_RLPSU SG_ 1111 PFSU_RL_Unfolding_SW 1500;
BA_ "NetworkRequest" SG_ 1111 PFSU_RL_Unfolding_SW 0;
BA_ "NetworkRequestHoldingTime" SG_ 1111 PFSU_RL_Unfolding_SW 5000;
BA_ "Version" SG_ 1111 PFSU_RL_Unfolding_SW "18.05.00";
BA_ "Description" SG_ 1111 PFSU_RR_Unfolding_SW "3¿­ Right ¾ðÆúµù ½ºÀ§Ä¡¸¦ ¿¬µ¿ µ¿ÀÛ À§ÇØ 2¿­ Right¿¡ Àü´Þ

- 3rd RH Seat unfolding Information to 2nd RH Seat";
BA_ "GenSigSendType" SG_ 1111 PFSU_RR_Unfolding_SW 4;
BA_ "UserSigValidity" SG_ 1111 PFSU_RR_Unfolding_SW 0;
BA_REL_ "GenSigTimeoutTime" BU_SG_REL_ GW_RLPSU SG_ 1111 PFSU_RR_Unfolding_SW 1500;
BA_REL_ "GenSigTimeoutTime" BU_SG_REL_ GW_RRPSU SG_ 1111 PFSU_RR_Unfolding_SW 1500;
BA_ "NetworkRequest" SG_ 1111 PFSU_RR_Unfolding_SW 0;
BA_ "NetworkRequestHoldingTime" SG_ 1111 PFSU_RR_Unfolding_SW 5000;
BA_ "Version" SG_ 1111 PFSU_RR_Unfolding_SW "18.05.00";
BA_ "Description" SG_ 1111 C_RH_Folding_Position "3¿­ RH ½ÃÆ® ¹é ÇöÀç À§Ä¡ »óÅÂ Á¤º¸ ¼Û½Å

 - Seat Position Information signal for 3rd RH seat";
BA_ "GenSigSendType" SG_ 1111 C_RH_Folding_Position 4;
BA_ "UserSigValidity" SG_ 1111 C_RH_Folding_Position 0;
BA_REL_ "GenSigTimeoutTime" BU_SG_REL_ CGW_CCU SG_ 1111 C_RH_Folding_Position 1500;
BA_REL_ "GenSigTimeoutTime" BU_SG_REL_ GW_APSU SG_ 1111 C_RH_Folding_Position 1500;
BA_REL_ "GenSigTimeoutTime" BU_SG_REL_ GW_RLPSU SG_ 1111 C_RH_Folding_Position 1500;
BA_REL_ "GenSigTimeoutTime" BU_SG_REL_ GW_RRPSU SG_ 1111 C_RH_Folding_Position 1500;
BA_ "NetworkRequest" SG_ 1111 C_RH_Folding_Position 0;
BA_ "NetworkRequestHoldingTime" SG_ 1111 C_RH_Folding_Position 5000;
BA_ "Version" SG_ 1111 C_RH_Folding_Position "21.07.06";
BA_ "Description" SG_ 1111 PFSU_RR_FoldingDis "Third LH PSU Folding moving state: Folding";
BA_ "GenSigSendType" SG_ 1111 PFSU_RR_FoldingDis 4;
BA_ "UserSigValidity" SG_ 1111 PFSU_RR_FoldingDis 0;
BA_ "Version" SG_ 1111 PFSU_RR_FoldingDis "18.09.01";
BA_ "Description" SG_ 1111 PFSU_RR_UnfoldingDis "Third LH PSU Unfolding moving state: Unfolding";
BA_ "GenSigSendType" SG_ 1111 PFSU_RR_UnfoldingDis 4;
BA_ "UserSigValidity" SG_ 1111 PFSU_RR_UnfoldingDis 0;
BA_ "Version" SG_ 1111 PFSU_RR_UnfoldingDis "18.09.01";
BA_ "Description" SG_ 1111 PFSU_RL_FoldingDis "Third RH PSU Folding moving state: Folding";
BA_ "GenSigSendType" SG_ 1111 PFSU_RL_FoldingDis 4;
BA_ "UserSigValidity" SG_ 1111 PFSU_RL_FoldingDis 0;
BA_ "Version" SG_ 1111 PFSU_RL_FoldingDis "18.09.01";
BA_ "Description" SG_ 1111 PFSU_RL_UnfoldingDis "Third RH PSU Unfolding moving state: Unfolding";
BA_ "GenSigSendType" SG_ 1111 PFSU_RL_UnfoldingDis 4;
BA_ "UserSigValidity" SG_ 1111 PFSU_RL_UnfoldingDis 0;
BA_ "Version" SG_ 1111 PFSU_RL_UnfoldingDis "18.09.01";
BA_ "Description" SG_ 1111 PFSU_RR_HrstFoldingDis "Third RH H/rest Folding moving state: H/rest folding";
BA_ "GenSigSendType" SG_ 1111 PFSU_RR_HrstFoldingDis 4;
BA_ "UserSigValidity" SG_ 1111 PFSU_RR_HrstFoldingDis 0;
BA_REL_ "GenSigTimeoutTime" BU_SG_REL_ CGW_CCU SG_ 1111 PFSU_RR_HrstFoldingDis 1500;
BA_ "Version" SG_ 1111 PFSU_RR_HrstFoldingDis "18.09.01";
BA_ "Description" SG_ 1111 PFSU_RL_HrstFoldingDis "Third LH H/rest Folding moving state: H/rest folding";
BA_ "GenSigSendType" SG_ 1111 PFSU_RL_HrstFoldingDis 4;
BA_ "UserSigValidity" SG_ 1111 PFSU_RL_HrstFoldingDis 0;
BA_REL_ "GenSigTimeoutTime" BU_SG_REL_ CGW_CCU SG_ 1111 PFSU_RL_HrstFoldingDis 1500;
BA_ "Version" SG_ 1111 PFSU_RL_HrstFoldingDis "18.09.01";
BA_ "Description" SG_ 1111 PFSU_RR_SlideFwdDis "Third LH PSU Recliner FWD moving state";
BA_ "GenSigSendType" SG_ 1111 PFSU_RR_SlideFwdDis 4;
BA_ "UserSigValidity" SG_ 1111 PFSU_RR_SlideFwdDis 0;
BA_ "Version" SG_ 1111 PFSU_RR_SlideFwdDis "18.09.01";
BA_ "Description" SG_ 1111 PFSU_RR_SlidBwdDis "Third LH PSU Recliner BWD moving state";
BA_ "GenSigSendType" SG_ 1111 PFSU_RR_SlidBwdDis 4;
BA_ "UserSigValidity" SG_ 1111 PFSU_RR_SlidBwdDis 0;
BA_ "Version" SG_ 1111 PFSU_RR_SlidBwdDis "18.09.01";
BA_ "Description" SG_ 1111 PFSU_RL_SlideFwdDis "Third RH PSU Recliner FWD moving state";
BA_ "GenSigSendType" SG_ 1111 PFSU_RL_SlideFwdDis 4;
BA_ "UserSigValidity" SG_ 1111 PFSU_RL_SlideFwdDis 0;
BA_ "Version" SG_ 1111 PFSU_RL_SlideFwdDis "18.09.01";
BA_ "Description" SG_ 1111 PFSU_RL_SlideBwdDis "Third RH PSU Recliner BWD moving state";
BA_ "GenSigSendType" SG_ 1111 PFSU_RL_SlideBwdDis 4;
BA_ "UserSigValidity" SG_ 1111 PFSU_RL_SlideBwdDis 0;
BA_ "Version" SG_ 1111 PFSU_RL_SlideBwdDis "18.09.01";
BA_ "Description" SG_ 1111 PFSU_RRAutoRlxEnable "This is a conditioning signal for 2nd row right side seat relax function.";
BA_ "GenSigSendType" SG_ 1111 PFSU_RRAutoRlxEnable 4;
BA_ "UserSigValidity" SG_ 1111 PFSU_RRAutoRlxEnable 0;
BA_REL_ "GenSigTimeoutTime" BU_SG_REL_ GW_RRPSU SG_ 1111 PFSU_RRAutoRlxEnable 1500;
BA_ "NetworkRequest" SG_ 1111 PFSU_RRAutoRlxEnable 0;
BA_ "NetworkRequestHoldingTime" SG_ 1111 PFSU_RRAutoRlxEnable 5000;
BA_ "Version" SG_ 1111 PFSU_RRAutoRlxEnable "22.05.02";
BA_ "Description" SG_ 1111 PFSU_Opt "PFSU Option Information";
BA_ "GenSigSendType" SG_ 1111 PFSU_Opt 4;
BA_ "UserSigValidity" SG_ 1111 PFSU_Opt 0;
BA_REL_ "GenSigTimeoutTime" BU_SG_REL_ CGW_CCU SG_ 1111 PFSU_Opt 1500;
BA_ "Version" SG_ 1111 PFSU_Opt "21.07.06";
BA_ "Description" SG_ 1111 PFSU_RLAutoRlxEnable "This is a conditioning signal for 2nd row right side seat relax function.";
BA_ "GenSigSendType" SG_ 1111 PFSU_RLAutoRlxEnable 4;
BA_ "UserSigValidity" SG_ 1111 PFSU_RLAutoRlxEnable 0;
BA_REL_ "GenSigTimeoutTime" BU_SG_REL_ GW_RLPSU SG_ 1111 PFSU_RLAutoRlxEnable 1500;
BA_ "NetworkRequest" SG_ 1111 PFSU_RLAutoRlxEnable 0;
BA_ "NetworkRequestHoldingTime" SG_ 1111 PFSU_RLAutoRlxEnable 5000;
BA_ "Version" SG_ 1111 PFSU_RLAutoRlxEnable "22.05.02";
BA_ "Description" SG_ 1111 PFSU_LH_ReclMtrPos "3¿­ LH ¸®Å¬¶óÀÌ³Ê Á¸¿¡ ´ëÇÑ Á¤º¸ Àü´Þ";
BA_ "GenSigSendType" SG_ 1111 PFSU_LH_ReclMtrPos 4;
BA_ "UserSigValidity" SG_ 1111 PFSU_LH_ReclMtrPos 0;
BA_ "NetworkRequest" SG_ 1111 PFSU_LH_ReclMtrPos 0;
BA_ "NetworkRequestHoldingTime" SG_ 1111 PFSU_LH_ReclMtrPos 5000;
BA_ "Version" SG_ 1111 PFSU_LH_ReclMtrPos "19.07.05";
BA_ "GenMsgSendType" BO_ 1089 0;
BA_ "Description" SG_ 1089 PSM_RrRtSldStrtSta "This signal indicates the start/finish of rear right slide motor.";
BA_ "GenSigSendType" SG_ 1089 PSM_RrRtSldStrtSta 4;
BA_ "UserSigValidity" SG_ 1089 PSM_RrRtSldStrtSta 0;
BA_REL_ "GenSigTimeoutTime" BU_SG_REL_ ARS SG_ 1089 PSM_RrRtSldStrtSta 1500;
BA_REL_ "GenSigTimeoutTime" BU_SG_REL_ GW_APSU SG_ 1089 PSM_RrRtSldStrtSta 1500;
BA_REL_ "GenSigTimeoutTime" BU_SG_REL_ GW_DPSU SG_ 1089 PSM_RrRtSldStrtSta 1500;
BA_REL_ "GenSigTimeoutTime" BU_SG_REL_ GW_RLPSU SG_ 1089 PSM_RrRtSldStrtSta 1500;
BA_ "NetworkRequest" SG_ 1089 PSM_RrRtSldStrtSta 0;
BA_ "NetworkRequestHoldingTime" SG_ 1089 PSM_RrRtSldStrtSta 5000;
BA_ "Version" SG_ 1089 PSM_RrRtSldStrtSta "17.11.00";
BA_ "GenSigSendType" SG_ 1089 RRPSM_APSMBzrOnReq 4;
BA_ "UserSigValidity" SG_ 1089 RRPSM_APSMBzrOnReq 0;
BA_REL_ "GenSigTimeoutTime" BU_SG_REL_ ATS SG_ 1089 RRPSM_APSMBzrOnReq 1500;
BA_REL_ "GenSigTimeoutTime" BU_SG_REL_ GW_APSU SG_ 1089 RRPSM_APSMBzrOnReq 1500;
BA_REL_ "GenSigTimeoutTime" BU_SG_REL_ GW_DPSU SG_ 1089 RRPSM_APSMBzrOnReq 1500;
BA_REL_ "GenSigTimeoutTime" BU_SG_REL_ GW_RLPSU SG_ 1089 RRPSM_APSMBzrOnReq 1500;
BA_ "NetworkRequest" SG_ 1089 RRPSM_APSMBzrOnReq 0;
BA_ "NetworkRequestHoldingTime" SG_ 1089 RRPSM_APSMBzrOnReq 5000;
BA_ "Version" SG_ 1089 RRPSM_APSMBzrOnReq "17.11.00";
BA_ "GenSigSendType" SG_ 1089 RRPSM_SeatTyp 4;
BA_ "UserSigValidity" SG_ 1089 RRPSM_SeatTyp 0;
BA_REL_ "GenSigTimeoutTime" BU_SG_REL_ GW_DPSU SG_ 1089 RRPSM_SeatTyp 1500;
BA_ "NetworkRequest" SG_ 1089 RRPSM_SeatTyp 0;
BA_ "NetworkRequestHoldingTime" SG_ 1089 RRPSM_SeatTyp 5000;
BA_ "Version" SG_ 1089 RRPSM_SeatTyp "21.03.11";
BA_ "GenSigSendType" SG_ 1089 RRPSM_RRStEsyAcsUSMSta 4;
BA_ "UserSigValidity" SG_ 1089 RRPSM_RRStEsyAcsUSMSta 0;
BA_REL_ "GenSigTimeoutTime" BU_SG_REL_ ATS SG_ 1089 RRPSM_RRStEsyAcsUSMSta 1500;
BA_REL_ "GenSigTimeoutTime" BU_SG_REL_ CGW_CCU SG_ 1089 RRPSM_RRStEsyAcsUSMSta 1500;
BA_REL_ "GenSigTimeoutTime" BU_SG_REL_ GW_DLBCU SG_ 1089 RRPSM_RRStEsyAcsUSMSta 1500;
BA_ "NetworkRequest" SG_ 1089 RRPSM_RRStEsyAcsUSMSta 0;
BA_ "NetworkRequestHoldingTime" SG_ 1089 RRPSM_RRStEsyAcsUSMSta 5000;
BA_ "Version" SG_ 1089 RRPSM_RRStEsyAcsUSMSta "19.10.07";
BA_ "Description" SG_ 1089 RRPSM_RRSlidePosition "Rear Right Seat Slide Position (UNIT: mm, 1 Value ´ç 2mm)";
BA_ "GenSigSendType" SG_ 1089 RRPSM_RRSlidePosition 4;
BA_ "UserSigValidity" SG_ 1089 RRPSM_RRSlidePosition 0;
BA_REL_ "GenSigTimeoutTime" BU_SG_REL_ GW_APSU SG_ 1089 RRPSM_RRSlidePosition 1500;
BA_REL_ "GenSigTimeoutTime" BU_SG_REL_ GW_DPSU SG_ 1089 RRPSM_RRSlidePosition 1500;
BA_ "NetworkRequest" SG_ 1089 RRPSM_RRSlidePosition 0;
BA_ "NetworkRequestHoldingTime" SG_ 1089 RRPSM_RRSlidePosition 5000;
BA_ "Version" SG_ 1089 RRPSM_RRSlidePosition "22.06.05";
BA_ "Description" SG_ 1089 RRPSM_SeatPosPlyBck_Sta "The signal indicates the state of RearRight's seat position playing back.";
BA_ "GenSigSendType" SG_ 1089 RRPSM_SeatPosPlyBck_Sta 4;
BA_ "UserSigValidity" SG_ 1089 RRPSM_SeatPosPlyBck_Sta 0;
BA_REL_ "GenSigTimeoutTime" BU_SG_REL_ GW_RLPSU SG_ 1089 RRPSM_SeatPosPlyBck_Sta 1500;
BA_ "Version" SG_ 1089 RRPSM_SeatPosPlyBck_Sta "20.03.00";
BA_ "Description" SG_ 1089 RRPSM_SeatPos_Sta "The signal indicates the state of  Rear Right seat Meomry State";
BA_ "GenSigSendType" SG_ 1089 RRPSM_SeatPos_Sta 4;
BA_ "UserSigValidity" SG_ 1089 RRPSM_SeatPos_Sta 0;
BA_REL_ "GenSigTimeoutTime" BU_SG_REL_ GW_RLPSU SG_ 1089 RRPSM_SeatPos_Sta 1500;
BA_ "Version" SG_ 1089 RRPSM_SeatPos_Sta "20.03.00";
BA_ "Description" SG_ 1089 RRPSM_SeatPosSldLmt_Sta "RRPSM Slide end Position and limit Initialize State information";
BA_ "GenSigSendType" SG_ 1089 RRPSM_SeatPosSldLmt_Sta 4;
BA_ "UserSigValidity" SG_ 1089 RRPSM_SeatPosSldLmt_Sta 0;
BA_REL_ "GenSigTimeoutTime" BU_SG_REL_ CGW_CCU SG_ 1089 RRPSM_SeatPosSldLmt_Sta 1500;
BA_ "NetworkRequest" SG_ 1089 RRPSM_SeatPosSldLmt_Sta 0;
BA_ "NetworkRequestHoldingTime" SG_ 1089 RRPSM_SeatPosSldLmt_Sta 5000;
BA_ "Version" SG_ 1089 RRPSM_SeatPosSldLmt_Sta "20.03.00";
BA_ "Description" SG_ 1089 RRPSM_RearModeState "Rear Seat State For One Touch Mode";
BA_ "GenSigSendType" SG_ 1089 RRPSM_RearModeState 4;
BA_ "UserSigValidity" SG_ 1089 RRPSM_RearModeState 0;
BA_REL_ "GenSigTimeoutTime" BU_SG_REL_ ATS SG_ 1089 RRPSM_RearModeState 1500;
BA_REL_ "GenSigTimeoutTime" BU_SG_REL_ CGW_CCU SG_ 1089 RRPSM_RearModeState 1500;
BA_REL_ "GenSigTimeoutTime" BU_SG_REL_ GW_APSU SG_ 1089 RRPSM_RearModeState 1500;
BA_REL_ "GenSigTimeoutTime" BU_SG_REL_ GW_DPSU SG_ 1089 RRPSM_RearModeState 1500;
BA_REL_ "GenSigTimeoutTime" BU_SG_REL_ GW_RLPSU SG_ 1089 RRPSM_RearModeState 1500;
BA_REL_ "GenSigTimeoutTime" BU_SG_REL_ OHCL SG_ 1089 RRPSM_RearModeState 1500;
BA_ "NetworkRequest" SG_ 1089 RRPSM_RearModeState 0;
BA_ "NetworkRequestHoldingTime" SG_ 1089 RRPSM_RearModeState 5000;
BA_ "Version" SG_ 1089 RRPSM_RearModeState "23.12.00";
BA_ "Description" SG_ 1089 RRPSM_RRLegRestPosition "Rear SEAT Leg Rest UP/DOWN POSITION (UNIT: ¨¬)";
BA_ "GenSigSendType" SG_ 1089 RRPSM_RRLegRestPosition 4;
BA_ "UserSigValidity" SG_ 1089 RRPSM_RRLegRestPosition 0;
BA_REL_ "GenSigTimeoutTime" BU_SG_REL_ GW_APSU SG_ 1089 RRPSM_RRLegRestPosition 1500;
BA_REL_ "GenSigTimeoutTime" BU_SG_REL_ GW_DPSU SG_ 1089 RRPSM_RRLegRestPosition 1500;
BA_ "NetworkRequest" SG_ 1089 RRPSM_RRLegRestPosition 0;
BA_ "NetworkRequestHoldingTime" SG_ 1089 RRPSM_RRLegRestPosition 5000;
BA_ "Version" SG_ 1089 RRPSM_RRLegRestPosition "20.09.00";
BA_ "GenMsgSendType" BO_ 1107 0;
BA_ "Description" SG_ 1107 RR_SHVU_SeatOptSta "ÈÄ¼® RH ½ÃÆ®¿¡ Àû¿ëµÈ È÷ÅÍ/ÅëÇ³ ¿É¼Ç »ç¾ç";
BA_ "GenSigSendType" SG_ 1107 RR_SHVU_SeatOptSta 4;
BA_ "UserSigValidity" SG_ 1107 RR_SHVU_SeatOptSta 7;
BA_REL_ "GenSigTimeoutTime" BU_SG_REL_ ASAU SG_ 1107 RR_SHVU_SeatOptSta 1500;
BA_REL_ "GenSigTimeoutTime" BU_SG_REL_ ATS SG_ 1107 RR_SHVU_SeatOptSta 1500;
BA_REL_ "GenSigTimeoutTime" BU_SG_REL_ CGW_CCU SG_ 1107 RR_SHVU_SeatOptSta 1500;
BA_ "NetworkRequest" SG_ 1107 RR_SHVU_SeatOptSta 0;
BA_ "NetworkRequestHoldingTime" SG_ 1107 RR_SHVU_SeatOptSta 5000;
BA_ "Version" SG_ 1107 RR_SHVU_SeatOptSta "22.05.04";
BA_ "Description" SG_ 1107 RR_SHVU_SeatHtOperSta "ÈÄ¼® RH ½ÃÆ® ÇöÀç ÀÛµ¿ ÁßÀÎ È÷ÅÍ/ÅëÇ³ ´Ü¼ö »óÅÂ";
BA_ "GenSigSendType" SG_ 1107 RR_SHVU_SeatHtOperSta 4;
BA_ "UserSigValidity" SG_ 1107 RR_SHVU_SeatHtOperSta 7;
BA_REL_ "GenSigTimeoutTime" BU_SG_REL_ ASAU SG_ 1107 RR_SHVU_SeatHtOperSta 1500;
BA_REL_ "GenSigTimeoutTime" BU_SG_REL_ ATS SG_ 1107 RR_SHVU_SeatHtOperSta 1500;
BA_REL_ "GenSigTimeoutTime" BU_SG_REL_ CGW_CCU SG_ 1107 RR_SHVU_SeatHtOperSta 1500;
BA_REL_ "GenSigTimeoutTime" BU_SG_REL_ FCS SG_ 1107 RR_SHVU_SeatHtOperSta 1500;
BA_ "NetworkRequest" SG_ 1107 RR_SHVU_SeatHtOperSta 0;
BA_ "NetworkRequestHoldingTime" SG_ 1107 RR_SHVU_SeatHtOperSta 5000;
BA_ "Version" SG_ 1107 RR_SHVU_SeatHtOperSta "22.05.04";
BA_ "GenMsgSendType" BO_ 1094 0;
BA_ "Description" SG_ 1094 SLB_PlyBckSta "This signal indicates the playback status (IMS)";
BA_ "GenSigSendType" SG_ 1094 SLB_PlyBckSta 4;
BA_ "UserSigValidity" SG_ 1094 SLB_PlyBckSta 0;
BA_ "NetworkRequest" SG_ 1094 SLB_PlyBckSta 0;
BA_ "NetworkRequestHoldingTime" SG_ 1094 SLB_PlyBckSta 5000;
BA_ "Version" SG_ 1094 SLB_PlyBckSta "17.11.00";
BA_ "GenMsgSendType" BO_ 1092 0;
BA_ "Description" SG_ 1092 SMK_Crc2Val "The data area for CRC calculation is based on the data length (DLC) of the message DB.

The CRC shall be calculated over the entire data block (excluding the CRC bytes) including the user data, alive counter and Data ID 

 

- CRC Polynomial (0x1D) , Initial Value : 0x00, XOR value : 0xFF, Data ID Mode : Both, Data ID : Message ID + 0xF800 

- The initial value is for CRC calculation and the message should be sent with the calculated result value. 

The mathematical expression to 8 bit CRC polynomial is given here. G(x) = x8 + x4 + x3 + x2 + 1";
BA_ "GenSigSendType" SG_ 1092 SMK_Crc2Val 4;
BA_ "UserSigValidity" SG_ 1092 SMK_Crc2Val 0;
BA_ "Version" SG_ 1092 SMK_Crc2Val "21.09.03";
BA_ "Description" SG_ 1092 SMK_AlvCnt2Val "For the first transmission request for a data element the counter shall be initialized with 0 and shall be incremented by 1

for every subsequent send request. When the counter reaches the maximum value(0xE), then it shall restart with 0 for the next send request";
BA_ "GenSigSendType" SG_ 1092 SMK_AlvCnt2Val 4;
BA_ "UserSigValidity" SG_ 1092 SMK_AlvCnt2Val 0;
BA_ "Version" SG_ 1092 SMK_AlvCnt2Val "21.09.03";
BA_ "Description" SG_ 1092 SSB_StrtStpBtnSw1Sta "StartStop button switch #1 status";
BA_ "GenSigSendType" SG_ 1092 SSB_StrtStpBtnSw1Sta 4;
BA_ "UserSigValidity" SG_ 1092 SSB_StrtStpBtnSw1Sta 0;
BA_ "Version" SG_ 1092 SSB_StrtStpBtnSw1Sta "17.12.00";
BA_ "Description" SG_ 1092 SSB_StrtStpBtnSw2Sta "StartStop button switch #2 status";
BA_ "GenSigSendType" SG_ 1092 SSB_StrtStpBtnSw2Sta 4;
BA_ "UserSigValidity" SG_ 1092 SSB_StrtStpBtnSw2Sta 0;
BA_ "Version" SG_ 1092 SSB_StrtStpBtnSw2Sta "17.12.00";
BA_ "Description" SG_ 1092 SMK_TrmnlCtrlSta "Mirror value of TerminalControlState";
BA_ "GenSigSendType" SG_ 1092 SMK_TrmnlCtrlSta 4;
BA_ "UserSigValidity" SG_ 1092 SMK_TrmnlCtrlSta 0;
BA_ "Version" SG_ 1092 SMK_TrmnlCtrlSta "17.12.00";
BA_ "GenSigSendType" SG_ 1092 SMK_AuthSta 4;
BA_ "UserSigValidity" SG_ 1092 SMK_AuthSta 0;
BA_REL_ "GenSigTimeoutTime" BU_SG_REL_ GW_APSU SG_ 1092 SMK_AuthSta 1500;
BA_REL_ "GenSigTimeoutTime" BU_SG_REL_ GW_DPSU SG_ 1092 SMK_AuthSta 1500;
BA_ "Version" SG_ 1092 SMK_AuthSta "17.12.00";
BA_ "Description" SG_ 1092 SMK_Ign1InSta "Ignition1 Input Status at SMK";
BA_ "GenSigSendType" SG_ 1092 SMK_Ign1InSta 4;
BA_ "UserSigValidity" SG_ 1092 SMK_Ign1InSta 0;
BA_ "Version" SG_ 1092 SMK_Ign1InSta "17.12.00";
BA_ "Description" SG_ 1092 SMK_Ign1RlySta "Development for SMK";
BA_ "GenSigSendType" SG_ 1092 SMK_Ign1RlySta 4;
BA_ "UserSigValidity" SG_ 1092 SMK_Ign1RlySta 0;
BA_ "Version" SG_ 1092 SMK_Ign1RlySta "17.12.00";
BA_ "Description" SG_ 1092 SMK_Ign2InSta "Ignition2 Input Status at SMK";
BA_ "GenSigSendType" SG_ 1092 SMK_Ign2InSta 4;
BA_ "UserSigValidity" SG_ 1092 SMK_Ign2InSta 0;
BA_ "Version" SG_ 1092 SMK_Ign2InSta "17.12.00";
BA_ "Description" SG_ 1092 SMK_Ign2RlySta "Development for SMK";
BA_ "GenSigSendType" SG_ 1092 SMK_Ign2RlySta 4;
BA_ "UserSigValidity" SG_ 1092 SMK_Ign2RlySta 0;
BA_ "Version" SG_ 1092 SMK_Ign2RlySta "17.12.00";
BA_ "Description" SG_ 1092 SMK_StrtFdbckSta "Mirror value of L_StartFeedback";
BA_ "GenSigSendType" SG_ 1092 SMK_StrtFdbckSta 4;
BA_ "UserSigValidity" SG_ 1092 SMK_StrtFdbckSta 0;
BA_ "Version" SG_ 1092 SMK_StrtFdbckSta "17.12.00";
BA_ "Description" SG_ 1092 SMK_StrtrRlyOutSta "-(Old)C_StarterRelayStatus";
BA_ "GenSigSendType" SG_ 1092 SMK_StrtrRlyOutSta 4;
BA_ "UserSigValidity" SG_ 1092 SMK_StrtrRlyOutSta 0;
BA_ "Version" SG_ 1092 SMK_StrtrRlyOutSta "17.12.00";
BA_ "Description" SG_ 1092 SMK_AccInSta "ACC Input Status at SMK";
BA_ "GenSigSendType" SG_ 1092 SMK_AccInSta 4;
BA_ "UserSigValidity" SG_ 1092 SMK_AccInSta 0;
BA_ "Version" SG_ 1092 SMK_AccInSta "17.12.00";
BA_ "Description" SG_ 1092 SMK_AccRlySta "Development for SMK";
BA_ "GenSigSendType" SG_ 1092 SMK_AccRlySta 4;
BA_ "UserSigValidity" SG_ 1092 SMK_AccRlySta 0;
BA_ "Version" SG_ 1092 SMK_AccRlySta "17.12.00";
BA_ "Description" SG_ 1092 SMK_CLUAccIndOnReq "Request to Cluster ACC Indicator On

(This is only used for CLU)";
BA_ "GenSigSendType" SG_ 1092 SMK_CLUAccIndOnReq 4;
BA_ "UserSigValidity" SG_ 1092 SMK_CLUAccIndOnReq 0;
BA_ "Version" SG_ 1092 SMK_CLUAccIndOnReq "17.12.00";
BA_ "GenSigSendType" SG_ 1092 SMK_VDModeActSta 4;
BA_ "UserSigValidity" SG_ 1092 SMK_VDModeActSta 0;
BA_ "Version" SG_ 1092 SMK_VDModeActSta "20.07.05";
BA_ "Description" SG_ 1092 SMK_SCULckUnlckSta "SCU Lock/Unlock State";
BA_ "GenSigSendType" SG_ 1092 SMK_SCULckUnlckSta 4;
BA_ "UserSigValidity" SG_ 1092 SMK_SCULckUnlckSta 0;
BA_ "Version" SG_ 1092 SMK_SCULckUnlckSta "22.01.06";
BA_ "GenSigSendType" SG_ 1092 SMK_TlEngRunSta 4;
BA_ "UserSigValidity" SG_ 1092 SMK_TlEngRunSta 0;
BA_REL_ "GenSigTimeoutTime" BU_SG_REL_ ASAU SG_ 1092 SMK_TlEngRunSta 1500;
BA_REL_ "GenSigTimeoutTime" BU_SG_REL_ ATS SG_ 1092 SMK_TlEngRunSta 1500;
BA_REL_ "GenSigTimeoutTime" BU_SG_REL_ DSAU SG_ 1092 SMK_TlEngRunSta 1500;
BA_REL_ "GenSigTimeoutTime" BU_SG_REL_ GW_APSU SG_ 1092 SMK_TlEngRunSta 1500;
BA_REL_ "GenSigTimeoutTime" BU_SG_REL_ GW_DPSU SG_ 1092 SMK_TlEngRunSta 1500;
BA_REL_ "GenSigTimeoutTime" BU_SG_REL_ RLHV SG_ 1092 SMK_TlEngRunSta 1500;
BA_REL_ "GenSigTimeoutTime" BU_SG_REL_ RRHV SG_ 1092 SMK_TlEngRunSta 1500;
BA_REL_ "GenSigTimeoutTime" BU_SG_REL_ SHVU_FR SG_ 1092 SMK_TlEngRunSta 1500;
BA_REL_ "GenSigTimeoutTime" BU_SG_REL_ SHVU_RR SG_ 1092 SMK_TlEngRunSta 1500;
BA_ "Version" SG_ 1092 SMK_TlEngRunSta "17.12.00";
BA_ "GenSigSendType" SG_ 1092 SMK_TlCrnkModSta 4;
BA_ "UserSigValidity" SG_ 1092 SMK_TlCrnkModSta 0;
BA_REL_ "GenSigTimeoutTime" BU_SG_REL_ ASAU SG_ 1092 SMK_TlCrnkModSta 1500;
BA_REL_ "GenSigTimeoutTime" BU_SG_REL_ ATS SG_ 1092 SMK_TlCrnkModSta 1500;
BA_REL_ "GenSigTimeoutTime" BU_SG_REL_ DSAU SG_ 1092 SMK_TlCrnkModSta 1500;
BA_REL_ "GenSigTimeoutTime" BU_SG_REL_ GW_APSU SG_ 1092 SMK_TlCrnkModSta 1500;
BA_REL_ "GenSigTimeoutTime" BU_SG_REL_ GW_DPSU SG_ 1092 SMK_TlCrnkModSta 1500;
BA_REL_ "GenSigTimeoutTime" BU_SG_REL_ SCM SG_ 1092 SMK_TlCrnkModSta 1500;
BA_ "Version" SG_ 1092 SMK_TlCrnkModSta "17.12.00";
BA_ "GenSigSendType" SG_ 1092 SMK_RmtKeyEngRunSta 4;
BA_ "UserSigValidity" SG_ 1092 SMK_RmtKeyEngRunSta 0;
BA_ "Version" SG_ 1092 SMK_RmtKeyEngRunSta "17.11.00";
BA_ "GenSigSendType" SG_ 1092 SMK_RmtKeyCrnkModSta 4;
BA_ "UserSigValidity" SG_ 1092 SMK_RmtKeyCrnkModSta 0;
BA_ "Version" SG_ 1092 SMK_RmtKeyCrnkModSta "17.11.00";
BA_ "GenMsgSendType" BO_ 1093 0;
BA_ "Description" SG_ 1093 SMK_Crc6Val "The data area for CRC calculation is based on the data length (DLC) of the message DB.

The CRC shall be calculated over the entire data block (excluding the CRC bytes) including the user data, alive counter and Data ID 

 

- CRC Polynomial (0x1D) , Initial Value : 0x00, XOR value : 0xFF, Data ID Mode : Both, Data ID : Message ID + 0xF800 

- The initial value is for CRC calculation and the message should be sent with the calculated result value. 

The mathematical expression to 8 bit CRC polynomial is given here. G(x) = x8 + x4 + x3 + x2 + 1";
BA_ "GenSigSendType" SG_ 1093 SMK_Crc6Val 4;
BA_ "UserSigValidity" SG_ 1093 SMK_Crc6Val 0;
BA_ "Version" SG_ 1093 SMK_Crc6Val "21.09.03";
BA_ "Description" SG_ 1093 SMK_AlvCnt6Val "For the first transmission request for a data element the counter shall be initialized with 0 and shall be incremented by 1

for every subsequent send request. When the counter reaches the maximum value(0xE), then it shall restart with 0 for the next send request";
BA_ "GenSigSendType" SG_ 1093 SMK_AlvCnt6Val 4;
BA_ "UserSigValidity" SG_ 1093 SMK_AlvCnt6Val 0;
BA_ "Version" SG_ 1093 SMK_AlvCnt6Val "21.09.03";
BA_ "Description" SG_ 1093 Lamp_HzrdBlnkngSta "Hazard Signal for Hands Free Trunk/Tailgate";
BA_ "GenSigSendType" SG_ 1093 Lamp_HzrdBlnkngSta 4;
BA_ "UserSigValidity" SG_ 1093 Lamp_HzrdBlnkngSta 0;
BA_ "Version" SG_ 1093 Lamp_HzrdBlnkngSta "17.12.00";
BA_ "Description" SG_ 1093 RSPA_LearntSta "IBU RSPA learnt state signal.

This signal is used only for ADAS_PRK.";
BA_ "GenSigSendType" SG_ 1093 RSPA_LearntSta 4;
BA_ "UserSigValidity" SG_ 1093 RSPA_LearntSta 0;
BA_ "Version" SG_ 1093 RSPA_LearntSta "19.07.01";
BA_ "Description" SG_ 1093 Lamp_SmrtWlcmLtOnReq "Smart Key welcome light on request.";
BA_ "GenSigSendType" SG_ 1093 Lamp_SmrtWlcmLtOnReq 4;
BA_ "UserSigValidity" SG_ 1093 Lamp_SmrtWlcmLtOnReq 0;
BA_ "NetworkRequest" SG_ 1093 Lamp_SmrtWlcmLtOnReq 0;
BA_ "NetworkRequestHoldingTime" SG_ 1093 Lamp_SmrtWlcmLtOnReq 5000;
BA_ "Version" SG_ 1093 Lamp_SmrtWlcmLtOnReq "17.12.00";
BA_ "Description" SG_ 1093 Fob_BattStaInfo "Received Fob Battery Status for Telematics Vehicle Information Service";
BA_ "GenSigSendType" SG_ 1093 Fob_BattStaInfo 4;
BA_ "UserSigValidity" SG_ 1093 Fob_BattStaInfo 0;
BA_ "Version" SG_ 1093 Fob_BattStaInfo "17.12.00";
BA_ "Description" SG_ 1093 Fob_FoundDrvWlcmArea "This Signal Indicates direction of user approach to vehicle.

If User Approach to vehicle Driver direction, This signal set On.";
BA_ "GenSigSendType" SG_ 1093 Fob_FoundDrvWlcmArea 4;
BA_ "UserSigValidity" SG_ 1093 Fob_FoundDrvWlcmArea 0;
BA_ "Version" SG_ 1093 Fob_FoundDrvWlcmArea "17.12.00";
BA_ "Description" SG_ 1093 Fob_FoundAsstWlcmArea "This Signal Indicates direction of user approach to vehicle.

If User Approach to vehicle Assistant direction, This signal set On.";
BA_ "GenSigSendType" SG_ 1093 Fob_FoundAsstWlcmArea 4;
BA_ "UserSigValidity" SG_ 1093 Fob_FoundAsstWlcmArea 0;
BA_ "Version" SG_ 1093 Fob_FoundAsstWlcmArea "17.12.00";
BA_ "Description" SG_ 1093 Fob_FoundExtrnlArea "Exterior FOB Position recognize";
BA_ "GenSigSendType" SG_ 1093 Fob_FoundExtrnlArea 4;
BA_ "UserSigValidity" SG_ 1093 Fob_FoundExtrnlArea 0;
BA_ "Version" SG_ 1093 Fob_FoundExtrnlArea "17.12.00";
BA_ "Description" SG_ 1093 Fob_FoundIntArea "Interior FOB Position recognize";
BA_ "GenSigSendType" SG_ 1093 Fob_FoundIntArea 4;
BA_ "UserSigValidity" SG_ 1093 Fob_FoundIntArea 0;
BA_ "Version" SG_ 1093 Fob_FoundIntArea "17.12.00";
BA_ "Description" SG_ 1093 Fob_LearntSta "Fob key registration status information";
BA_ "GenSigSendType" SG_ 1093 Fob_LearntSta 4;
BA_ "GenSigStartValue" SG_ 1093 Fob_LearntSta 1;
BA_ "UserSigValidity" SG_ 1093 Fob_LearntSta 0;
BA_ "NetworkRequest" SG_ 1093 Fob_LearntSta 0;
BA_ "NetworkRequestHoldingTime" SG_ 1093 Fob_LearntSta 5000;
BA_ "Version" SG_ 1093 Fob_LearntSta "17.12.00";
BA_ "Description" SG_ 1093 RSPA_RFSigErrSta "Error status of RKE_BtnReq signal.



If RF frame data from FOB defferent with CAN signal data(RKE_BtnReq), 

RSPA_RFSigErrSta signal send 0x1 Signal Invalid.";
BA_ "GenSigSendType" SG_ 1093 RSPA_RFSigErrSta 4;
BA_ "UserSigValidity" SG_ 1093 RSPA_RFSigErrSta 0;
BA_ "NetworkRequest" SG_ 1093 RSPA_RFSigErrSta 0;
BA_ "NetworkRequestHoldingTime" SG_ 1093 RSPA_RFSigErrSta 5000;
BA_ "Version" SG_ 1093 RSPA_RFSigErrSta "18.05.02";
BA_ "Description" SG_ 1093 RSPA_CanErrSta "Error status of RSPA control signals.(From ADAS_PRK)";
BA_ "GenSigSendType" SG_ 1093 RSPA_CanErrSta 4;
BA_ "UserSigValidity" SG_ 1093 RSPA_CanErrSta 0;
BA_ "Version" SG_ 1093 RSPA_CanErrSta "18.05.02";
BA_ "Description" SG_ 1093 LFAnt_FltSta "This signal represents LF ANT's Error condition. 

If one of LF ANT has Fault(ex, timeout), signal has fault value.";
BA_ "GenSigSendType" SG_ 1093 LFAnt_FltSta 4;
BA_ "UserSigValidity" SG_ 1093 LFAnt_FltSta 0;
BA_ "Version" SG_ 1093 LFAnt_FltSta "17.12.00";
BA_ "Description" SG_ 1093 LFAnt_SrchSta "SMK LF Searching Status



This signal indicates that SMK operates LF searching for finding FOB.

WPC uses this signal for suspending wirless charging.";
BA_ "GenSigSendType" SG_ 1093 LFAnt_SrchSta 4;
BA_ "UserSigValidity" SG_ 1093 LFAnt_SrchSta 0;
BA_REL_ "GenSigTimeoutTime" BU_SG_REL_ RWPC SG_ 1093 LFAnt_SrchSta 1500;
BA_REL_ "GenSigTimeoutTime" BU_SG_REL_ WPC SG_ 1093 LFAnt_SrchSta 1500;
BA_REL_ "GenSigTimeoutTime" BU_SG_REL_ WPC2 SG_ 1093 LFAnt_SrchSta 1500;
BA_ "Version" SG_ 1093 LFAnt_SrchSta "17.12.00";
BA_ "Description" SG_ 1093 Auth_ISKLearnSta "This signal is State of IAU Learning";
BA_ "GenSigSendType" SG_ 1093 Auth_ISKLearnSta 4;
BA_ "UserSigValidity" SG_ 1093 Auth_ISKLearnSta 0;
BA_ "Version" SG_ 1093 Auth_ISKLearnSta "19.02.07";
BA_ "Description" SG_ 1093 RSPA_ModSta_SMK "State of RSPA system operate";
BA_ "GenSigSendType" SG_ 1093 RSPA_ModSta_SMK 4;
BA_ "UserSigValidity" SG_ 1093 RSPA_ModSta_SMK 0;
BA_REL_ "GenSigTimeoutTime" BU_SG_REL_ GW_DPSU SG_ 1093 RSPA_ModSta_SMK 1500;
BA_ "Version" SG_ 1093 RSPA_ModSta_SMK "19.03.08";
BA_ "Description" SG_ 1093 RSPA_FobBattSta "FOB Battery's Low Battery(discharge) state.

Low Battery condition is same with 'C_KeyBATDischargeWarn' Signal";
BA_ "GenSigSendType" SG_ 1093 RSPA_FobBattSta 4;
BA_ "UserSigValidity" SG_ 1093 RSPA_FobBattSta 0;
BA_ "Version" SG_ 1093 RSPA_FobBattSta "17.12.00";
BA_ "Description" SG_ 1093 Fob_BtnReleasedSta "this signal indicate fob butten released state during RSPA mode. 

##2G##IBU##SMK18##C_FobButtenReleased";
BA_ "GenSigSendType" SG_ 1093 Fob_BtnReleasedSta 4;
BA_ "UserSigValidity" SG_ 1093 Fob_BtnReleasedSta 0;
BA_ "Version" SG_ 1093 Fob_BtnReleasedSta "18.10.09";
BA_ "GenSigSendType" SG_ 1093 USM_SmrtTrnkTlgtModSta 4;
BA_ "UserSigValidity" SG_ 1093 USM_SmrtTrnkTlgtModSta 0;
BA_ "Version" SG_ 1093 USM_SmrtTrnkTlgtModSta "18.05.01";
BA_ "Description" SG_ 1093 USM_WALModSta "Current USM Setting value of Walk Away Lock(WAL) mode";
BA_ "GenSigSendType" SG_ 1093 USM_WALModSta 4;
BA_ "UserSigValidity" SG_ 1093 USM_WALModSta 0;
BA_ "Version" SG_ 1093 USM_WALModSta "17.12.00";
BA_ "Description" SG_ 1093 Fob_FoundWlcmArea "This signal indicates that there is Fob around the welcome area. 

 -to inform the door handle (Lock/Unlock touch sensor)";
BA_ "GenSigSendType" SG_ 1093 Fob_FoundWlcmArea 4;
BA_ "UserSigValidity" SG_ 1093 Fob_FoundWlcmArea 0;
BA_ "Version" SG_ 1093 Fob_FoundWlcmArea "19.03.09";
BA_ "GenMsgSendType" BO_ 1096 0;
BA_ "Description" SG_ 1096 SWRC_Crc1Val "The data area for CRC calculation is based on the data length (DLC) of the message DB.

The CRC shall be calculated over the entire data block (excluding the CRC bytes) including the user data, alive counter and Data ID 

 

- CRC Polynomial (0x1D) , Initial Value : 0x00, XOR value : 0xFF, Data ID Mode : Both, Data ID : Message ID + 0xF800 

- The initial value is for CRC calculation and the message should be sent with the calculated result value. 

The mathematical expression to 8 bit CRC polynomial is given here. G(x) = x8 + x4 + x3 + x2 + 1";
BA_ "GenSigSendType" SG_ 1096 SWRC_Crc1Val 4;
BA_ "UserSigValidity" SG_ 1096 SWRC_Crc1Val 0;
BA_ "Version" SG_ 1096 SWRC_Crc1Val "21.09.03";
BA_ "Description" SG_ 1096 SWRC_AlvCnt1Val "For the first transmission request for a data element the counter shall be initialized with 0 and shall be incremented by 1

for every subsequent send request. When the counter reaches the maximum value(0xE), then it shall restart with 0 for the next send request";
BA_ "GenSigSendType" SG_ 1096 SWRC_AlvCnt1Val 4;
BA_ "UserSigValidity" SG_ 1096 SWRC_AlvCnt1Val 0;
BA_REL_ "GenSigTimeoutTime" BU_SG_REL_ CGW_CCU SG_ 1096 SWRC_AlvCnt1Val 1500;
BA_ "Version" SG_ 1096 SWRC_AlvCnt1Val "21.09.03";
BA_ "Description" SG_ 1096 Audio_VcRecSwSta "Audio Voice recognition switch



MM-CAN Gateway needed";
BA_ "GenSigSendType" SG_ 1096 Audio_VcRecSwSta 4;
BA_ "UserSigValidity" SG_ 1096 Audio_VcRecSwSta 0;
BA_REL_ "GenSigTimeoutTime" BU_SG_REL_ CGW_CCU SG_ 1096 Audio_VcRecSwSta 1500;
BA_ "NetworkRequest" SG_ 1096 Audio_VcRecSwSta 0;
BA_ "NetworkRequestHoldingTime" SG_ 1096 Audio_VcRecSwSta 5000;
BA_ "Version" SG_ 1096 Audio_VcRecSwSta "21.07.05";
BA_ "Description" SG_ 1096 Audio_BluetoothPhnClSwSta "Bluetooth phone call switch on/off



MM-CAN Gateway needed";
BA_ "GenSigSendType" SG_ 1096 Audio_BluetoothPhnClSwSta 4;
BA_ "UserSigValidity" SG_ 1096 Audio_BluetoothPhnClSwSta 0;
BA_REL_ "GenSigTimeoutTime" BU_SG_REL_ CGW_CCU SG_ 1096 Audio_BluetoothPhnClSwSta 1500;
BA_ "NetworkRequest" SG_ 1096 Audio_BluetoothPhnClSwSta 0;
BA_ "NetworkRequestHoldingTime" SG_ 1096 Audio_BluetoothPhnClSwSta 5000;
BA_ "Version" SG_ 1096 Audio_BluetoothPhnClSwSta "21.07.05";
BA_ "Description" SG_ 1096 Audio_BluetoothPhnHangUpSwSta "Bluetooth phone hang up switch on/off



MM-CAN Gateway needed";
BA_ "GenSigSendType" SG_ 1096 Audio_BluetoothPhnHangUpSwSta 4;
BA_ "UserSigValidity" SG_ 1096 Audio_BluetoothPhnHangUpSwSta 0;
BA_REL_ "GenSigTimeoutTime" BU_SG_REL_ CGW_CCU SG_ 1096 Audio_BluetoothPhnHangUpSwSta 1500;
BA_ "NetworkRequest" SG_ 1096 Audio_BluetoothPhnHangUpSwSta 0;
BA_ "NetworkRequestHoldingTime" SG_ 1096 Audio_BluetoothPhnHangUpSwSta 5000;
BA_ "Version" SG_ 1096 Audio_BluetoothPhnHangUpSwSta "19.11.02";
BA_ "Description" SG_ 1096 Audio_ModSwSta "Audio Mode switch



MM-CAN Gateway needed";
BA_ "GenSigSendType" SG_ 1096 Audio_ModSwSta 4;
BA_ "UserSigValidity" SG_ 1096 Audio_ModSwSta 0;
BA_REL_ "GenSigTimeoutTime" BU_SG_REL_ CGW_CCU SG_ 1096 Audio_ModSwSta 1500;
BA_ "NetworkRequest" SG_ 1096 Audio_ModSwSta 0;
BA_ "NetworkRequestHoldingTime" SG_ 1096 Audio_ModSwSta 5000;
BA_ "Version" SG_ 1096 Audio_ModSwSta "21.07.05";
BA_ "Description" SG_ 1096 Audio_MutSwSta "Audio Mute switch



MM-CAN Gateway needed";
BA_ "GenSigSendType" SG_ 1096 Audio_MutSwSta 4;
BA_ "UserSigValidity" SG_ 1096 Audio_MutSwSta 0;
BA_REL_ "GenSigTimeoutTime" BU_SG_REL_ CGW_CCU SG_ 1096 Audio_MutSwSta 1500;
BA_ "NetworkRequest" SG_ 1096 Audio_MutSwSta 0;
BA_ "NetworkRequestHoldingTime" SG_ 1096 Audio_MutSwSta 5000;
BA_ "Version" SG_ 1096 Audio_MutSwSta "19.11.02";
BA_ "Description" SG_ 1096 Audio_SeekDnSwSta "Audio Seek Down switch



MM-CAN Gateway needed";
BA_ "GenSigSendType" SG_ 1096 Audio_SeekDnSwSta 4;
BA_ "UserSigValidity" SG_ 1096 Audio_SeekDnSwSta 0;
BA_REL_ "GenSigTimeoutTime" BU_SG_REL_ CGW_CCU SG_ 1096 Audio_SeekDnSwSta 1500;
BA_ "NetworkRequest" SG_ 1096 Audio_SeekDnSwSta 0;
BA_ "NetworkRequestHoldingTime" SG_ 1096 Audio_SeekDnSwSta 5000;
BA_ "Version" SG_ 1096 Audio_SeekDnSwSta "19.11.02";
BA_ "Description" SG_ 1096 Audio_SeekUpSwSta "Audio Seek Up switch



MM-CAN Gateway needed";
BA_ "GenSigSendType" SG_ 1096 Audio_SeekUpSwSta 4;
BA_ "UserSigValidity" SG_ 1096 Audio_SeekUpSwSta 0;
BA_REL_ "GenSigTimeoutTime" BU_SG_REL_ CGW_CCU SG_ 1096 Audio_SeekUpSwSta 1500;
BA_ "NetworkRequest" SG_ 1096 Audio_SeekUpSwSta 0;
BA_ "NetworkRequestHoldingTime" SG_ 1096 Audio_SeekUpSwSta 5000;
BA_ "Version" SG_ 1096 Audio_SeekUpSwSta "19.11.02";
BA_ "Description" SG_ 1096 Audio_VolDnSwSta "Audio Volume Down switch



MM-CAN Gateway needed";
BA_ "GenSigSendType" SG_ 1096 Audio_VolDnSwSta 4;
BA_ "UserSigValidity" SG_ 1096 Audio_VolDnSwSta 0;
BA_REL_ "GenSigTimeoutTime" BU_SG_REL_ CGW_CCU SG_ 1096 Audio_VolDnSwSta 1500;
BA_ "NetworkRequest" SG_ 1096 Audio_VolDnSwSta 0;
BA_ "NetworkRequestHoldingTime" SG_ 1096 Audio_VolDnSwSta 5000;
BA_ "Version" SG_ 1096 Audio_VolDnSwSta "19.11.02";
BA_ "Description" SG_ 1096 Audio_VolUpSwSta "Audio Volume Up switch



MM-CAN Gateway needed";
BA_ "GenSigSendType" SG_ 1096 Audio_VolUpSwSta 4;
BA_ "UserSigValidity" SG_ 1096 Audio_VolUpSwSta 0;
BA_REL_ "GenSigTimeoutTime" BU_SG_REL_ CGW_CCU SG_ 1096 Audio_VolUpSwSta 1500;
BA_ "NetworkRequest" SG_ 1096 Audio_VolUpSwSta 0;
BA_ "NetworkRequestHoldingTime" SG_ 1096 Audio_VolUpSwSta 5000;
BA_ "Version" SG_ 1096 Audio_VolUpSwSta "19.11.02";
BA_ "Description" SG_ 1096 Cluster_ModeSwSta "Cluster Mode switch";
BA_ "GenSigSendType" SG_ 1096 Cluster_ModeSwSta 4;
BA_ "UserSigValidity" SG_ 1096 Cluster_ModeSwSta 0;
BA_REL_ "GenSigTimeoutTime" BU_SG_REL_ CGW_CCU SG_ 1096 Cluster_ModeSwSta 1500;
BA_ "NetworkRequest" SG_ 1096 Cluster_ModeSwSta 0;
BA_ "NetworkRequestHoldingTime" SG_ 1096 Cluster_ModeSwSta 5000;
BA_ "Version" SG_ 1096 Cluster_ModeSwSta "21.07.05";
BA_ "GenSigSendType" SG_ 1096 Cluster_ScrlOkSwSta 4;
BA_ "UserSigValidity" SG_ 1096 Cluster_ScrlOkSwSta 0;
BA_REL_ "GenSigTimeoutTime" BU_SG_REL_ CGW_CCU SG_ 1096 Cluster_ScrlOkSwSta 1500;
BA_ "NetworkRequest" SG_ 1096 Cluster_ScrlOkSwSta 0;
BA_ "NetworkRequestHoldingTime" SG_ 1096 Cluster_ScrlOkSwSta 5000;
BA_ "Version" SG_ 1096 Cluster_ScrlOkSwSta "19.11.02";
BA_ "Description" SG_ 1096 Audio_CustomSwSta "Audio Custom switch MM-CAN Gateway needed";
BA_ "GenSigSendType" SG_ 1096 Audio_CustomSwSta 4;
BA_ "UserSigValidity" SG_ 1096 Audio_CustomSwSta 0;
BA_REL_ "GenSigTimeoutTime" BU_SG_REL_ CGW_CCU SG_ 1096 Audio_CustomSwSta 1500;
BA_ "NetworkRequest" SG_ 1096 Audio_CustomSwSta 0;
BA_ "NetworkRequestHoldingTime" SG_ 1096 Audio_CustomSwSta 5000;
BA_ "Version" SG_ 1096 Audio_CustomSwSta "21.07.05";
BA_ "Description" SG_ 1096 Cluster_ModeCCW "Cluster Menu Control (Back Key)";
BA_ "GenSigSendType" SG_ 1096 Cluster_ModeCCW 4;
BA_ "UserSigValidity" SG_ 1096 Cluster_ModeCCW 0;
BA_REL_ "GenSigTimeoutTime" BU_SG_REL_ CGW_CCU SG_ 1096 Cluster_ModeCCW 1500;
BA_ "NetworkRequest" SG_ 1096 Cluster_ModeCCW 0;
BA_ "NetworkRequestHoldingTime" SG_ 1096 Cluster_ModeCCW 5000;
BA_ "Version" SG_ 1096 Cluster_ModeCCW "21.07.05";
BA_ "Description" SG_ 1096 Cluster_TripDnSwSta "Cluster Menu Control(Down)

 - tumbler, button type";
BA_ "GenSigSendType" SG_ 1096 Cluster_TripDnSwSta 4;
BA_ "UserSigValidity" SG_ 1096 Cluster_TripDnSwSta 0;
BA_REL_ "GenSigTimeoutTime" BU_SG_REL_ CGW_CCU SG_ 1096 Cluster_TripDnSwSta 1500;
BA_ "NetworkRequest" SG_ 1096 Cluster_TripDnSwSta 0;
BA_ "NetworkRequestHoldingTime" SG_ 1096 Cluster_TripDnSwSta 5000;
BA_ "Version" SG_ 1096 Cluster_TripDnSwSta "19.11.02";
BA_ "Description" SG_ 1096 Cluster_TripUpSwSta "Cluster Menu Control(Up)

 - Tumbler, button type";
BA_ "GenSigSendType" SG_ 1096 Cluster_TripUpSwSta 4;
BA_ "UserSigValidity" SG_ 1096 Cluster_TripUpSwSta 0;
BA_REL_ "GenSigTimeoutTime" BU_SG_REL_ CGW_CCU SG_ 1096 Cluster_TripUpSwSta 1500;
BA_ "NetworkRequest" SG_ 1096 Cluster_TripUpSwSta 0;
BA_ "NetworkRequestHoldingTime" SG_ 1096 Cluster_TripUpSwSta 5000;
BA_ "Version" SG_ 1096 Cluster_TripUpSwSta "19.11.02";
BA_ "Description" SG_ 1096 Cluster_TripOkSwSta "Cluter Menu Control(OK)

 - tumbler, button type";
BA_ "GenSigSendType" SG_ 1096 Cluster_TripOkSwSta 4;
BA_ "UserSigValidity" SG_ 1096 Cluster_TripOkSwSta 0;
BA_REL_ "GenSigTimeoutTime" BU_SG_REL_ CGW_CCU SG_ 1096 Cluster_TripOkSwSta 1500;
BA_ "NetworkRequest" SG_ 1096 Cluster_TripOkSwSta 0;
BA_ "NetworkRequestHoldingTime" SG_ 1096 Cluster_TripOkSwSta 5000;
BA_ "Version" SG_ 1096 Cluster_TripOkSwSta "19.11.02";
BA_ "Description" SG_ 1096 SWRC_OpticalSwSnstvtSta "Current setting value for Optical Switch Sensitivity";
BA_ "GenSigSendType" SG_ 1096 SWRC_OpticalSwSnstvtSta 4;
BA_ "GenSigStartValue" SG_ 1096 SWRC_OpticalSwSnstvtSta 3;
BA_ "UserSigValidity" SG_ 1096 SWRC_OpticalSwSnstvtSta 0;
BA_REL_ "GenSigTimeoutTime" BU_SG_REL_ CGW_CCU SG_ 1096 SWRC_OpticalSwSnstvtSta 1500;
BA_ "Version" SG_ 1096 SWRC_OpticalSwSnstvtSta "19.12.00";
BA_ "GenSigSendType" SG_ 1096 SWRC_RhOpticalSwSta 4;
BA_ "UserSigValidity" SG_ 1096 SWRC_RhOpticalSwSta 0;
BA_REL_ "GenSigTimeoutTime" BU_SG_REL_ CGW_CCU SG_ 1096 SWRC_RhOpticalSwSta 1500;
BA_ "Version" SG_ 1096 SWRC_RhOpticalSwSta "19.11.02";
BA_ "Description" SG_ 1096 Audio_CustomSw3Sta "Audio Custom switch MM-CAN Gateway needed";
BA_ "GenSigSendType" SG_ 1096 Audio_CustomSw3Sta 4;
BA_ "UserSigValidity" SG_ 1096 Audio_CustomSw3Sta 0;
BA_REL_ "GenSigTimeoutTime" BU_SG_REL_ CGW_CCU SG_ 1096 Audio_CustomSw3Sta 1500;
BA_ "NetworkRequest" SG_ 1096 Audio_CustomSw3Sta 0;
BA_ "NetworkRequestHoldingTime" SG_ 1096 Audio_CustomSw3Sta 5000;
BA_ "Version" SG_ 1096 Audio_CustomSw3Sta "21.07.05";
BA_ "GenMsgSendType" BO_ 1099 0;
BA_ "Description" SG_ 1099 USM_CmdWPCSta "USM request value of WPC";
BA_ "GenSigSendType" SG_ 1099 USM_CmdWPCSta 4;
BA_ "UserSigValidity" SG_ 1099 USM_CmdWPCSta 0;
BA_REL_ "GenSigTimeoutTime" BU_SG_REL_ CGW_CCU SG_ 1099 USM_CmdWPCSta 1500;
BA_ "NetworkRequest" SG_ 1099 USM_CmdWPCSta 0;
BA_ "NetworkRequestHoldingTime" SG_ 1099 USM_CmdWPCSta 5000;
BA_ "Version" SG_ 1099 USM_CmdWPCSta "17.11.00";
BA_ "Description" SG_ 1099 WPC_SWVerMajor1 "Indicate the WPC software version as follows:

- The software version is displayed in three digits.

- The Major and Minor digits are separated by '.'

- Signal values are transmitted to ASCII codes.



¡Ø Example

WPC_SWVerMajor1 : 0x41 (HEX) -> ASCII CODE : 'A' 

WPC_SWVerMinor1 : 0x30 (HEX) -> ASCII CODE : '0'

WPC_SWVerMinor2 : 0x33 (HEX) -> ASCII CODE : '3'

=> WPC S/W Ver is displayed 'A.03'";
BA_ "GenSigSendType" SG_ 1099 WPC_SWVerMajor1 4;
BA_ "UserSigValidity" SG_ 1099 WPC_SWVerMajor1 0;
BA_REL_ "GenSigTimeoutTime" BU_SG_REL_ CGW_CCU SG_ 1099 WPC_SWVerMajor1 1500;
BA_ "Version" SG_ 1099 WPC_SWVerMajor1 "20.12.04";
BA_ "Description" SG_ 1099 WPC_PhnLftWrngSta "Warning by WPC for User (Phone left in vehicle)";
BA_ "GenSigSendType" SG_ 1099 WPC_PhnLftWrngSta 4;
BA_ "UserSigValidity" SG_ 1099 WPC_PhnLftWrngSta 0;
BA_REL_ "GenSigTimeoutTime" BU_SG_REL_ CGW_CCU SG_ 1099 WPC_PhnLftWrngSta 1500;
BA_ "NetworkRequest" SG_ 1099 WPC_PhnLftWrngSta 0;
BA_ "NetworkRequestHoldingTime" SG_ 1099 WPC_PhnLftWrngSta 5000;
BA_ "Version" SG_ 1099 WPC_PhnLftWrngSta "24.01.00";
BA_ "Description" SG_ 1099 WPC_SWVerMinor1 "Indicate the WPC software version as follows:

- The software version is displayed in three digits.

- The Major and Minor digits are separated by '.'

- Signal values are transmitted to ASCII codes.



¡Ø Example

WPC_SWVerMajor1 : 0x41 (HEX) -> ASCII CODE : 'A' 

WPC_SWVerMinor1 : 0x30 (HEX) -> ASCII CODE : '0'

WPC_SWVerMinor2 : 0x33 (HEX) -> ASCII CODE : '3'

=> WPC S/W Ver is displayed 'A.03'";
BA_ "GenSigSendType" SG_ 1099 WPC_SWVerMinor1 4;
BA_ "UserSigValidity" SG_ 1099 WPC_SWVerMinor1 0;
BA_REL_ "GenSigTimeoutTime" BU_SG_REL_ CGW_CCU SG_ 1099 WPC_SWVerMinor1 1500;
BA_ "Version" SG_ 1099 WPC_SWVerMinor1 "18.10.06";
BA_ "Description" SG_ 1099 WPC_SWVerMinor2 "Indicate the WPC software version as follows:

- The software version is displayed in three digits.

- The Major and Minor digits are separated by '.'

- Signal values are transmitted to ASCII codes.



¡Ø Example

WPC_SWVerMajor1 : 0x41 (HEX) -> ASCII CODE : 'A' 

WPC_SWVerMinor1 : 0x30 (HEX) -> ASCII CODE : '0'

WPC_SWVerMinor2 : 0x33 (HEX) -> ASCII CODE : '3'

=> WPC S/W Ver is displayed 'A.03'";
BA_ "GenSigSendType" SG_ 1099 WPC_SWVerMinor2 4;
BA_ "UserSigValidity" SG_ 1099 WPC_SWVerMinor2 0;
BA_REL_ "GenSigTimeoutTime" BU_SG_REL_ CGW_CCU SG_ 1099 WPC_SWVerMinor2 1500;
BA_ "Version" SG_ 1099 WPC_SWVerMinor2 "18.10.06";
BA_ "Description" SG_ 1099 WPC_IndSyncVal "WPC IND ANIMATION SYNC SIGANL";
BA_ "GenSigSendType" SG_ 1099 WPC_IndSyncVal 4;
BA_ "TimeoutValue" SG_ 1099 WPC_IndSyncVal "0x0";
BA_ "UserSigValidity" SG_ 1099 WPC_IndSyncVal 3;
BA_REL_ "GenSigTimeoutTime" BU_SG_REL_ RWPC SG_ 1099 WPC_IndSyncVal 1500;
BA_REL_ "GenSigTimeoutTime" BU_SG_REL_ WPC2 SG_ 1099 WPC_IndSyncVal 1500;
BA_ "Version" SG_ 1099 WPC_IndSyncVal "22.04.01";
BA_ "Description" SG_ 1099 USM_CmdWPCIndSta "WPC Indicator animation type USM";
BA_ "GenSigSendType" SG_ 1099 USM_CmdWPCIndSta 4;
BA_ "GenSigStartValue" SG_ 1099 USM_CmdWPCIndSta 2;
BA_ "UserSigValidity" SG_ 1099 USM_CmdWPCIndSta 0;
BA_REL_ "GenSigTimeoutTime" BU_SG_REL_ CGW_CCU SG_ 1099 USM_CmdWPCIndSta 1500;
BA_REL_ "GenSigTimeoutTime" BU_SG_REL_ RWPC SG_ 1099 USM_CmdWPCIndSta 1500;
BA_REL_ "GenSigTimeoutTime" BU_SG_REL_ WPC2 SG_ 1099 USM_CmdWPCIndSta 1500;
BA_ "NetworkRequest" SG_ 1099 USM_CmdWPCIndSta 0;
BA_ "NetworkRequestHoldingTime" SG_ 1099 USM_CmdWPCIndSta 5000;
BA_ "Version" SG_ 1099 USM_CmdWPCIndSta "22.05.02";
VAL_ 1133 APSU_AstStEsyAcsUSMSta 0 "Default Value" 1 "Off (Disable)" 2 "50mmOn (Enable)" 3 "75mmOn (Enable)" 4 "RESERVED" 5 "RESERVED" 6 "RESERVED" 7 "Invalid" ;
VAL_ 1133 APSU_AstReturnModeSta 0 "Default" 1 "Off" 2 "Stop" 3 "Moving" 4 "Finish" 5 "Invalid" ;
VAL_ 1133 APSU_CntryConfigTyp 0 "Dom" 1 "Na" 2 "Eu" 3 "Aus" 4 "China" 5 "Gen,Mes" 6 "India" 7 "RESERVED" 8 "RESERVED" 9 "RESERVED" 10 "RESERVED" 11 "RESERVED" 12 "RESERVED" 13 "RESERVED" 15 "Error Indicator" ;
VAL_ 1133 APSU_AutoHtrCtrlUSMSta 0 "Default" 1 "Off" 2 "On" 3 "Invalid" ;
VAL_ 1133 APSU_HtBlcUSMSta 0 "Default" 1 "Normal" 2 "Back 1" 3 "Back 2" 4 "Back 3" 5 "Cush 1" 6 "Cush 2" 7 "Cush 3" 8 "RESERVED" 9 "RESERVED" 10 "RESERVED" 11 "RESERVED" 12 "RESERVED" 13 "RESERVED" 14 "RESERVED" 15 "Invalid" ;
VAL_ 1133 APSU_AstAntPncMod 0 "Default" 1 "Off" 2 "On" 3 "Invalid" ;
VAL_ 1133 APSU_AstOneTchFldModSta 0 "Default" 1 "Off" 2 "Reclining FWD" 3 "Reclining BWD" 4 "Folding Mode" 5 "Unfolding Mode" 6 "RESERVED" 7 "Invalid" ;
VAL_ 1133 APSU_AstOneTchOperSta 0 "Default" 1 "Off" 2 "Ready" 3 "Move" 4 "Finished" 5 "RESERVED" 6 "RESERVED" 7 "Invalid" ;
VAL_ 1133 APSU_AstRelaxModeSta 0 "Default" 1 "Off" 2 "Stop" 3 "Moving" 4 "Finish" 5 "Invalid" ;
VAL_ 1134 APSU_AstStSldFwdDis 0 "default" 1 "off" 2 "on" 3 "invalid" ;
VAL_ 1134 APSU_AstStTiltDnDis 0 "default" 1 "off" 2 "on" 3 "invalid" ;
VAL_ 1134 APSU_AstStHghtUpDis 0 "default" 1 "off" 2 "on" 3 "invalid" ;
VAL_ 1134 APSU_AstStHghtDnDis 0 "default" 1 "off" 2 "on" 3 "invalid" ;
VAL_ 1134 APSU_AstStLegUpDis 0 "default" 1 "off" 2 "on" 3 "invalid" ;
VAL_ 1134 APSU_AstStLegtDnDis 0 "default" 1 "off" 2 "on" 3 "invalid" ;
VAL_ 1134 APSU_AstStSldBckwdDis 0 "default" 1 "off" 2 "on" 3 "invalid" ;
VAL_ 1134 APSU_AstStRlxTiltUpDis 0 "default" 1 "off" 2 "on" 3 "invalid" ;
VAL_ 1134 APSU_AstStRlxTiltDnDis 0 "default" 1 "off" 2 "on" 3 "invalid" ;
VAL_ 1134 APSU_AstStCushExtBckwdDis 0 "default" 1 "off" 2 "on" 3 "invalid" ;
VAL_ 1134 APSU_AstStCushExtFwdDis 0 "default" 1 "off" 2 "on" 3 "invalid" ;
VAL_ 1134 APSU_AstStLmbrDefDis 0 "default" 1 "off" 2 "on" 3 "invalid" ;
VAL_ 1134 APSU_AstStLmbrLoDis 0 "default" 1 "off" 2 "on" 3 "invalid" ;
VAL_ 1134 APSU_AstStLmbrMdlDis 0 "default" 1 "off" 2 "on" 3 "invalid" ;
VAL_ 1134 APSU_AstStLmbrUpDis 0 "default" 1 "off" 2 "on" 3 "invalid" ;
VAL_ 1134 APSU_AstStReclneFwdDis 0 "default" 1 "off" 2 "on" 3 "invalid" ;
VAL_ 1134 APSU_LmbrSigSrcTyp 0 "not APSU" 1 "APSU" 2 "RESERVED" 3 "invalid" ;
VAL_ 1134 APSU_APSUOpt 0 "Default" 1 "Non-APSU" 2 "APSU" 3 "Invalid" ;
VAL_ 1134 APSU_AstStReclneBckwdDis 0 "default" 1 "off" 2 "on" 3 "invalid" ;
VAL_ 1134 APSU_AstStTiltUpDis 0 "default" 1 "off" 2 "on" 3 "invalid" ;
VAL_ 1115 ARS_OnOffSta 0 "Off" 1 "On" 2 "reserved" 3 "Invalid" ;
VAL_ 1115 ARS_RrCurtainSwSta 0 "off" 1 "on" 2 "Not Used" 3 "Error Indicator" ;
VAL_ 1115 ARS_RrLftStRetModSwSta 0 "off" 1 "short return" 2 "long return" 3 "invalid" ;
VAL_ 1115 ARS_RrLftStRlxModSwSta 0 "off" 1 "on" 2 "Not Used" 3 "Error Indicator" ;
VAL_ 1115 ARS_RtMonModSwSta 0 "off" 1 "on" 2 "Not Used" 3 "Error Indicator" ;
VAL_ 1115 ARS_RtReadModSwSta 0 "off" 1 "on" 2 "Not Used" 3 "Error Indicator" ;
VAL_ 1115 ARS_ReclneBckwdSwSta 0 "Off" 1 "On" 2 "Not Used" 3 "Error Indicator" ;
VAL_ 1115 ARS_RtRetModSwSta 0 "off" 1 "short return" 2 "long return" 3 "invalid" ;
VAL_ 1115 ARS_RtRlxModSwSta 0 "off" 1 "on" 2 "Not Used" 3 "Error Indicator" ;
VAL_ 1115 ARS_SwLkSta 0 "Lock" 1 "UNLock" 2 "Not Used" 3 "Error Indicator" ;
VAL_ 1115 ARS_WalkInFrSwSta 0 "off" 1 "on" 2 "Not Used" 3 "Error Indicator" ;
VAL_ 1115 ARS_WalkInRrSwSta 0 "off" 1 "on" 2 "Not Used" 3 "Error Indicator" ;
VAL_ 1115 Lamp_RrRtPrsLmpReq 0 "off" 1 "on" 2 "Not Used" 3 "Error Indicator" ;
VAL_ 1115 PSM_ApsmPlyBckRrerReq 0 "None" 1 "Return" 2 "Monitor" ;
VAL_ 1115 ARS_ReclneFwdSwSta 0 "Off" 1 "On" 2 "Not Used" 3 "Error Indicator" ;
VAL_ 1115 ARS_RlxFrSwSta 0 "Off" 1 "On" 2 "Not Used" 3 "Error Indicator" ;
VAL_ 1115 ARS_RlxRrSwSta 0 "Off" 1 "On" 2 "Not Used" 3 "Error Indicator" ;
VAL_ 1116 PSM_BzrOnReq 0 "off" 1 "on" 2 "Not Used" 3 "Error Indicator" ;
VAL_ 1116 PSM_RrRtStMvSta 0 "None" 1 "Relax" 2 "Return" 3 "Monitor" 4 "Table" 15 "Invalid" ;
VAL_ 1116 PSM_AsstStCushHghtDnReq 0 "Off" 1 "On" 2 "Not Used" 3 "Error Indicator" ;
VAL_ 1116 PSM_AsstStCushHghtUpReq 0 "Off" 1 "On" 2 "Not Used" 3 "Error Indicator" ;
VAL_ 1116 PSM_LegDnSwSta 0 "Off" 1 "On" 2 "Not Used" 3 "Error Indicator" ;
VAL_ 1116 PSM_AsstStHdRstDnReq 0 "Off" 1 "On" 2 "Not Used" 3 "Error Indicator" ;
VAL_ 1116 PSM_AsstStHdRstUpReq 0 "Off" 1 "On" 2 "Not Used" 3 "Error Indicator" ;
VAL_ 1116 PSM_AsstStReclneBckwdReq 0 "Off" 1 "On" 2 "Not Used" 3 "Error Indicator" ;
VAL_ 1116 PSM_AsstStReclneFwdReq 0 "Off" 1 "On" 2 "Not Used" 3 "Error Indicator" ;
VAL_ 1116 PSM_AsstStSldBckwdReq 0 "Off" 1 "On" 2 "Not Used" 3 "Error Indicator" ;
VAL_ 1116 PSM_AsstStSldFwdReq 0 "Off" 1 "On" 2 "Not Used" 3 "Error Indicator" ;
VAL_ 1116 ARS_RR_ActiveSw 0 "Default" 1 "Off" 2 "On" 3 "Invalid" ;
VAL_ 1116 ARS_RL_ActiveSw 0 "Default" 1 "Off" 2 "On" 3 "Invalid" ;
VAL_ 1116 PSM_LegUpSwSta 0 "Off" 1 "On" 2 "Not Used" 3 "Error Indicator" ;
VAL_ 1116 PSM_RrLftStSldPosVal 0 "0¡Âx¡Â50" 1 "50<x¡Â100" 2 "reserved" 3 "Invalid" ;
VAL_ 1116 PSM_RrRtStMvFnshSta 0 "None" 1 "Relax finish" 2 "Return finish" 3 "Monitor finish" 4 "Table finish" 15 "Invalid" ;
VAL_ 1117 PSM_RrLftHdRstBckwdReq 0 "off" 1 "on" 2 "Not Used" 3 "Error Indicator" ;
VAL_ 1117 PSM_RrLftStCushTiltUpReq 0 "off" 1 "on" 2 "Not Used" 3 "Error Indicator" ;
VAL_ 1117 PSM_RrLftStShldrBckwdReq 0 "off" 1 "on" 2 "Not Used" 3 "Error Indicator" ;
VAL_ 1117 PSM_RrLftStShldrFwdReq 0 "off" 1 "on" 2 "Not Used" 3 "Error Indicator" ;
VAL_ 1117 PSM_RrLftStSldBckwdReq 0 "off" 1 "on" 2 "Not Used" 3 "Error Indicator" ;
VAL_ 1117 PSM_RrLftStSldFwdReq 0 "off" 1 "on" 2 "Not Used" 3 "Error Indicator" ;
VAL_ 1117 PSM_RrLftHdRstDnReq 0 "off" 1 "on" 2 "Not Used" 3 "Error Indicator" ;
VAL_ 1117 PSM_RrRtStCushTiltDnReq 0 "off" 1 "on" 2 "Not Used" 3 "Error Indicator" ;
VAL_ 1117 PSM_RrRtStCushTiltUpReq 0 "off" 1 "on" 2 "Not Used" 3 "Error Indicator" ;
VAL_ 1117 PSM_RrRtStHdRstBckwdReq 0 "off" 1 "on" 2 "Not Used" 3 "Error Indicator" ;
VAL_ 1117 PSM_RrRtStHdRstDnReq 0 "off" 1 "on" 2 "Not Used" 3 "Error Indicator" ;
VAL_ 1117 PSM_RrRtStHdRstFwdReq 0 "off" 1 "on" 2 "Not Used" 3 "Error Indicator" ;
VAL_ 1117 PSM_RrRtStHdRstUpReq 0 "off" 1 "on" 2 "Not Used" 3 "Error Indicator" ;
VAL_ 1117 PSM_RrRtStLegSpprtBckwdReq 0 "off" 1 "on" 2 "Not Used" 3 "Error Indicator" ;
VAL_ 1117 PSM_RrRtStLegSpprtDnReq 0 "off" 1 "on" 2 "Not Used" 3 "Error Indicator" ;
VAL_ 1117 PSM_RrRtStLegSpprtFwdReq 0 "off" 1 "on" 2 "Not Used" 3 "Error Indicator" ;
VAL_ 1117 PSM_RrRtStLegSpprtUpReq 0 "off" 1 "on" 2 "Not Used" 3 "Error Indicator" ;
VAL_ 1117 PSM_RrLftHdRstFwdReq 0 "off" 1 "on" 2 "Not Used" 3 "Error Indicator" ;
VAL_ 1117 PSM_RrRtStShldrBckwdReq 0 "off" 1 "on" 2 "Not Used" 3 "Error Indicator" ;
VAL_ 1117 PSM_RrRtStShldrFwdReq 0 "off" 1 "on" 2 "Not Used" 3 "Error Indicator" ;
VAL_ 1117 PSM_RrRtStSldBckwdReq 0 "off" 1 "on" 2 "Not Used" 3 "Error Indicator" ;
VAL_ 1117 PSM_RrRtStSldFwdReq 0 "off" 1 "on" 2 "Not Used" 3 "Error Indicator" ;
VAL_ 1117 PSM_StSldBckwdArsSta 0 "off" 1 "on" 2 "Not Used" 3 "Error Indicator" ;
VAL_ 1117 PSM_StSldFwdArsSta 0 "off" 1 "on" 2 "Not Used" 3 "Error Indicator" ;
VAL_ 1117 ARS_RrHeaterSW 0 "Default" 1 "Off" 2 "On" 3 "Invalid" ;
VAL_ 1117 ARS_RlHeaterSW 0 "Default" 1 "Off" 2 "On" 3 "Invalid" ;
VAL_ 1117 ARS_RrVentSW 0 "Default" 1 "Off" 2 "On" 3 "Invalid" ;
VAL_ 1117 ARS_RlVentSW 0 "Default" 1 "Off" 2 "On" 3 "Invalid" ;
VAL_ 1117 PSM_RrLftHdRstUpReq 0 "off" 1 "on" 2 "Not Used" 3 "Error Indicator" ;
VAL_ 1117 PSM_RrLftStCushTiltDnReq 0 "off" 1 "on" 2 "Not Used" 3 "Error Indicator" ;
VAL_ 1095 ATS_BeepSound 0 "Off" 1 "On" 2 "Reserved" 3 "Invalid" ;
VAL_ 1095 ATS_RRMsgTimeSW 0 "Default" 1 "Short" 2 "Medium" 3 "Long" 4 "Reserved" 5 "Reserved" 6 "Reserved" 7 "Invalid" ;
VAL_ 1095 ATS_FAUMsgModeSW 0 "Default" 1 "Off" 2 "On" 3 "Invalid" ;
VAL_ 1095 ATS_FAUMsgHeatModeSW 0 "Default" 1 "Off" 2 "On" 3 "Invalid" ;
VAL_ 1095 ATS_RLMsgMod1SW 0 "Default" 1 "Short On" 2 "Long On" 3 "Invalid" ;
VAL_ 1095 ATS_RWPC_RWPCNValueSet 0 "Default" 1 "Off" 2 "On" 3 "Invalid" ;
VAL_ 1095 ATS_RLMsgMod2SW 0 "Default" 1 "Short On" 2 "Long On" 3 "Invalid" ;
VAL_ 1095 ATS_RLMsgMod3SW 0 "Default" 1 "Short On" 2 "Long On" 3 "Invalid" ;
VAL_ 1095 ATS_RLMsgMod4SW 0 "Default" 1 "Short On" 2 "Long On" 3 "Invalid" ;
VAL_ 1095 ATS_RRMsgMod1SW 0 "Default" 1 "Short On" 2 "Long On" 3 "Invalid" ;
VAL_ 1095 ATS_RRMsgMod2SW 0 "Default" 1 "Short On" 2 "Long On" 3 "Invalid" ;
VAL_ 1095 ATS_RRMsgMod3SW 0 "Default" 1 "Short On" 2 "Long On" 3 "Invalid" ;
VAL_ 1095 ATS_RRMsgMod4SW 0 "Default" 1 "Short On" 2 "Long On" 3 "Invalid" ;
VAL_ 1095 ATS_RLEasyAccessSW 0 "Default" 1 "Off" 2 "On" 3 "Invalid" ;
VAL_ 1095 ATS_RREasyAccessSW 0 "Default" 1 "Off" 2 "On" 3 "Invalid" ;
VAL_ 1095 ATS_RLMsgTimeSW 0 "Default" 1 "Short" 2 "Medium" 3 "Long" 4 "Reserved" 5 "Reserved" 6 "Reserved" 7 "Invalid" ;
VAL_ 1090 BCM_Crc12Val 0 "0x0x0~0xFF:CRCValue" 255 "0x0x0~0xFF:CRCValue" ;
VAL_ 1090 BCM_AlvCnt12Val 0 "AlvCntValue" 1 "AlvCntValue" 2 "AlvCntValue" 3 "AlvCntValue" 4 "AlvCntValue" 5 "AlvCntValue" 6 "AlvCntValue" 7 "AlvCntValue" 8 "AlvCntValue" 9 "AlvCntValue" 10 "AlvCntValue" 11 "AlvCntValue" 12 "AlvCntValue" 13 "AlvCntValue" 14 "AlvCntValue" 15 "AlvCntValue" ;
VAL_ 1090 BCM_SmkOptTyp 0 "Non SMK Option" 1 "SMK Option" 2 "Not Used" 3 "Error Indicator" ;
VAL_ 1090 PHEV_FuelDrOpnSta 0 "Close" 1 "Open" 2 "Not Used" 3 "Error Indicator" ;
VAL_ 1090 BCM_SunRoofOptTyp 0 "NONE" 1 "Sunroof applied" 2 "reserved" 3 "Invalid" ;
VAL_ 1090 Window_DrvrSdWdwSta_BCM 0 "Window Close" 1 "Window Open" 2 "Not Used" 3 "Error Indicator" ;
VAL_ 1090 Window_AsstSdWdwSta_BCM 0 "Window Close" 1 "Window Open" 2 "Not Used" 3 "Error Indicator" ;
VAL_ 1090 Window_RrLftWdwSta_BCM 0 "Window Close" 1 "Window Open" 2 "Not Used" 3 "Error Indicator" ;
VAL_ 1090 Window_RrRtWdwSta_BCM 0 "Window Close" 1 "Window Open" 2 "Not Used" 3 "Error Indicator" ;
VAL_ 1090 SunRoof_GlassPosSta 0 "Glass Tilt up" 1 "Glass Vent area" 2 "Glass Anti pinch in vent" 3 "Glass Fully close" 4 "Glass Anti pinch in partially slide" 5 "Glass Partially slide" 6 "Glass Fully open" 7 "Glass Uninitialized" 8 "Reserved" 9 "Reserved" 10 "Reserved" 11 "Reserved" 12 "Reserved" 13 "Reserved" 14 "Reserved" 15 "invalid" ;
VAL_ 1090 PHEV_FuelDrDis 0 "Off" 1 "Fuel Door Open Wait" 2 "Refueling Ready(Fuel Door Open)" 3 "Check Fuel Door" 4 "Charging" 5 "Fuel Door Not Open" 6 "Not Used" 7 "Error Indicator" ;
VAL_ 1090 SunRoof_BlindPosSta 0 "BLIND_HALF_OPEN" 1 "BLIND_LESS_THEN_HALF_OPEN" 2 "BLIND_ANTIPINCH_LESS_THAN_HALF_OPEN" 3 "BLIND_FULLY_CLOSE" 4 "BLIND_ANTIPINCH_MORE_THAN_HALF_OPEN" 5 "BLIND_MORE_THAN_HALF_OPEN" 6 "BLIND_FULLY_OPEN" 7 "BLIND_UNINITIALIZED" 8 "Reserved" 9 "Reserved" 10 "Reserved" 11 "Reserved" 12 "Reserved" 13 "Reserved" 14 "Reserved" 15 "invalid" ;
VAL_ 1090 SunRoof_GlassErrSta 0 "Glass No error" 1 "Glass Thermal Protection Active" 2 "Glass Initialized Status" 3 "Glass Undefined ECU Error" 4 "Glass Switch Error" 5 "Glass Voltage error" 6 "Complex Error" 7 "invalid" ;
VAL_ 1090 SunRoof_BlindErrSta 0 "Roll Blind No error" 1 "Roll Blind Thermal Protection Active" 2 "Roll Blind Initialized Status" 3 "Roll Blind Undefined ECU Error" 4 "Roll Blind Switch Error" 5 "Roll Blind Voltage error" 6 "Complex Error" 7 "invalid" ;
VAL_ 1097 BCM_Crc13Val 0 "0x0x0~0xFF:CRCValue" 255 "0x0x0~0xFF:CRCValue" ;
VAL_ 1097 BCM_AlvCnt13Val 0 "AlvCntValue" 1 "AlvCntValue" 2 "AlvCntValue" 3 "AlvCntValue" 4 "AlvCntValue" 5 "AlvCntValue" 6 "AlvCntValue" 7 "AlvCntValue" 8 "AlvCntValue" 9 "AlvCntValue" 10 "AlvCntValue" 11 "AlvCntValue" 12 "AlvCntValue" 13 "AlvCntValue" 14 "AlvCntValue" 15 "AlvCntValue" ;
VAL_ 1097 StrWhlWrmr_HtngCmd 0 "Off" 1 "1 Step On" 2 "2 Step On" 3 "Error Indicator" ;
VAL_ 1097 StrWhlWrmr_HtngReqState 0 "Off" 1 "ManualOn" 2 "MKBDOn" 3 "VoiceOn" 4 "CCSOn" 5 "DATCOn" 6 "DATCToNormalOn" 7 "Not Used" 8 "Not Used" 9 "Not Used" 10 "Not Used" 11 "Not Used" 12 "Not Used" 13 "Not Used" 14 "Not Used" 15 "Error Indicator" ;
VAL_ 1097 StrWhlWrmr_IndCmd 0 "Off" 1 "1 Step On" 2 "2 Step On" 3 "Error Indicator" ;
VAL_ 1097 PHEV_FuelDrCtrlFlag 0 "Default (Fuel Door Open Control Not Running)" 1 "Fuel Door Open Control Running" 2 "Not Used" 3 "Error Indicator" ;
VAL_ 1097 Haptic_USMCurState_OnOff 0 "Default" 1 "On" 2 "Off" 3 "Error Indicator" ;
VAL_ 1097 Haptic_ADASAutoOnSetReq 0 "Default" 1 "Active" 2 "Not Used" 3 "Error Indicator" ;
VAL_ 1097 HeatedSteerWheel_StrWhlHtrSwSta_BCM 0 "Off" 1 "On" 2 "Not Used" 3 "Error Indicator" ;
VAL_ 1097 Haptic_WrngCmd 0 "Off" 1 "On" 2 "Not Used" 3 "Error Indicator" ;
VAL_ 2202063617 CCU_AP_OTA_Crc4Val 0 "0x0x0~0xFFFF:CRCValue" 65535 "0x0x0~0xFFFF:CRCValue" ;
VAL_ 2202063617 CCU_AP_OTA_AlvCnt4Val 0 "0x0x0~0xFF:AlvCntValue" 255 "0x0x0~0xFF:AlvCntValue" ;
VAL_ 2202063617 CCU_OTA_Update_time 0 "Default" 1 "0x0001~0xFFFF:update time" 65535 "0x0001~0xFFFF:update time" ;
VAL_ 2202063617 CCU_OTA_Update_Current 0 "Default" 1 "0x0001~0xFFFF:current" 65535 "0x0001~0xFFFF:current" ;
VAL_ 2202063617 CCU_Update_Calfactor 0 "Default" 1 "Target SOC" 2 "Target SOC" 3 "Target SOC" 4 "Target SOC" 5 "Target SOC" 6 "Target SOC" 7 "Target SOC" 8 "Target SOC" 9 "Target SOC" 10 "Target SOC" 11 "Target SOC" 12 "Target SOC" 13 "Target SOC" 14 "Target SOC" 15 "Target SOC" 16 "Target SOC" 17 "Target SOC" 18 "Target SOC" 19 "Target SOC" 20 "Target SOC" 21 "Target SOC" 22 "Target SOC" 23 "Target SOC" 24 "Target SOC" 25 "Target SOC" 26 "Target SOC" 27 "Target SOC" 28 "Target SOC" 29 "Target SOC" 30 "Target SOC" 31 "Target SOC" 32 "Target SOC" 33 "Target SOC" 34 "Target SOC" 35 "Target SOC" 36 "Target SOC" 37 "Target SOC" 38 "Target SOC" 39 "Target SOC" 40 "Target SOC" 41 "Target SOC" 42 "Target SOC" 43 "Target SOC" 44 "Target SOC" 45 "Target SOC" 46 "Target SOC" 47 "Target SOC" 48 "Target SOC" 49 "Target SOC" 50 "Target SOC" 51 "Target SOC" 52 "Target SOC" 53 "Target SOC" 54 "Target SOC" 55 "Target SOC" 56 "Target SOC" 57 "Target SOC" 58 "Target SOC" 59 "Target SOC" 60 "Target SOC" 61 "Target SOC" 62 "Target SOC" 63 "Target SOC" 64 "Target SOC" 65 "Target SOC" 66 "Target SOC" 67 "Target SOC" 68 "Target SOC" 69 "Target SOC" 70 "Target SOC" 71 "Target SOC" 72 "Target SOC" 73 "Target SOC" 74 "Target SOC" 75 "Target SOC" 76 "Target SOC" 77 "Target SOC" 78 "Target SOC" 79 "Target SOC" 80 "Target SOC" 81 "Target SOC" 82 "Target SOC" 83 "Target SOC" 84 "Target SOC" 85 "Target SOC" 86 "Target SOC" 87 "Target SOC" 88 "Target SOC" 89 "Target SOC" 90 "Target SOC" 91 "Target SOC" 92 "Target SOC" 93 "Target SOC" 94 "Target SOC" 95 "Target SOC" 96 "Target SOC" 97 "Target SOC" 98 "Target SOC" 99 "Target SOC" 100 "Target SOC" 101 "0x65~0xFF:Reserved" 255 "0x65~0xFF:Reserved" ;
VAL_ 1132 DLBCU_CushInfDis 0 "default" 1 "off" 2 "on" 3 "invalid" ;
VAL_ 1132 DLBCU_CushDefDis 0 "default" 1 "off" 2 "on" 3 "invalid" ;
VAL_ 1105 FCS_FrLftStClrSwSta 0 "Default" 1 "Off" 2 "On" 3 "Error Indicator" ;
VAL_ 1105 HeatedSteerWheel_SwSta 0 "Default" 1 "Off" 2 "On" 3 "Error Indicator" ;
VAL_ 1105 FCS_DrvDrAtClsSwSta 0 "Default" 1 "OFF" 2 "ON" 3 "Error Indicator" ;
VAL_ 1105 FCS_AstDrAtClsSwSta 0 "Default" 1 "Off" 2 "On" 3 "Error Indicator" ;
VAL_ 1105 FCS_DrvModeSwSta 0 "Default" 1 "Off" 2 "On" 3 "Error Indicator" ;
VAL_ 1105 FCS_PDWSwSta 0 "Default" 1 "Off" 2 "On" 3 "Error Indicator" ;
VAL_ 1105 FCS_FrLftStHtrSwSta 0 "Default" 1 "Off" 2 "On" 3 "Error Indicator" ;
VAL_ 1105 FCS_Beep1Sound 0 "Default" 1 "Off" 2 "On" 3 "Error Indicator" ;
VAL_ 1105 FCS_LockTrayMsgDisp 0 "Default" 1 "Message Initial Pw Set" 2 "Message Pw 2nd Input" 3 "Message Pw Re-Input" 4 "Message Pw Input" 5 "Message Pw Error" 6 "Message Current Pw" 7 "Message Reset Pw" 10 "Reserved" 11 "Reserved" 12 "Reserved" 13 "Reserved" 14 "Reserved" 15 "Invalid" ;
VAL_ 1105 FCS_LockTrayStatDisp 0 "Default" 1 "Pw Set" 2 "Tray Lock" 3 "Tray Unlock" 4 "Pw Reset" 5 "Reserved" 6 "Reserved" 7 "Invalid" ;
VAL_ 1105 FCS_LockTrayPwNoDisp 0 "Default" 1 "Pw 1st Number" 2 "Pw 2nd Number" 3 "Pw 3rd Number" 4 "Pw 4th Number" 5 "Reserved" 6 "Reserved" 7 "Invalid" ;
VAL_ 1105 FCS_LockTrayTxtPopupReq 0 "Off" 1 "TEXT POP-UP Request On" 2 "Reserved" 3 "Error Indicator" ;
VAL_ 1105 FCS_LockTrayOSD 0 "Default" 1 "Message Pw Saved" 2 "Message Tray Lock" 3 "Message Tray Unlock" 4 "Message Pw Changed" 5 "Message Pw Reset" 6 "Message Tray Error" 7 "Invalid" ;
VAL_ 1105 FCS_FrDrvArmrestHeatedLvl 0 "Off" 1 "Low" 2 "Mid" 3 "High" ;
VAL_ 1105 FCS_FrAstArmrestHeatedLvl 0 "Off" 1 "Low" 2 "Mid" 3 "High" ;
VAL_ 1105 FCS_FrRtStClrSwSta 0 "Default" 1 "Off" 2 "On" 3 "Error Indicator" ;
VAL_ 1105 FCS_FrArmrestHeatedTyp 0 "Default" 1 "FrArmrestHeatedTyp" 2 "Not ArmrestHeated" 3 "Invalid" ;
VAL_ 1105 FCS_RrArmrestHeatedTyp 0 "Default" 1 "RrArmrestHeatedTyp" 2 "Not ArmrestHeated" 3 "Invalid" ;
VAL_ 1105 FCS_RrLhArmrestHeatedLvl 0 "Off" 1 "Low" 2 "Mid" 3 "High" ;
VAL_ 1105 FCS_DrvTerrModeDirSwSta 0 "Default" 1 "Control(-)" 2 "Control(+)" 3 "Invalid" ;
VAL_ 1105 FCS_DrvTerrModeSwSta 0 "Default" 1 "Push" 2 "Invalid" 3 "RESERVED" ;
VAL_ 1105 CF_FCS_4wdLocking 0 "Default" 1 "Off" 2 "On" 3 "Invalid" ;
VAL_ 1105 FCS_FrDrvArmrestHeated 0 "Default" 1 "Off" 2 "On" 3 "Invalid" ;
VAL_ 1105 FCS_FrAstArmrestHeated 0 "Default" 1 "Off" 2 "On" 3 "Invalid" ;
VAL_ 1105 FCS_RrLhArmrestHeated 0 "Default" 1 "Off" 2 "On" 3 "Invalid" ;
VAL_ 1105 FCS_RrRhArmrestHeated 0 "Default" 1 "Off" 2 "On" 3 "Invalid" ;
VAL_ 1105 FCS_FrRtStHtrSwSta 0 "Default" 1 "Off" 2 "On" 3 "Error Indicator" ;
VAL_ 1105 FCS_RrRhArmrestHeatedLvl 0 "Off" 1 "Low" 2 "Mid" 3 "High" ;
VAL_ 1105 FCS_RrCurtainSwSta 0 "Default" 1 "Off" 2 "On" 3 "Error Indicator" ;
VAL_ 1113 C_LH_Folding_State_PopUp 0 "Default" 1 "Folded (Finished)" 2 "Unfolded (Finished)" 3 "Mode-Fail (Anti-Pinch)" 4 "Mode-Fail (TGS & Break Condition)" 5 "Mode-Fail (System Error)" 6 "Mode-Fail(Vehicle Speed Warning)" 7 "Invalid" ;
VAL_ 1113 PFSU_RLLnkRtnStop 0 "Default" 1 "Return Stop" 2 "Return Fail" 3 "Invalid" ;
VAL_ 1113 PFSU_RLStStdPosMovReq_Fold 0 "Default" 1 "ON" 2 "Reserved" 3 "Invalid" ;
VAL_ 1113 PFSU_3RAMPBzrReq 0 "Off" 1 "On" 2 "Not Used" 3 "Error Indicator" ;
VAL_ 1113 PFSU_3LAMPBzrReq 0 "Off" 1 "On" 2 "Not Used" 3 "Error Indicator" ;
VAL_ 1113 C_RH_Folding_State_PopUp_2 0 "Default" 1 "2nd Seat Moving" 2 "2nd Seat RePositioning" 3 "RESERVED" 4 "RESERVED" 5 "RESERVED" 6 "RESERVED" 7 "Invalid" ;
VAL_ 1113 C_LH_Folding_State_PopUp_2 0 "Default" 1 "2nd Seat Moving" 2 "2nd Seat RePositioning" 3 "RESERVED" 4 "RESERVED" 5 "RESERVED" 6 "RESERVED" 7 "Invalid" ;
VAL_ 1113 C_RH_Folding_State_PopUp 0 "Default" 1 "Folded (Finish)" 2 "UnFolded (Finish)" 3 "Mode-Fail (Anti-Pinch)" 4 "Mode-Fail (TGS & Break Condition)" 5 "Mode-Fail (System Error)" 6 "Mode-Fail(Vehicle Speed Warning)" 7 "Invalid" ;
VAL_ 1113 PFSU_RRLnkRtnStop 0 "Default" 1 "Return Stop" 2 "Return Fail" 3 "Invalid" ;
VAL_ 1113 PFSU_RRStStdPosMovReq_Fold 0 "Default" 1 "ON" 2 "Reserved" 3 "Invalid" ;
VAL_ 1111 C_LH_Folding_Position 0 "Default" 1 "Folded" 2 "UnFolded" 3 "Folding (Moving)" 4 "UnFolding (Moving)" 5 "Unknown" 6 "RESERVED" 7 "Invalid" ;
VAL_ 1111 PFSU_RH_ReclMtrPos 0 "Default" 1 "Zone1" 2 "Zone2" 3 "Invalid" ;
VAL_ 1111 PFSU_RL_Folding_SW 0 "Default" 1 "OFF" 2 "ON" 3 "Invalid" ;
VAL_ 1111 PFSU_RR_Folding_SW 0 "Default" 1 "OFF" 2 "ON" 3 "Invalid" ;
VAL_ 1111 PFSU_RL_Unfolding_SW 0 "Default" 1 "OFF" 2 "ON" 3 "Invalid" ;
VAL_ 1111 PFSU_RR_Unfolding_SW 0 "Default" 1 "OFF" 2 "ON" 3 "Invalid" ;
VAL_ 1111 C_RH_Folding_Position 0 "Default" 1 "Folded" 2 "UnFolded" 3 "Folding (Moving)" 4 "UnFolding (Moving)" 5 "Unknown" 6 "RESERVED" 7 "Invalid" ;
VAL_ 1111 PFSU_RR_FoldingDis 0 "default" 1 "Off" 2 "On" 3 "Invalid" ;
VAL_ 1111 PFSU_RR_UnfoldingDis 0 "default" 1 "Off" 2 "On" 3 "Invalid" ;
VAL_ 1111 PFSU_RL_FoldingDis 0 "default" 1 "Off" 2 "On" 3 "Invalid" ;
VAL_ 1111 PFSU_RL_UnfoldingDis 0 "default" 1 "Off" 2 "On" 3 "Invalid" ;
VAL_ 1111 PFSU_RR_HrstFoldingDis 0 "default" 1 "Off" 2 "On" 3 "Invalid" ;
VAL_ 1111 PFSU_RL_HrstFoldingDis 0 "default" 1 "Off" 2 "On" 3 "Invalid" ;
VAL_ 1111 PFSU_RR_SlideFwdDis 0 "default" 1 "Off" 2 "On" 3 "Invalid" ;
VAL_ 1111 PFSU_RR_SlidBwdDis 0 "default" 1 "Off" 2 "On" 3 "Invalid" ;
VAL_ 1111 PFSU_RL_SlideFwdDis 0 "default" 1 "Off" 2 "On" 3 "Invalid" ;
VAL_ 1111 PFSU_RL_SlideBwdDis 0 "default" 1 "Off" 2 "On" 3 "Invalid" ;
VAL_ 1111 PFSU_RRAutoRlxEnable 0 "Default" 1 "Enable" 2 "Disable" 3 "Invalid" ;
VAL_ 1111 PFSU_Opt 0 "default" 1 "PFSU" 2 "RESERVED" 3 "Invalid" ;
VAL_ 1111 PFSU_RLAutoRlxEnable 0 "Default" 1 "Enable" 2 "Disable" 3 "Invalid" ;
VAL_ 1111 PFSU_LH_ReclMtrPos 0 "Default" 1 "Zone1" 2 "Zone2" 3 "Invalid" ;
VAL_ 1089 PSM_RrRtSldStrtSta 0 "OFF" 1 "ON(SLIDE START)" 2 "STOP" 3 "FINISH" ;
VAL_ 1089 RRPSM_APSMBzrOnReq 0 "off" 1 "on (1)" 2 "on (2)" 3 "reserved" ;
VAL_ 1089 RRPSM_SeatTyp 0 "Default" 1 "SEDAN" 2 "LIMOUSINE" 3 "Ivalid" ;
VAL_ 1089 RRPSM_RRStEsyAcsUSMSta 0 "Default" 1 "Off" 2 "On" 3 "Invalid" ;
VAL_ 1089 RRPSM_RRSlidePosition 0 "0x0x00~0xFE:POSITION" 254 "0x0x00~0xFE:POSITION" 255 "invalid" ;
VAL_ 1089 RRPSM_SeatPosPlyBck_Sta 0 "Default" 1 "Moving" 2 "Moving Finish" 3 "Moving not Finish" 4 "Not Used" 5 "Not Used" 6 "Stop" 7 "Not Used" ;
VAL_ 1089 RRPSM_SeatPos_Sta 0 "Default" 1 "Memory1" 2 "Memory2" 3 "Memory3" 4 "Not Used" 5 "Not Used" 6 "Not Used" 7 "Any Postion" ;
VAL_ 1089 RRPSM_SeatPosSldLmt_Sta 0 "Default" 1 "Slide Fwd Limit" 2 "Slide Bwd Limit" 3 "Not Initialized" ;
VAL_ 1089 RRPSM_RearModeState 0 "Default" 1 "Off" 2 "Relax Mode" 3 "Relax Mode(rear only)" 4 "Return Mode" 5 "Monitor Mode" 6 "Reading Mode" 7 "Finished" 8 "Return Mode(rear only)" 9 "RESERVED" 10 "RESERVED" 11 "RESERVED" 12 "RESERVED" 13 "RESERVED" 14 "RESERVED" 15 "Invalid" ;
VAL_ 1089 RRPSM_RRLegRestPosition 0 "0x0x00~0xFE:POSITION" 254 "0x0x00~0xFE:POSITION" 255 "invalid" ;
VAL_ 1107 RR_SHVU_SeatOptSta 0 "Init" 1 "Heater only 2step" 2 "Heater only 3step" 3 "Vent only 2step" 4 "Vent only 3step" 5 "Heater and Vent 2step" 6 "Heater and Vent 3step" 7 "Invalid" ;
VAL_ 1107 RR_SHVU_SeatHtOperSta 0 "Init" 1 "RESERVED" 2 "Heater & Vent OFF" 3 "Vent Low" 4 "Vent Mid" 5 "Vent High" 6 "Heater Low" 7 "Heater Mid" 8 "Heater High" 9 "RESERVED" 10 "RESERVED" 11 "RESERVED" 12 "RESERVED" 13 "RESERVED" 14 "RESERVED" 15 "Invalid" ;
VAL_ 1094 SLB_PlyBckSta 0 "Stop" 1 "Play 1" 2 "Play 2" 3 "Invalid" ;
VAL_ 1092 SMK_Crc2Val 0 "0x0x0~0xFF:CRCValue" 255 "0x0x0~0xFF:CRCValue" ;
VAL_ 1092 SMK_AlvCnt2Val 0 "AlvCntValue" 1 "AlvCntValue" 2 "AlvCntValue" 3 "AlvCntValue" 4 "AlvCntValue" 5 "AlvCntValue" 6 "AlvCntValue" 7 "AlvCntValue" 8 "AlvCntValue" 9 "AlvCntValue" 10 "AlvCntValue" 11 "AlvCntValue" 12 "AlvCntValue" 13 "AlvCntValue" 14 "AlvCntValue" 15 "AlvCntValue" ;
VAL_ 1092 SSB_StrtStpBtnSw1Sta 0 "Released" 1 "Pressed" 2 "Not Used" 3 "Error Indicator" ;
VAL_ 1092 SSB_StrtStpBtnSw2Sta 0 "Released" 1 "Pressed" 2 "Not Used" 3 "Error Indicator" ;
VAL_ 1092 SMK_TrmnlCtrlSta 0 "Off" 1 "ACC" 2 "IGN" 3 "START" 4 "Reserved/" 5 "Reseved" 6 "Reseved" 7 "Reserved" 8 "Reserved" 9 "Reserved" 10 "Reserved" 11 "Reserved" 12 "Reserved" 13 "Reserved" 14 "Not Used" 15 "Error Indicator" ;
VAL_ 1092 SMK_AuthSta 0 "No Auth" 1 "Preauthentication" 2 "Authentication" 3 "Fast Restart" 4 "Reserved" 5 "Reseved" 6 "Not Used" 7 "Error Indicator" ;
VAL_ 1092 SMK_Ign1InSta 0 "IGN1 Off" 1 "IGN1 On" 2 "Not Used" 3 "Error Indicator" ;
VAL_ 1092 SMK_Ign1RlySta 0 "Off" 1 "On" 2 "Not Used" 3 "Error Indicator" ;
VAL_ 1092 SMK_Ign2InSta 0 "IGN2 Off" 1 "IGN2 On" 2 "Not Used" 3 "Error Indicator" ;
VAL_ 1092 SMK_Ign2RlySta 0 "Off" 1 "On" 2 "Not Used" 3 "Error Indicator" ;
VAL_ 1092 SMK_StrtFdbckSta 0 "Off" 1 "On" 2 "Not Used" 3 "Error Indicator" ;
VAL_ 1092 SMK_StrtrRlyOutSta 0 "Starter Relay Output Off" 1 "Starter Relay Output On" 2 "Not Used" 3 "Error Indicator" ;
VAL_ 1092 SMK_AccInSta 0 "ACC OFF" 1 "ACC ON" 2 "Not Used" 3 "Error Indicator" ;
VAL_ 1092 SMK_AccRlySta 0 "Off" 1 "On" 2 "Not Used" 3 "Error Indicator" ;
VAL_ 1092 SMK_CLUAccIndOnReq 0 "Cluster ACC Indicator Off" 1 "Cluster ACC Indicator On" 2 "Not Used" 3 "Error Indicator" ;
VAL_ 1092 SMK_VDModeActSta 0 "Off" 1 "On" 2 "Not Used" 3 "Error Indicator" ;
VAL_ 1092 SMK_SCULckUnlckSta 0 "Default" 1 "Lock" 2 "Unlock" 3 "Error Indicator" ;
VAL_ 1092 SMK_TlEngRunSta 0 "Off" 1 "Tele Engine Running" 2 "Not Used" 3 "Error Indicator" ;
VAL_ 1092 SMK_TlCrnkModSta 0 "Normal Mode" 1 "Tele Cranking Mode" 2 "Not Used" 3 "Error Indicator" ;
VAL_ 1092 SMK_RmtKeyEngRunSta 0 "Off" 1 "Remote Key Engine Running" 2 "Not Used" 3 "Error Indicator" ;
VAL_ 1092 SMK_RmtKeyCrnkModSta 0 "Normal Mode" 1 "Remote Key Cranking Mode" 2 "Not Used" 3 "Error Indicator" ;
VAL_ 1093 SMK_Crc6Val 0 "0x0x0~0xFF:CRCValue" 255 "0x0x0~0xFF:CRCValue" ;
VAL_ 1093 SMK_AlvCnt6Val 0 "AlvCntValue" 1 "AlvCntValue" 2 "AlvCntValue" 3 "AlvCntValue" 4 "AlvCntValue" 5 "AlvCntValue" 6 "AlvCntValue" 7 "AlvCntValue" 8 "AlvCntValue" 9 "AlvCntValue" 10 "AlvCntValue" 11 "AlvCntValue" 12 "AlvCntValue" 13 "AlvCntValue" 14 "AlvCntValue" 15 "AlvCntValue" ;
VAL_ 1093 Lamp_HzrdBlnkngSta 0 "Off" 1 "Single Blinking" 2 "Double Blinking" 3 "Reserved" 4 "Reserved" 5 "Reseved" 6 "Not Used" 7 "Error Indicator" ;
VAL_ 1093 RSPA_LearntSta 0 "Non-RSPA Learnt" 1 "RSPA Learnt" 2 "Reserved" 3 "Error Indicator" ;
VAL_ 1093 Lamp_SmrtWlcmLtOnReq 0 "Off" 1 "On" 2 "Not Used" 3 "Error Indicator" ;
VAL_ 1093 Fob_BattStaInfo 0 "Normal or No Information" 1 "Recent used FOB is in discharge warning voltage level" 2 "Not Used" 3 "Error Indicator" ;
VAL_ 1093 Fob_FoundDrvWlcmArea 0 "Default" 1 "Fob Found(Drv)" 2 "Not Used" 3 "Error Indicator" ;
VAL_ 1093 Fob_FoundAsstWlcmArea 0 "Default" 1 "Fob Found(Ast)" 2 "Not Used" 3 "Error Indicator" ;
VAL_ 1093 Fob_FoundExtrnlArea 0 "Default" 1 "Can't recognize" 2 "Fob recognized" 3 "Search in progress" ;
VAL_ 1093 Fob_FoundIntArea 0 "Default" 1 "Can't recognize" 2 "Fob recognized" 3 "Search in progress" ;
VAL_ 1093 Fob_LearntSta 0 "Learnt" 1 "Virgin" 2 "Not Used" 3 "Error Indicator" ;
VAL_ 1093 RSPA_RFSigErrSta 0 "Default" 1 "Signal Invalid" 2 "In Progress" 3 "Error Indicator" ;
VAL_ 1093 RSPA_CanErrSta 0 "Default" 1 "RSPA CAN Error" 2 "Not Used" 3 "Error Indicator" ;
VAL_ 1093 LFAnt_FltSta 0 "Normal" 1 "Fault" 2 "Not Used" 3 "Error Indicator" ;
VAL_ 1093 LFAnt_SrchSta 0 "Off" 1 "On (LF Searching)" 2 "Not Used" 3 "Error Indicator" ;
VAL_ 1093 Auth_ISKLearnSta 0 "Default(Normal)" 1 "Learning" 2 "Invalid" 3 "Neutral" 4 "Reserved" 5 "Reserved" 6 "Not used" 7 "Error Indicator" ;
VAL_ 1093 RSPA_ModSta_SMK 0 "RSPA Off" 1 "RSPA On" 2 "Reserved" 3 "Reserved" 4 "Reserved" 5 "Reseved" 6 "Not Used" 7 "Error Indicator" ;
VAL_ 1093 RSPA_FobBattSta 0 "Normal" 1 "Low Battery" 2 "Reserved" 3 "Reserved" 4 "Reserved" 5 "Reseved" 6 "Not Used" 7 "Error Indicator" ;
VAL_ 1093 Fob_BtnReleasedSta 0 "Default" 1 "Butten Released" 2 "Not used" 3 "Error Indicator" ;
VAL_ 1093 USM_SmrtTrnkTlgtModSta 0 "Default Value" 1 "HandsFree Off" 2 "HandsFree On" 3 "Reserved" 4 "Invalid" 5 "Reserved" 6 "Not Used" 7 "Error Indicator" ;
VAL_ 1093 USM_WALModSta 0 "Default" 1 "WAL Off" 2 "WAL On" 3 "Invalid" 4 "Reserved" 5 "Reseved" 6 "Not Used" 7 "Error Indicator" ;
VAL_ 1093 Fob_FoundWlcmArea 0 "Default (Off)" 1 "Fob Found" 2 "Not Used" 3 "Error Indicator" ;
VAL_ 1096 SWRC_Crc1Val 0 "0x0x0~0xFF:CRCValue" 255 "0x0x0~0xFF:CRCValue" ;
VAL_ 1096 SWRC_AlvCnt1Val 0 "AlvCntValue" 1 "AlvCntValue" 2 "AlvCntValue" 3 "AlvCntValue" 4 "AlvCntValue" 5 "AlvCntValue" 6 "AlvCntValue" 7 "AlvCntValue" 8 "AlvCntValue" 9 "AlvCntValue" 10 "AlvCntValue" 11 "AlvCntValue" 12 "AlvCntValue" 13 "AlvCntValue" 14 "AlvCntValue" 15 "AlvCntValue" ;
VAL_ 1096 Audio_VcRecSwSta 0 "Off" 1 "Key On" 2 "RESERVED" 3 "Invalid" ;
VAL_ 1096 Audio_BluetoothPhnClSwSta 0 "Off" 1 "Key On" 2 "RESERVED" 3 "Invalid" ;
VAL_ 1096 Audio_BluetoothPhnHangUpSwSta 0 "Off" 1 "Key On" 2 "Reserved" 3 "Invalid" ;
VAL_ 1096 Audio_ModSwSta 0 "Off" 1 "Key On" 2 "RESERVED" 3 "Invalid" ;
VAL_ 1096 Audio_MutSwSta 0 "Off" 1 "Key On" 2 "Reserved" 3 "Invalid" ;
VAL_ 1096 Audio_SeekDnSwSta 0 "Off" 1 "Key On" 2 "Reserved" 3 "Invalid" ;
VAL_ 1096 Audio_SeekUpSwSta 0 "Off" 1 "Key On" 2 "Reserved" 3 "Invalid" ;
VAL_ 1096 Audio_VolDnSwSta 0 "Off" 1 "Key On" 2 "Reserved" 3 "Invalid" ;
VAL_ 1096 Audio_VolUpSwSta 0 "Off" 1 "Key On" 2 "Reserved" 3 "Invalid" ;
VAL_ 1096 Cluster_ModeSwSta 0 "Off" 1 "Key On" 2 "RESERVED" 3 "Invalid" ;
VAL_ 1096 Cluster_ScrlOkSwSta 0 "Off" 1 "Key On" 2 "Reserved" 3 "Invalid" ;
VAL_ 1096 Audio_CustomSwSta 0 "Off" 1 "Key On" 2 "RESERVED" 3 "Invalid" ;
VAL_ 1096 Cluster_ModeCCW 0 "Off" 1 "Key On" 2 "RESERVED" 3 "Invalid" ;
VAL_ 1096 Cluster_TripDnSwSta 0 "Off" 1 "Key On" 2 "Reserved" 3 "Invalid" ;
VAL_ 1096 Cluster_TripUpSwSta 0 "Off" 1 "Key On" 2 "Reserved" 3 "Invalid" ;
VAL_ 1096 Cluster_TripOkSwSta 0 "Off" 1 "Key On" 2 "Reserved" 3 "Invalid" ;
VAL_ 1096 SWRC_OpticalSwSnstvtSta 0 "Medium(default)" 1 "Low" 2 "High" 3 "Invalid" ;
VAL_ 1096 SWRC_RhOpticalSwSta 0 "Off" 1 "Swipe Up" 2 "Swipe Down" 3 "Swipe Left" 4 "Swipe Right" 5 "Swipe Fast Up" 6 "Swipe Fast Down" 7 "Swipe Fast Left" 8 "Swipe Fast Right" 9 "Drag Up" 10 "Drag Down" 11 "Drag Left" 12 "Drag Right" 13 "Touch" 14 "OK" 15 "Invalid" ;
VAL_ 1096 Audio_CustomSw3Sta 0 "Off" 1 "Key On" 2 "RESERVED" 3 "Invalid" ;
VAL_ 1099 USM_CmdWPCSta 0 "Default" 1 "Off(Disable)" 2 "On(Enable)" 3 "Invalid" ;
VAL_ 1099 WPC_SWVerMajor1 0 "0x0x0~0x7F:ASCII Code Value (HEX)" 127 "0x0x0~0x7F:ASCII Code Value (HEX)" ;
VAL_ 1099 WPC_PhnLftWrngSta 0 "Off" 1 "Cellphone on the pad" 2 "Charging" 3 "Charging complete" 4 "Cellphone reminder" 5 "Error" 6 "NFC Card detected" 7 "Invalid" ;
VAL_ 1099 WPC_SWVerMinor1 0 "0x0x0~0x7F:ASCII Code Value (HEX)" 127 "0x0x0~0x7F:ASCII Code Value (HEX)" ;
VAL_ 1099 WPC_SWVerMinor2 0 "0x0x0~0x7F:ASCII Code Value (HEX)" 127 "0x0x0~0x7F:ASCII Code Value (HEX)" ;
VAL_ 1099 WPC_IndSyncVal 0 "default" 1 "off" 2 "1st sync" 3 "2nd sync" 4 "3rd sync" 5 "error off" 6 "error on" 7 "reserved" ;
VAL_ 1099 USM_CmdWPCIndSta 0 "Default" 1 "Type 1 (Animation Off)" 2 "Type 2 (Animation On)" 3 "RESERVED" 4 "RESERVED" 5 "RESERVED" 6 "RESERVED" 7 "Invalid" ;
